VERSION ""

NS_ :

BS_:

BU_: PowertrainControlModule AtmosphericSensor SafetyRestraintSystem2 Aftertreatment_2_GasOutlet Aftertreatment_2_GasIntake DieselParticulateFilterControl Turbocharger SafetyRestraintSystem1 CabDisplay2 Aftertreatment_1_GasOutlet Aftertreatment_1_GasIntake OnBoardDataLogger OffBoardDiagnosticTool2 OffBoardDiagnosticTool1 FileServer ParkingBrakeController SeatController2 FanDriveController SteeringColumnUnit CommunicationUnitRadio CommunicationUnitSatellite CommunicationUnitCellular PropulsionBatteryCharger ChassisController2 ChassisController1 EngineValveControl AuxiliaryHeater2 AuxiliaryHeater1 ClutchUnit RampControl InformationSystem1 SuspensionSystemController2 OilSensor VehicleDynamicStability ExhaustEmissionController TransmissionDisplay2 TransmissionDisplay1 ClimateControl2 WaterPumpController RearAxleSteeringController LightingOperatorControl SeatController1 IgnitionController2 IgnitionController1 TirePressureController CabController2 CabController1 PneumaticSystemController SuspensionSystemController1 HydraulicPumpController EnduranceBrakingSystem RetarderExhaustEngine2 OnBoardDiagnosticUnit HeadwayController RetarderExhaustEngine1 CabDisplay1 ManagementComputer VirtualTerminal OffVehicleGateway PowerTakeOffFront HitchControl AuxiliaryValveControl BodyController TractorTrailerBridge1 StarterSystem ElectricalSystem VehicleSecurity VehicleNavigation AerodynamicControl ElectricalChargingSystem ClimateControl1 TripRecorder InstrumentCluster SuspensionDriveAxle2 SuspensionDriveAxle1 SuspensionSteerAxle SteeringController FuelSystem CruiseControl RetarderDriveline RetarderEngine BrakesDriveAxle2 BrakesDriveAxle1 BrakesSystemController BrakesSteerAxle AxleDrive2 AxleDrive1 AxleSteering PowerTakeOff ShiftConsoleSecondary ShiftConsolePrimary Transmission2 Transmission1 Engine2 Engine1

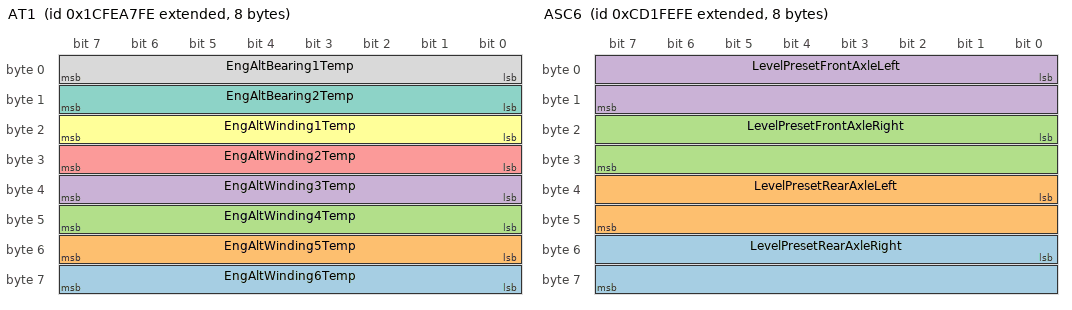
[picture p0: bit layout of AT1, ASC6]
BO_ 2633934846 AT1: 8 Vector__XXX
 SG_ EngAltWinding6Temp : 56|8@1+ (1,-40) [-40|210] "°C" Vector__XXX
 SG_ EngAltWinding5Temp : 48|8@1+ (1,-40) [-40|210] "°C" Vector__XXX
 SG_ EngAltWinding4Temp : 40|8@1+ (1,-40) [-40|210] "°C" Vector__XXX
 SG_ EngAltWinding3Temp : 32|8@1+ (1,-40) [-40|210] "°C" Vector__XXX
 SG_ EngAltWinding2Temp : 24|8@1+ (1,-40) [-40|210] "°C" Vector__XXX
 SG_ EngAltWinding1Temp : 16|8@1+ (1,-40) [-40|210] "°C" Vector__XXX
 SG_ EngAltBearing2Temp : 8|8@1+ (1,-40) [-40|210] "°C" Vector__XXX
 SG_ EngAltBearing1Temp : 0|8@1+ (1,-40) [-40|210] "°C" Vector__XXX

BO_ 2362572542 ASC6: 8 Vector__XXX
 SG_ LevelPresetRearAxleRight : 48|16@1+ (0.1,-3200) [-3200|3225.5] "mm" Vector__XXX
 SG_ LevelPresetRearAxleLeft : 32|16@1+ (0.1,-3200) [-3200|3225.5] "mm" Vector__XXX
 SG_ LevelPresetFrontAxleRight : 16|16@1+ (0.1,-3200) [-3200|3225.5] "mm" Vector__XXX
 SG_ LevelPresetFrontAxleLeft : 0|16@1+ (0.1,-3200) [-3200|3225.5] "mm" Vector__XXX

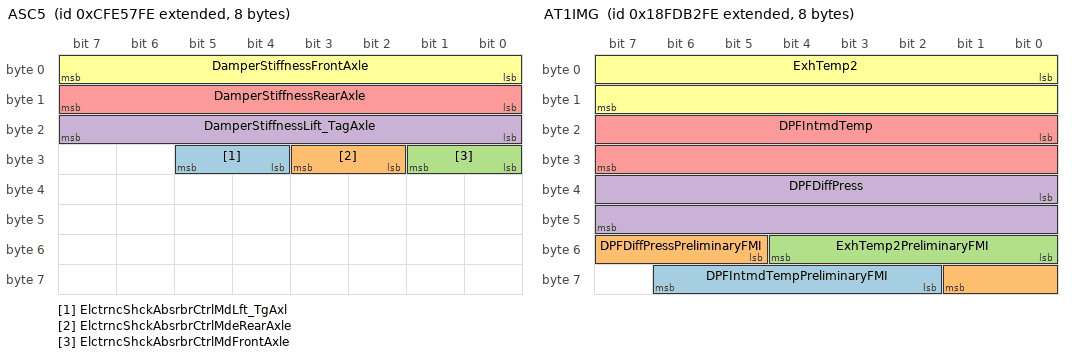
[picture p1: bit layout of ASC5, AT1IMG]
BO_ 2365478910 ASC5: 8 Vector__XXX
 SG_ ElctrncShckAbsrbrCtrlMdLft_TgAxl : 28|2@1+ (1,0) [0|3] "" Vector__XXX
 SG_ ElctrncShckAbsrbrCtrlMdeRearAxle : 26|2@1+ (1,0) [0|3] "" Vector__XXX
 SG_ ElctrncShckAbsrbrCtrlMdFrontAxle : 24|2@1+ (1,0) [0|3] "" Vector__XXX
 SG_ DamperStiffnessLift_TagAxle : 16|8@1+ (0.4,0) [0|100] "%" Vector__XXX
 SG_ DamperStiffnessRearAxle : 8|8@1+ (0.4,0) [0|100] "%" Vector__XXX
 SG_ DamperStiffnessFrontAxle : 0|8@1+ (0.4,0) [0|100] "%" Vector__XXX

BO_ 2560950014 DM30: 12 Vector__XXX
 SG_ SPN1 : 8|16@1+ (1,0) [0|65536] "" Vector__XXX
 SG_ TestLimitMinimum : 80|16@1+ (1,0) [0|64255] "" Vector__XXX
 SG_ FailureModeIdentifier1 : 24|5@1+ (1,0) [0|0] "" Vector__XXX
 SG_ TestLimitMaximum : 64|16@1+ (1,0) [0|64255] "" Vector__XXX
 SG_ TestValue : 48|16@1+ (1,0) [0|64255] "" Vector__XXX
 SG_ SlotId : 32|16@1+ (1,0) [0|64255] "" Vector__XXX
 SG_ TestIdentifier : 0|8@1+ (1,0) [0|255] "" Vector__XXX
 SG_ SPN1High : 29|3@1+ (1,0) [0|7] "" Vector__XXX

BO_ 2566763262 AT1IMG: 8 Vector__XXX
 SG_ DPFIntmdTempPreliminaryFMI : 58|5@1+ (1,0) [0|31] "" Vector__XXX
 SG_ DPFDiffPressPreliminaryFMI : 53|5@1+ (1,0) [0|31] "" Vector__XXX
 SG_ ExhTemp2PreliminaryFMI : 48|5@1+ (1,0) [0|31] "" Vector__XXX
 SG_ DPFDiffPress : 32|16@1+ (0.1,0) [0|6425.5] "kPa" Vector__XXX
 SG_ DPFIntmdTemp : 16|16@1+ (0.03125,-273) [-273|1734.96875] "°C" Vector__XXX
 SG_ ExhTemp2 : 0|16@1+ (0.03125,-273) [-273|1734.96875] "°C" Vector__XXX

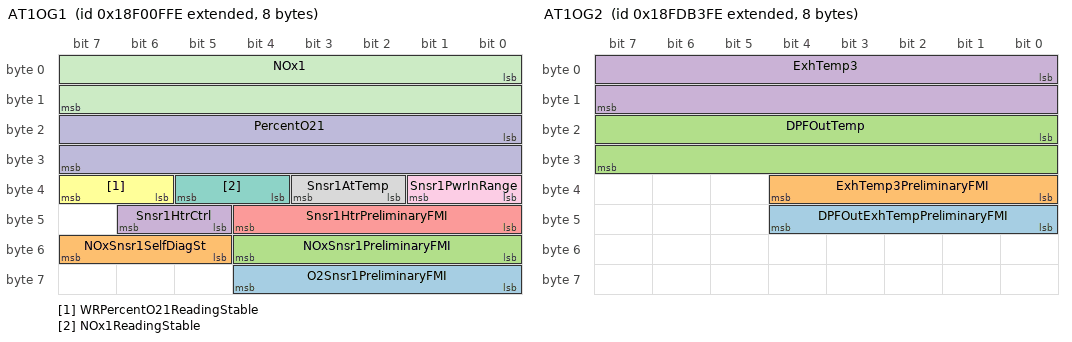
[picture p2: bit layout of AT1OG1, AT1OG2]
BO_ 2565869566 AT1OG1: 8 Vector__XXX
 SG_ O2Snsr1PreliminaryFMI : 56|5@1+ (1,0) [0|31] "" Vector__XXX
 SG_ NOxSnsr1SelfDiagSt : 53|3@1+ (1,0) [0|7] "" Vector__XXX
 SG_ NOxSnsr1PreliminaryFMI : 48|5@1+ (1,0) [0|31] "" Vector__XXX
 SG_ Snsr1HtrCtrl : 45|2@1+ (1,0) [0|3] "" Vector__XXX
 SG_ Snsr1HtrPreliminaryFMI : 40|5@1+ (1,0) [0|31] "" Vector__XXX
 SG_ WRPercentO21ReadingStable : 38|2@1+ (1,0) [0|3] "" Vector__XXX
 SG_ NOx1ReadingStable : 36|2@1+ (1,0) [0|3] "" Vector__XXX
 SG_ Snsr1AtTemp : 34|2@1+ (1,0) [0|3] "" Vector__XXX
 SG_ Snsr1PwrInRange : 32|2@1+ (1,0) [0|3] "" Vector__XXX
 SG_ PercentO21 : 16|16@1+ (0.000514,-12) [-12|21.02707] "%" Vector__XXX
 SG_ NOx1 : 0|16@1+ (0.05,-200) [-200|3012.75] "ppm" Vector__XXX

BO_ 2566763518 AT1OG2: 8 Vector__XXX
 SG_ DPFOutExhTempPreliminaryFMI : 40|5@1+ (1,0) [0|31] "" Vector__XXX
 SG_ ExhTemp3PreliminaryFMI : 32|5@1+ (1,0) [0|31] "" Vector__XXX
 SG_ DPFOutTemp : 16|16@1+ (0.03125,-273) [-273|1734.96875] "°C" Vector__XXX
 SG_ ExhTemp3 : 0|16@1+ (0.03125,-273) [-273|1734.96875] "°C" Vector__XXX

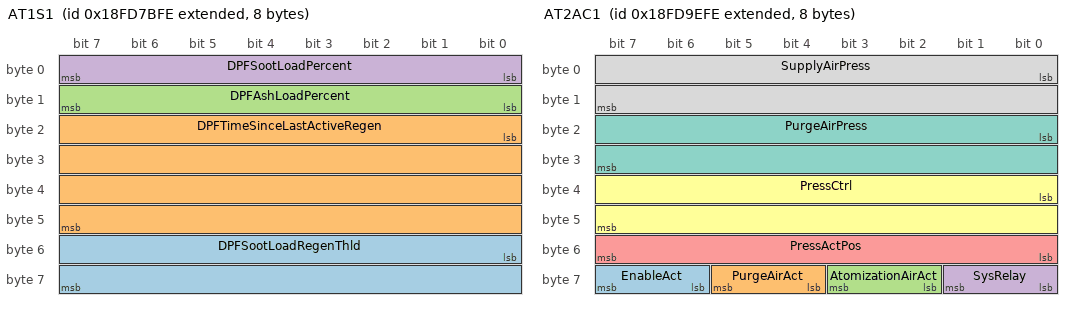
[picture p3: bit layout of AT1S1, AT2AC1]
BO_ 2566749182 AT1S1: 8 Vector__XXX
 SG_ DPFSootLoadRegenThld : 48|16@1+ (0.0025,0) [0|160.6375] "%" Vector__XXX
 SG_ DPFTimeSinceLastActiveRegen : 16|32@1+ (1,0) [0|4211081215] "s" Vector__XXX
 SG_ DPFAshLoadPercent : 8|8@1+ (1,0) [0|250] "%" Vector__XXX
 SG_ DPFSootLoadPercent : 0|8@1+ (1,0) [0|250] "%" Vector__XXX

BO_ 2566748670 AT1TI: 32 Vector__XXX
 SG_ DPFTripNumOfActiveRegenManReq : 224|32@1+ (1,0) [0|4211081215] "" Vector__XXX
 SG_ DPFTripNumOfActiveRegenInhReq : 192|32@1+ (1,0) [0|4211081215] "" Vector__XXX
 SG_ DPFTripNumOfPassiveRegens : 160|32@1+ (1,0) [0|4211081215] "" Vector__XXX
 SG_ DPFTripPassiveRegenTime : 128|32@1+ (1,0) [0|4211081215] "s" Vector__XXX
 SG_ DPFTripNumOfActiveRegens : 96|32@1+ (1,0) [0|4211081215] "" Vector__XXX
 SG_ DPFTripDisabledTime : 64|32@1+ (1,0) [0|4211081215] "s" Vector__XXX
 SG_ DPFTripActiveRegenTime : 32|32@1+ (1,0) [0|4211081215] "s" Vector__XXX
 SG_ DPFTripFuelUsed : 0|32@1+ (0.5,0) [0|2105540607.5] "l" Vector__XXX

BO_ 2566758142 AT2AC1: 8 Vector__XXX
 SG_ EnableAct : 62|2@1+ (1,0) [0|3] "" Vector__XXX
 SG_ PurgeAirAct : 60|2@1+ (1,0) [0|3] "" Vector__XXX
 SG_ AtomizationAirAct : 58|2@1+ (1,0) [0|3] "" Vector__XXX
 SG_ SysRelay : 56|2@1+ (1,0) [0|3] "" Vector__XXX
 SG_ PressActPos : 48|8@1+ (0.4,0) [0|100] "%" Vector__XXX
 SG_ PressCtrl : 32|16@1+ (0.0025,0) [0|160.6375] "%" Vector__XXX
 SG_ PurgeAirPress : 16|16@1+ (0.1,0) [0|6425.5] "kPa" Vector__XXX
 SG_ SupplyAirPress : 0|16@1+ (0.1,0) [0|6425.5] "kPa" Vector__XXX

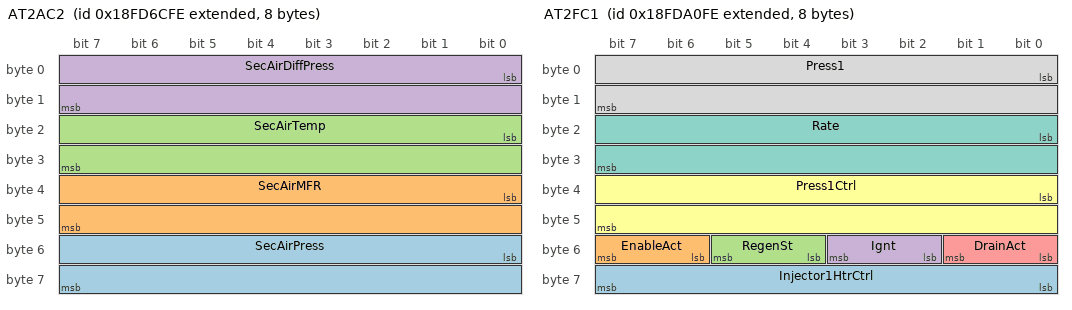
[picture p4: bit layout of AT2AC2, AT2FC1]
BO_ 2566745342 AT2AC2: 8 Vector__XXX
 SG_ SecAirPress : 48|16@1+ (0.1,0) [0|6425.5] "kPa" Vector__XXX
 SG_ SecAirMFR : 32|16@1+ (0.2,0) [0|12851] "kg/h" Vector__XXX
 SG_ SecAirTemp : 16|16@1+ (0.03125,-273) [-273|1734.96875] "°C" Vector__XXX
 SG_ SecAirDiffPress : 0|16@1+ (0.0078125,-250) [-250|251.9921875] "kPa" Vector__XXX

BO_ 2566758654 AT2FC1: 8 Vector__XXX
 SG_ Injector1HtrCtrl : 56|8@1+ (0.4,0) [0|100] "%" Vector__XXX
 SG_ EnableAct : 54|2@1+ (1,0) [0|3] "" Vector__XXX
 SG_ RegenSt : 52|2@1+ (1,0) [0|3] "" Vector__XXX
 SG_ Ignt : 50|2@1+ (1,0) [0|3] "" Vector__XXX
 SG_ DrainAct : 48|2@1+ (1,0) [0|3] "" Vector__XXX
 SG_ Press1Ctrl : 32|16@1+ (0.0025,0) [0|160.6375] "%" Vector__XXX
 SG_ Rate : 16|16@1+ (0.05,0) [0|3212.75] "l/h" Vector__XXX
 SG_ Press1 : 0|16@1+ (0.1,0) [0|6425.5] "kPa" Vector__XXX

BO_ 2566753278 AT2GP: 8 Vector__XXX
 SG_ DPFOutPress : 16|16@1+ (0.1,0) [0|6425.5] "kPa" Vector__XXX
 SG_ DPFInPress : 0|16@1+ (0.1,0) [0|6425.5] "kPa" Vector__XXX

BO_ 2566756862 AT2HI1: 40 Vector__XXX
 SG_ DPFAvgDistBetweenActiveRegens : 288|32@1+ (0.125,0) [0|526385151.875] "km" Vector__XXX
 SG_ DPFAvgTimeBetweenActiveRegens : 256|32@1+ (1,0) [0|4211081215] "s" Vector__XXX
 SG_ DPFTotalNumOfActiveRegenManReq : 224|32@1+ (1,0) [0|4211081215] "" Vector__XXX
 SG_ DPFTotalNumOfActiveRegenInhReq : 192|32@1+ (1,0) [0|4211081215] "" Vector__XXX
 SG_ DPFTotalNumOfPassiveRegens : 160|32@1+ (1,0) [0|4211081215] "" Vector__XXX
 SG_ DPFTotalPassiveRegenTime : 128|32@1+ (1,0) [0|4211081215] "s" Vector__XXX
 SG_ TotalNumOfActiveRegens : 96|32@1+ (1,0) [0|4211081215] "" Vector__XXX
 SG_ TotalDisabledTime : 64|32@1+ (1,0) [0|4211081215] "s" Vector__XXX
 SG_ TotalRegenTime : 32|32@1+ (1,0) [0|4211081215] "s" Vector__XXX
 SG_ TotalFuelUsed : 0|32@1+ (0.5,0) [0|2105540607.5] "l" Vector__XXX

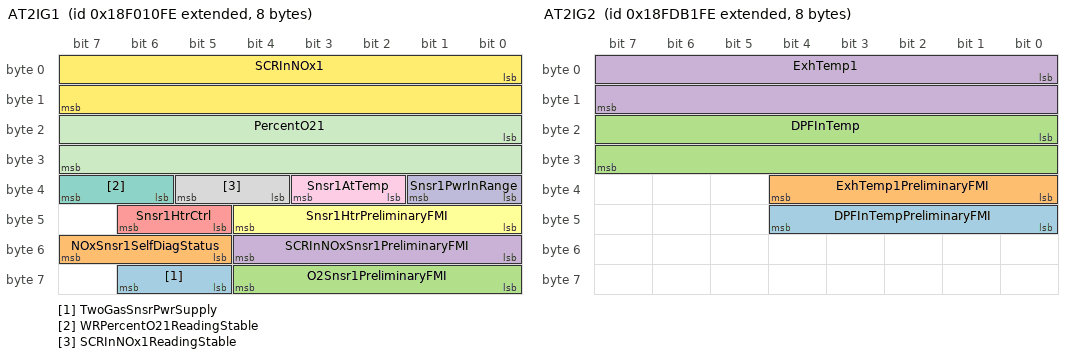
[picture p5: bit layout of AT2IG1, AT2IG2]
BO_ 2565869822 AT2IG1: 8 Vector__XXX
 SG_ TwoGasSnsrPwrSupply : 61|2@1+ (1,0) [0|3] "" Vector__XXX
 SG_ NOxSnsr1SelfDiagStatus : 53|3@1+ (1,0) [0|7] "" Vector__XXX
 SG_ O2Snsr1PreliminaryFMI : 56|5@1+ (1,0) [0|31] "" Vector__XXX
 SG_ SCRInNOxSnsr1PreliminaryFMI : 48|5@1+ (1,0) [0|31] "" Vector__XXX
 SG_ Snsr1HtrCtrl : 45|2@1+ (1,0) [0|3] "" Vector__XXX
 SG_ Snsr1HtrPreliminaryFMI : 40|5@1+ (1,0) [0|31] "" Vector__XXX
 SG_ WRPercentO21ReadingStable : 38|2@1+ (1,0) [0|3] "" Vector__XXX
 SG_ SCRInNOx1ReadingStable : 36|2@1+ (1,0) [0|3] "" Vector__XXX
 SG_ Snsr1AtTemp : 34|2@1+ (1,0) [0|3] "" Vector__XXX
 SG_ Snsr1PwrInRange : 32|2@1+ (1,0) [0|3] "" Vector__XXX
 SG_ PercentO21 : 16|16@1+ (0.000514,-12) [-12|21.02707] "%" Vector__XXX
 SG_ SCRInNOx1 : 0|16@1+ (0.05,-200) [-200|3012.75] "ppm" Vector__XXX

BO_ 2566763006 AT2IG2: 8 Vector__XXX
 SG_ DPFInTempPreliminaryFMI : 40|5@1+ (1,0) [0|31] "" Vector__XXX
 SG_ ExhTemp1PreliminaryFMI : 32|5@1+ (1,0) [0|31] "" Vector__XXX
 SG_ DPFInTemp : 16|16@1+ (0.03125,-273) [-273|1734.96875] "°C" Vector__XXX
 SG_ ExhTemp1 : 0|16@1+ (0.03125,-273) [-273|1734.96875] "°C" Vector__XXX

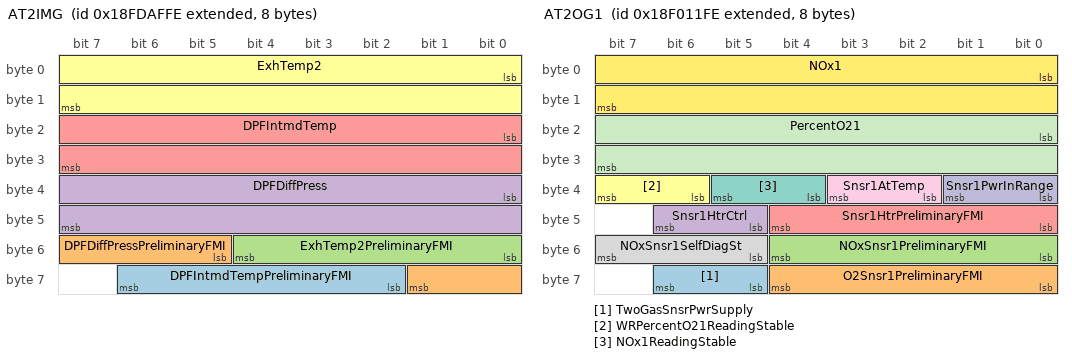
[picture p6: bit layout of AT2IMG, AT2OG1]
BO_ 2566762494 AT2IMG: 8 Vector__XXX
 SG_ DPFIntmdTempPreliminaryFMI : 58|5@1+ (1,0) [0|31] "" Vector__XXX
 SG_ DPFDiffPressPreliminaryFMI : 53|5@1+ (1,0) [0|31] "" Vector__XXX
 SG_ ExhTemp2PreliminaryFMI : 48|5@1+ (1,0) [0|31] "" Vector__XXX
 SG_ DPFDiffPress : 32|16@1+ (0.1,0) [0|6425.5] "kPa" Vector__XXX
 SG_ DPFIntmdTemp : 16|16@1+ (0.03125,-273) [-273|1734.96875] "°C" Vector__XXX
 SG_ ExhTemp2 : 0|16@1+ (0.03125,-273) [-273|1734.96875] "°C" Vector__XXX

BO_ 2565870078 AT2OG1: 8 Vector__XXX
 SG_ TwoGasSnsrPwrSupply : 61|2@1+ (1,0) [0|3] "" Vector__XXX
 SG_ O2Snsr1PreliminaryFMI : 56|5@1+ (1,0) [0|31] "" Vector__XXX
 SG_ NOxSnsr1PreliminaryFMI : 48|5@1+ (1,0) [0|31] "" Vector__XXX
 SG_ Snsr1HtrCtrl : 45|2@1+ (1,0) [0|3] "" Vector__XXX
 SG_ Snsr1HtrPreliminaryFMI : 40|5@1+ (1,0) [0|31] "" Vector__XXX
 SG_ WRPercentO21ReadingStable : 38|2@1+ (1,0) [0|3] "" Vector__XXX
 SG_ NOx1ReadingStable : 36|2@1+ (1,0) [0|3] "" Vector__XXX
 SG_ NOxSnsr1SelfDiagSt : 53|3@1+ (1,0) [0|7] "" Vector__XXX
 SG_ Snsr1AtTemp : 34|2@1+ (1,0) [0|3] "" Vector__XXX
 SG_ Snsr1PwrInRange : 32|2@1+ (1,0) [0|3] "" Vector__XXX
 SG_ PercentO21 : 16|16@1+ (0.000514,-12) [-12|21.02707] "%" Vector__XXX
 SG_ NOx1 : 0|16@1+ (0.05,-200) [-200|3012.75] "ppm" Vector__XXX

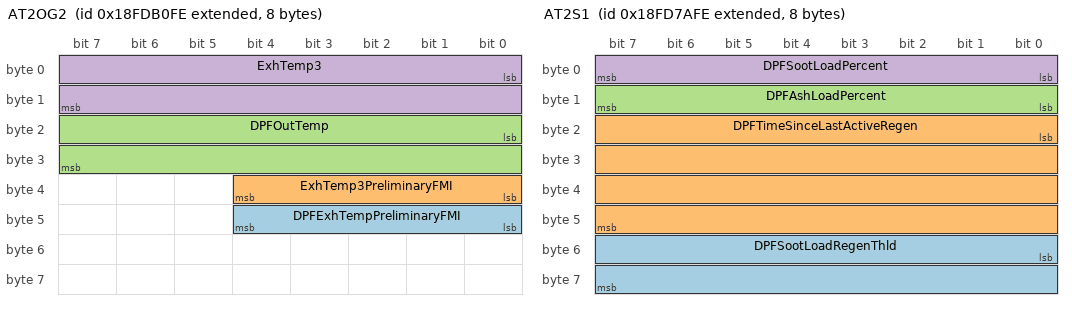
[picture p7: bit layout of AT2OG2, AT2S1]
BO_ 2566762750 AT2OG2: 8 Vector__XXX
 SG_ DPFExhTempPreliminaryFMI : 40|5@1+ (1,0) [0|31] "" Vector__XXX
 SG_ ExhTemp3PreliminaryFMI : 32|5@1+ (1,0) [0|31] "" Vector__XXX
 SG_ DPFOutTemp : 16|16@1+ (0.03125,-273) [-273|1734.96875] "°C" Vector__XXX
 SG_ ExhTemp3 : 0|16@1+ (0.03125,-273) [-273|1734.96875] "°C" Vector__XXX

BO_ 2566748926 AT2S1: 8 Vector__XXX
 SG_ DPFSootLoadRegenThld : 48|16@1+ (0.0025,0) [0|160.6375] "%" Vector__XXX
 SG_ DPFTimeSinceLastActiveRegen : 16|32@1+ (1,0) [0|4211081215] "s" Vector__XXX
 SG_ DPFAshLoadPercent : 8|8@1+ (1,0) [0|250] "%" Vector__XXX
 SG_ DPFSootLoadPercent : 0|8@1+ (1,0) [0|250] "%" Vector__XXX

BO_ 2566748414 AT2TI: 32 Vector__XXX
 SG_ DPFTripNumOfActiveRegenManReq : 224|32@1+ (1,0) [0|4211081215] "" Vector__XXX
 SG_ DPFTripNumOfActiveRegenInhReq : 192|32@1+ (1,0) [0|4211081215] "" Vector__XXX
 SG_ DPFTripNumOfPassiveRegens : 160|32@1+ (1,0) [0|4211081215] "" Vector__XXX
 SG_ DPFTripPassiveRegenTime : 128|32@1+ (1,0) [0|4211081215] "s" Vector__XXX
 SG_ DPFTripNumOfActiveRegens : 96|32@1+ (1,0) [0|4211081215] "" Vector__XXX
 SG_ DPFTripDisabledTime : 64|32@1+ (1,0) [0|4211081215] "s" Vector__XXX
 SG_ DPFTripActiveRegenTime : 32|32@1+ (1,0) [0|4211081215] "s" Vector__XXX
 SG_ DPFTripFuelUsed : 0|32@1+ (0.5,0) [0|2105540607.5] "l" Vector__XXX

BO_ 2365428478 EOI: 8 Vector__XXX
 SG_ EngDesiredTorqueRq : 48|8@1+ (1,-125) [0|125] "%" Vector__XXX
 SG_ EngColdAmbientElevatedIdleStatus : 46|2@1+ (1,0) [0|3] "" Vector__XXX
 SG_ EngStarterMotorRelayCtrl : 6|2@1+ (1,0) [0|3] "" Vector__XXX
 SG_ EngDerateRq : 56|8@1+ (0.4,0) [0|100] "%" Vector__XXX
 SG_ EngEmergencyShutdownIndication : 44|2@1+ (1,0) [0|3] "" Vector__XXX
 SG_ EngControlledShutdownRq : 42|2@1+ (1,0) [0|3] "" Vector__XXX
 SG_ EngCoolantCirculatingPumpCtrl : 40|2@1+ (1,0) [0|3] "" Vector__XXX
 SG_ EngBlock_CoolantPreheaterCtrl : 38|2@1+ (1,0) [0|3] "" Vector__XXX
 SG_ EngElctrclSystmPwrCnsrvationCtrl : 36|2@1+ (1,0) [0|3] "" Vector__XXX
 SG_ EngOilPreheaterCtrl : 34|2@1+ (1,0) [0|3] "" Vector__XXX
 SG_ EngOilPrimingPumpCtrl : 32|2@1+ (1,0) [0|3] "" Vector__XXX
 SG_ EngFuelShutoffValveLeakTestCtrl : 30|2@1+ (1,0) [0|3] "" Vector__XXX
 SG_ EngFuelShutoff2Ctrl : 28|2@1+ (1,0) [0|3] "" Vector__XXX
 SG_ EngFuelShutoff1Ctrl : 26|2@1+ (1,0) [0|3] "" Vector__XXX
 SG_ EngFuelShutoffVentCtrl : 24|2@1+ (1,0) [0|3] "" Vector__XXX
 SG_ TimeRemainingInEngOperatingState : 8|16@1+ (1,0) [0|64255] "s" Vector__XXX
 SG_ FuelPumpPrimerCtrl : 4|2@1+ (1,0) [0|3] "" Vector__XXX
 SG_ EngOperatingState : 0|4@1+ (1,0) [0|15] "" Vector__XXX

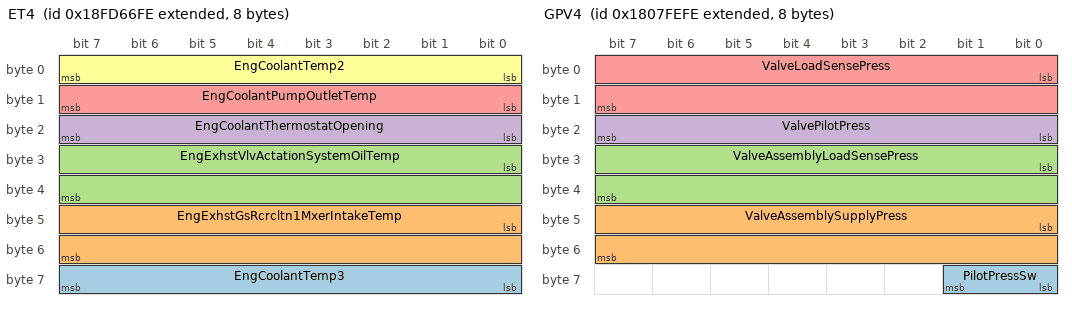
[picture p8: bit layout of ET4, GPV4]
BO_ 2566743806 ET4: 8 Vector__XXX
 SG_ EngCoolantTemp3 : 56|8@1+ (1,-40) [-40|210] "°C" Vector__XXX
 SG_ EngExhstGsRcrcltn1MxerIntakeTemp : 40|16@1+ (0.03125,-273) [-273|1734.96875] "°C" Vector__XXX
 SG_ EngExhstVlvActationSystemOilTemp : 24|16@1+ (0.03125,-273) [-273|1734.96875] "°C" Vector__XXX
 SG_ EngCoolantThermostatOpening : 16|8@1+ (0.4,0) [0|100] "%" Vector__XXX
 SG_ EngCoolantPumpOutletTemp : 8|8@1+ (1,-40) [-40|210] "°C" Vector__XXX
 SG_ EngCoolantTemp2 : 0|8@1+ (1,-40) [-40|210] "°C" Vector__XXX

BO_ 2499635454 GCVW: 8 Vector__XXX
 SG_ NetVehicleWeightChange : 24|24@1+ (2,-16449535) [-16449535|16449535] "kg" Vector__XXX
 SG_ GrossCombinationWeight : 0|24@1+ (2,0) [0|32899070] "kg" Vector__XXX

BO_ 2550660862 GPV4: 8 Vector__XXX
 SG_ PilotPressSw : 56|2@1+ (1,0) [0|3] "" Vector__XXX
 SG_ ValveAssemblySupplyPress : 40|16@1+ (5,0) [0|321275] "kPa" Vector__XXX
 SG_ ValveAssemblyLoadSensePress : 24|16@1+ (5,0) [0|321275] "kPa" Vector__XXX
 SG_ ValvePilotPress : 16|8@1+ (16,0) [0|4000] "kPa" Vector__XXX
 SG_ ValveLoadSensePress : 0|16@1+ (5,0) [0|321275] "kPa" Vector__XXX

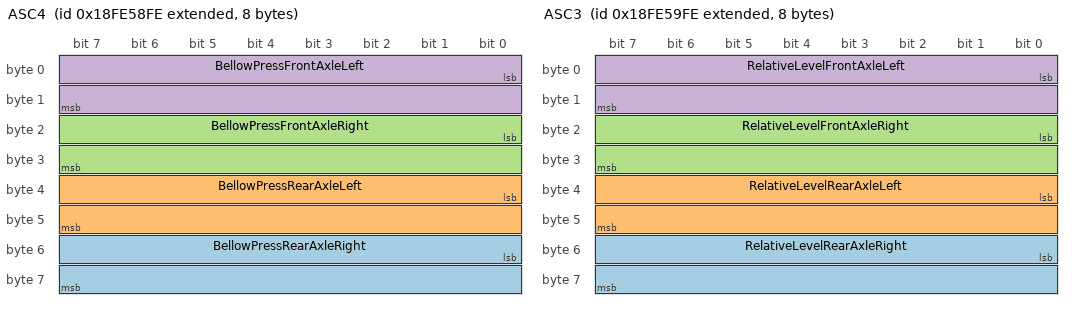
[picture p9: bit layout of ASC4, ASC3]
BO_ 2566805758 ASC4: 8 Vector__XXX
 SG_ BellowPressRearAxleRight : 48|16@1+ (0.1,0) [0|6425.5] "kPa" Vector__XXX
 SG_ BellowPressRearAxleLeft : 32|16@1+ (0.1,0) [0|6425.5] "kPa" Vector__XXX
 SG_ BellowPressFrontAxleRight : 16|16@1+ (0.1,0) [0|6425.5] "kPa" Vector__XXX
 SG_ BellowPressFrontAxleLeft : 0|16@1+ (0.1,0) [0|6425.5] "kPa" Vector__XXX

BO_ 2566806014 ASC3: 8 Vector__XXX
 SG_ RelativeLevelRearAxleRight : 48|16@1+ (0.1,-3200) [-3200|3225.5] "mm" Vector__XXX
 SG_ RelativeLevelRearAxleLeft : 32|16@1+ (0.1,-3200) [-3200|3225.5] "mm" Vector__XXX
 SG_ RelativeLevelFrontAxleRight : 16|16@1+ (0.1,-3200) [-3200|3225.5] "mm" Vector__XXX
 SG_ RelativeLevelFrontAxleLeft : 0|16@1+ (0.1,-3200) [-3200|3225.5] "mm" Vector__XXX

BO_ 2362638078 ASC2: 8 Vector__XXX
 SG_ MemoryLevelRq : 60|4@1+ (1,0) [0|15] "" Vector__XXX
 SG_ PrhbitAutomaticAirSuspensionCtrl : 58|2@1+ (1,0) [0|3] "" Vector__XXX
 SG_ SpeedDependentLevelCtrlRq : 56|2@1+ (1,0) [0|3] "" Vector__XXX
 SG_ AllowLevelCtrlDuringBrakingCmd : 54|2@1+ (1,0) [0|3] "" Vector__XXX
 SG_ ProhibitAirSuspensionCtrl : 52|2@1+ (1,0) [0|3] "" Vector__XXX
 SG_ KneelingCmdRearAxle : 50|2@1+ (1,0) [0|3] "" Vector__XXX
 SG_ KneelingCmdFrontAxle : 48|2@1+ (1,0) [0|3] "" Vector__XXX
 SG_ DamperStiffnessRqLift_TagAxle : 40|8@1+ (0.4,0) [0|100] "%" Vector__XXX
 SG_ DamperStiffnessRqRearAxle : 32|8@1+ (0.4,0) [0|100] "%" Vector__XXX
 SG_ DamperStiffnessRqFrontAxle : 24|8@1+ (0.4,0) [0|100] "%" Vector__XXX
 SG_ LiftAxle2PosCmd : 22|2@1+ (1,0) [0|3] "" Vector__XXX
 SG_ LiftAxle1PosCmd : 20|2@1+ (1,0) [0|3] "" Vector__XXX
 SG_ LevelCtrlModeRq : 16|4@1+ (1,0) [0|15] "" Vector__XXX
 SG_ NominalLevelRqRearAxle : 12|4@1+ (1,0) [0|15] "" Vector__XXX
 SG_ NominalLevelRqFrontAxle : 8|4@1+ (1,0) [0|15] "" Vector__XXX
 SG_ KneelingCtrlModeRq : 6|2@1+ (1,0) [0|3] "" Vector__XXX
 SG_ KneelingRqRightSide : 4|2@1+ (1,0) [0|3] "" Vector__XXX
 SG_ KneelingRqLeftSide : 2|2@1+ (1,0) [0|3] "" Vector__XXX
 SG_ AutomaticTractionHelp : 0|2@1+ (1,0) [0|3] "" Vector__XXX

BO_ 2365479678 ASC1: 8 Vector__XXX
 SG_ MemoryLevel : 60|4@1+ (1,0) [0|15] "" Vector__XXX
 SG_ SuspensionCtrlRefusalInformation : 56|4@1+ (1,0) [0|15] "" Vector__XXX
 SG_ SpeedDependantLevelCtrlStatus : 54|2@1+ (1,0) [0|3] "" Vector__XXX
 SG_ AllwLevelCtrlDuringBrakingStatus : 52|2@1+ (1,0) [0|3] "" Vector__XXX
 SG_ SuspensionRemoteCtrl2 : 50|2@1+ (1,0) [0|3] "" Vector__XXX
 SG_ SuspensionRemoteCtrl1 : 48|2@1+ (1,0) [0|3] "" Vector__XXX
 SG_ LiftAxle2Pos : 46|2@1+ (1,0) [0|3] "" Vector__XXX
 SG_ RearAxleInBumperRange : 42|2@1+ (1,0) [0|3] "" Vector__XXX
 SG_ FrontAxleInBumperRange : 40|2@1+ (1,0) [0|3] "" Vector__XXX
 SG_ LiftAxle1Pos : 38|2@1+ (1,0) [0|3] "" Vector__XXX
 SG_ DoorRelease : 36|2@1+ (1,0) [0|3] "" Vector__XXX
 SG_ VehicleMotionInhibit : 34|2@1+ (1,0) [0|3] "" Vector__XXX
 SG_ SecurityDevice : 32|2@1+ (1,0) [0|3] "" Vector__XXX
 SG_ LevelCtrlMode : 28|4@1+ (1,0) [0|15] "" Vector__XXX
 SG_ KneelingInformation : 24|4@1+ (1,0) [0|15] "" Vector__XXX
 SG_ LiftingCtrlModeRearAxle : 22|2@1+ (1,0) [0|3] "" Vector__XXX
 SG_ LiftingCtrlModeFrontAxle : 20|2@1+ (1,0) [0|3] "" Vector__XXX
 SG_ LoweringCtrlModeRearAxle : 18|2@1+ (1,0) [0|3] "" Vector__XXX
 SG_ LoweringCtrlModeFrontAxle : 16|2@1+ (1,0) [0|3] "" Vector__XXX
 SG_ AboveNominalLevelRearAxle : 14|2@1+ (1,0) [0|3] "" Vector__XXX
 SG_ AboveNominalLevelFrontAxle : 12|2@1+ (1,0) [0|3] "" Vector__XXX
 SG_ BelowNominalLevelRearAxle : 10|2@1+ (1,0) [0|3] "" Vector__XXX
 SG_ BelowNominalLevelFrontAxle : 8|2@1+ (1,0) [0|3] "" Vector__XXX
 SG_ NominalLevelRearAxle : 4|4@1+ (1,0) [0|15] "" Vector__XXX
 SG_ NominalLevelFrontAxle : 0|4@1+ (1,0) [0|15] "" Vector__XXX

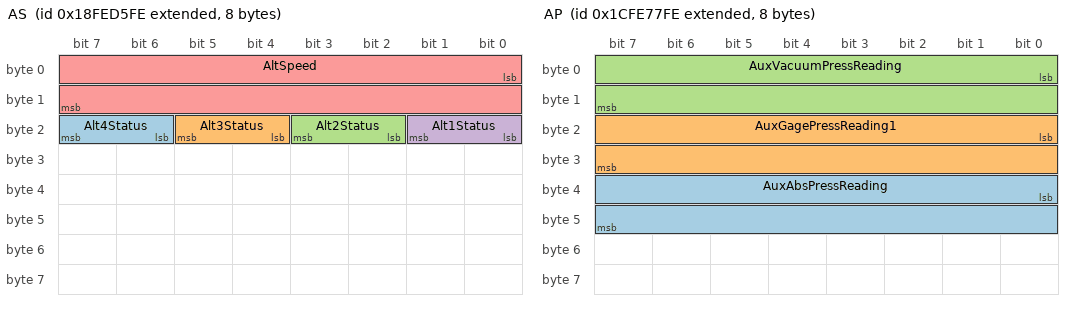
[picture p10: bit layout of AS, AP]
BO_ 2566837758 AS: 8 Vector__XXX
 SG_ Alt4Status : 22|2@1+ (1,0) [0|3] "" Vector__XXX
 SG_ Alt3Status : 20|2@1+ (1,0) [0|3] "" Vector__XXX
 SG_ Alt2Status : 18|2@1+ (1,0) [0|3] "" Vector__XXX
 SG_ Alt1Status : 16|2@1+ (1,0) [0|3] "" Vector__XXX
 SG_ AltSpeed : 0|16@1+ (0.5,0) [0|32127.5] "rpm" Vector__XXX

BO_ 2633922558 AP: 8 Vector__XXX
 SG_ AuxAbsPressReading : 32|16@1+ (0.5,0) [0|32127.5] "kPa" Vector__XXX
 SG_ AuxGagePressReading1 : 16|16@1+ (0.5,0) [0|32127.5] "kPa" Vector__XXX
 SG_ AuxVacuumPressReading : 0|16@1+ (0.5,0) [0|32127.5] "kPa" Vector__XXX

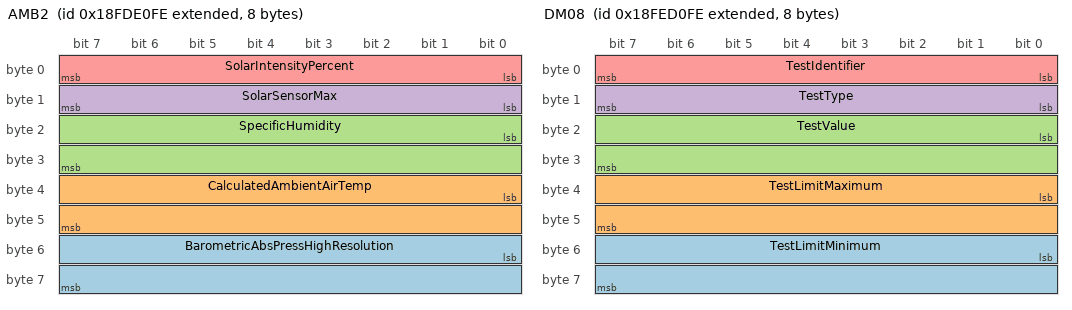
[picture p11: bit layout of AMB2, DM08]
BO_ 2566775038 AMB2: 8 Vector__XXX
 SG_ BarometricAbsPressHighResolution : 48|16@1+ (0.1,0) [0|6425.5] "kPa" Vector__XXX
 SG_ CalculatedAmbientAirTemp : 32|16@1+ (0.03125,-273) [-273|1734.96875] "°C" Vector__XXX
 SG_ SpecificHumidity : 16|16@1+ (0.01,0) [0|642.55] "g/kg" Vector__XXX
 SG_ SolarSensorMax : 8|8@1+ (0.4,0) [0|100] "mW/cm²" Vector__XXX
 SG_ SolarIntensityPercent : 0|8@1+ (0.4,0) [0|100] "%" Vector__XXX

BO_ 2566836478 DM08: 8 Vector__XXX
 SG_ TestLimitMinimum : 48|16@1+ (1,0) [0|0] "" Vector__XXX
 SG_ TestLimitMaximum : 32|16@1+ (1,0) [0|0] "" Vector__XXX
 SG_ TestValue : 16|16@1+ (1,0) [0|0] "" Vector__XXX
 SG_ TestType : 8|8@1+ (1,0) [0|250] "" Vector__XXX
 SG_ TestIdentifier : 0|8@1+ (1,0) [0|255] "" Vector__XXX

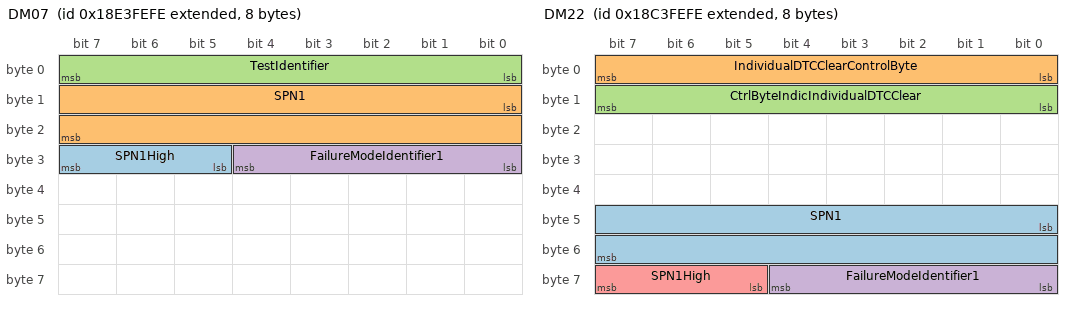
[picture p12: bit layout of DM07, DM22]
BO_ 2565078782 DM07: 8 Vector__XXX
 SG_ SPN1High : 29|3@1+ (1,0) [0|7] "" Vector__XXX
 SG_ SPN1 : 8|16@1+ (1,0) [0|524287] "" Vector__XXX
 SG_ TestIdentifier : 0|8@1+ (1,0) [0|255] "" Vector__XXX
 SG_ FailureModeIdentifier1 : 24|5@1+ (1,0) [0|31] "" Vector__XXX

BO_ 2566836222 DM06: 22 Vector__XXX
 SG_ FlashRedStopLamp : 12|2@1+ (1,0) [0|3] "" Vector__XXX
 SG_ FlashProtectLamp : 8|2@1+ (1,0) [0|3] "" Vector__XXX
 SG_ FlashMalfuncIndicatorLamp : 14|2@1+ (1,0) [0|3] "" Vector__XXX
 SG_ FlashAmberWarningLamp : 10|2@1+ (1,0) [0|3] "" Vector__XXX
 SG_ MalfunctionIndicatorLampStatus : 6|2@1+ (1,0) [0|3] "" Vector__XXX
 SG_ RedStopLampState : 4|2@1+ (1,0) [0|3] "" Vector__XXX
 SG_ AmberWarningLampStatus : 2|2@1+ (1,0) [0|3] "" Vector__XXX
 SG_ ProtectLampStatus : 0|2@1+ (1,0) [0|3] "" Vector__XXX
 SG_ DTC5 : 144|32@1+ (1,0) [0|4294967295] "" Vector__XXX
 SG_ DTC4 : 112|32@1+ (1,0) [0|4294967295] "" Vector__XXX
 SG_ DTC3 : 80|32@1+ (1,0) [0|4294967295] "" Vector__XXX
 SG_ DTC2 : 48|32@1+ (1,0) [0|4294967295] "" Vector__XXX
 SG_ DTC1 : 16|32@1+ (1,0) [0|4294967295] "" Vector__XXX

BO_ 2566835966 DM05: 8 Vector__XXX
 SG_ BoostPressureControlSystemStatus : 57|1@1- (1,0) [0|0] "" Vector__XXX
 SG_ DieselParticulateFilterStatus : 58|1@1- (1,0) [0|0] "" Vector__XXX
 SG_ NOxConvertingCatalystAdsorberSta : 59|1@1- (1,0) [0|0] "" Vector__XXX
 SG_ NMHCConvertingCatalystStatus : 60|1@1- (1,0) [0|0] "" Vector__XXX
 SG_ BoostPressureControlSystemSuppor : 41|1@1- (1,0) [0|0] "" Vector__XXX
 SG_ DieselParticulateFilterSupport : 42|1@1- (1,0) [0|0] "" Vector__XXX
 SG_ NOxConvertingCatalystAdsorberSup : 43|1@1- (1,0) [0|0] "" Vector__XXX
 SG_ NMHCConvertingCatalystSupport : 44|1@1- (1,0) [0|0] "" Vector__XXX
 SG_ MisfireMonitoringSupport : 24|1@1+ (1,0) [0|0] "" Vector__XXX
 SG_ OBDCompliance : 16|8@1+ (1,0) [0|250] "" Vector__XXX
 SG_ PreviouslyActiveTroubleCodes : 8|8@1+ (1,0) [0|250] "" Vector__XXX
 SG_ ActiveTroubleCodes : 0|8@1+ (1,0) [0|250] "" Vector__XXX
 SG_ SecondAirSystemMonStatus : 51|1@1+ (1,0) [0|1] "" Vector__XXX
 SG_ EvaporativeSystemMonStatus : 50|1@1+ (1,0) [0|1] "" Vector__XXX
 SG_ ACSystemRefrigerantMonStatus : 52|1@1+ (1,0) [0|1] "" Vector__XXX
 SG_ OxygenSensorHeaterMonStatus : 54|1@1+ (1,0) [0|1] "" Vector__XXX
 SG_ OxygenSensorMonStatus : 53|1@1+ (1,0) [0|1] "" Vector__XXX
 SG_ EGRSystemMonitoringStatus : 55|1@1+ (1,0) [0|1] "" Vector__XXX
 SG_ CatalystMonStatus : 48|1@1+ (1,0) [0|1] "" Vector__XXX
 SG_ ColdStartAidSystemMonStatus : 56|1@1+ (1,0) [0|1] "" Vector__XXX
 SG_ HeatedCatalystMonStatus : 49|1@1+ (1,0) [0|0] "" Vector__XXX
 SG_ CatalystMonSupp : 32|1@1+ (1,0) [0|1] "" Vector__XXX
 SG_ ColdStartAidSystemMonSupp : 40|1@1+ (1,0) [0|1] "" Vector__XXX
 SG_ HeatedCatalystMonSupp : 33|1@1+ (1,0) [0|0] "" Vector__XXX
 SG_ EvaporativeSystemMonSupp : 34|1@1+ (1,0) [0|1] "" Vector__XXX
 SG_ SecondAirSystemMonSupp : 35|1@1+ (1,0) [0|1] "" Vector__XXX
 SG_ ACSystemRefrigerantMonSupp : 36|1@1+ (1,0) [0|1] "" Vector__XXX
 SG_ OxygenSensorMonSupp : 37|1@1+ (1,0) [0|1] "" Vector__XXX
 SG_ OxygenSensorHeaterMonSupp : 38|1@1+ (1,0) [0|1] "" Vector__XXX
 SG_ EGRSystemMonitoringSupp : 39|1@1+ (1,0) [0|1] "" Vector__XXX
 SG_ MisfireMonitoringStatus : 28|1@1+ (1,0) [0|0] "" Vector__XXX
 SG_ ComprehensiveCompMonStatus : 30|1@1+ (1,0) [0|1] "" Vector__XXX
 SG_ FuelSystemMonitoringStatus : 29|1@1+ (1,0) [0|1] "" Vector__XXX
 SG_ ComprehensiveComponentMonSupp : 26|1@1+ (1,0) [0|0] "" Vector__XXX
 SG_ FuelSystemMonitoringSupport : 25|1@1+ (1,0) [0|1] "" Vector__XXX

BO_ 2566835710 DM04: 13 Vector__XXX
 SG_ EngIntakeManifold1Press : 48|8@1+ (2,0) [0|500] "kPa" Vector__XXX
 SG_ FreezeFrameLength : 0|8@1+ (1,0) [0|255] "" Vector__XXX
 SG_ EngSpeed : 56|16@1+ (0.125,0) [0|8031.875] "rpm" Vector__XXX
 SG_ EngTorqueMode : 40|4@1+ (1,0) [0|15] "" Vector__XXX
 SG_ WheelBasedVehicleSpeed : 88|16@1+ (0.00390625,0) [0|250.99609375] "km/h" Vector__XXX
 SG_ EngPercentLoadAtCurrentSpeed : 72|8@1+ (1,0) [0|125] "%" Vector__XXX
 SG_ EngCoolantTemp : 80|8@1+ (1,-40) [-40|210] "°C" Vector__XXX
 SG_ DTC1 : 8|32@1+ (1,0) [0|4294967295] "" Vector__XXX

BO_ 2566835454 DM03: 0 Vector__XXX

BO_ 2566764542 DM25: 13 Vector__XXX
 SG_ ExpandedFreezeFrameLength : 0|8@1+ (1,0) [0|250] "bytes" Vector__XXX
 SG_ DTC1 : 8|32@1+ (1,0) [0|4294967295] "" Vector__XXX

BO_ 2566764286 DM24: 12 Vector__XXX
 SG_ SPNSupported1High : 21|3@1+ (1,0) [0|7] "" Vector__XXX
 SG_ SPNSupportTypeSTR3 : 82|1@1+ (1,0) [0|1] "" Vector__XXX
 SG_ SPNSupportTypeSTR2 : 50|1@1+ (1,0) [0|1] "" Vector__XXX
 SG_ SPNSupportTypeEFF3 : 80|1@1+ (1,0) [0|1] "" Vector__XXX
 SG_ SPNSupportTypeEFF2 : 48|1@1+ (1,0) [0|1] "" Vector__XXX
 SG_ SPNSupportTypeDS3 : 81|1@1+ (1,0) [0|1] "" Vector__XXX
 SG_ SPNSupportTypeDS2 : 49|1@1+ (1,0) [0|1] "" Vector__XXX
 SG_ SPNSupported3High : 85|3@1+ (1,0) [0|7] "" Vector__XXX
 SG_ SPNSupported2High : 53|3@1+ (1,0) [0|7] "" Vector__XXX
 SG_ SPNSupported3 : 64|16@1+ (1,0) [0|65535] "" Vector__XXX
 SG_ SPNSupported2 : 32|16@1+ (1,0) [0|65535] "" Vector__XXX
 SG_ SPNDataLength3 : 88|8@1+ (1,0) [0|240] "" Vector__XXX
 SG_ SPNSupportTypeSTR1 : 18|1@1+ (1,0) [0|1] "" Vector__XXX
 SG_ SPNSupportTypeDS1 : 17|1@1+ (1,0) [0|1] "" Vector__XXX
 SG_ SPNSupportTypeEFF1 : 16|1@1+ (1,0) [0|1] "" Vector__XXX
 SG_ SPNDataLength2 : 56|8@1+ (1,0) [0|240] "" Vector__XXX
 SG_ SPNDataLength1 : 24|8@1+ (1,0) [0|250] "" Vector__XXX
 SG_ SPNSupported1 : 0|16@1+ (1,0) [0|524287] "" Vector__XXX

BO_ 2566764030 DM23: 22 Vector__XXX
 SG_ FlashRedStopLamp : 12|2@1+ (1,0) [0|3] "" Vector__XXX
 SG_ FlashProtectLamp : 8|2@1+ (1,0) [0|3] "" Vector__XXX
 SG_ FlashMalfuncIndicatorLamp : 14|2@1+ (1,0) [0|3] "" Vector__XXX
 SG_ FlashAmberWarningLamp : 10|2@1+ (1,0) [0|3] "" Vector__XXX
 SG_ MalfunctionIndicatorLampStatus : 6|2@1+ (1,0) [0|3] "" Vector__XXX
 SG_ RedStopLampState : 4|2@1+ (1,0) [0|3] "" Vector__XXX
 SG_ AmberWarningLampStatus : 2|2@1+ (1,0) [0|3] "" Vector__XXX
 SG_ ProtectLampStatus : 0|2@1+ (1,0) [0|3] "" Vector__XXX
 SG_ DTC5 : 144|32@1+ (1,0) [0|4294967295] "" Vector__XXX
 SG_ DTC4 : 112|32@1+ (1,0) [0|4294967295] "" Vector__XXX
 SG_ DTC3 : 80|32@1+ (1,0) [0|4294967295] "" Vector__XXX
 SG_ DTC2 : 48|32@1+ (1,0) [0|4294967295] "" Vector__XXX
 SG_ DTC1 : 16|32@1+ (1,0) [0|4294967295] "" Vector__XXX

BO_ 2562981630 DM22: 8 Vector__XXX
 SG_ SPN1 : 40|16@1+ (1,0) [0|524287] "" Vector__XXX
 SG_ IndividualDTCClearControlByte : 0|8@1+ (1,0) [0|255] "" Vector__XXX
 SG_ CtrlByteIndicIndividualDTCClear : 8|8@1+ (1,0) [0|255] "" Vector__XXX
 SG_ FailureModeIdentifier1 : 56|5@1+ (1,0) [0|31] "" Vector__XXX
 SG_ SPN1High : 61|3@1+ (1,0) [0|7] "" Vector__XXX

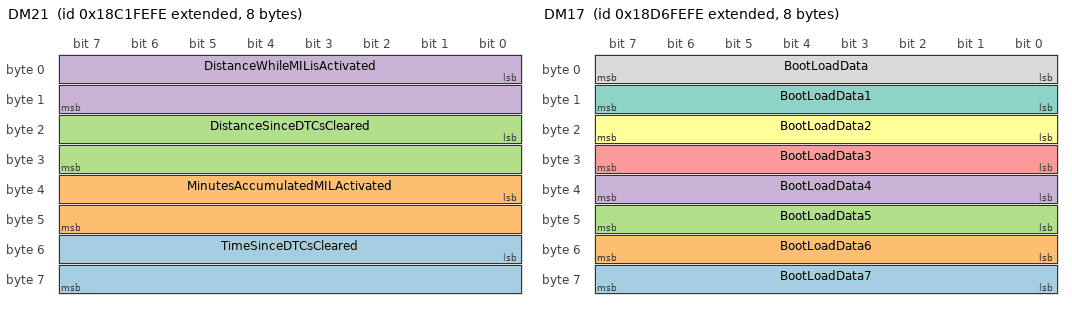
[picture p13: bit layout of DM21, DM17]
BO_ 2562850558 DM21: 8 Vector__XXX
 SG_ TimeSinceDTCsCleared : 48|16@1+ (1,0) [0|64255] "min" Vector__XXX
 SG_ MinutesAccumulatedMILActivated : 32|16@1+ (1,0) [0|64255] "min" Vector__XXX
 SG_ DistanceSinceDTCsCleared : 16|16@1+ (1,0) [0|64255] "km" Vector__XXX
 SG_ DistanceWhileMILisActivated : 0|16@1+ (1,0) [0|64255] "km" Vector__XXX

BO_ 2562916094 DM20: 11 Vector__XXX
 SG_ ApplSysMonitorDenominator : 72|16@1+ (1,0) [0|65535] "" Vector__XXX
 SG_ ApplSysMonitorNumerator : 56|16@1+ (1,0) [0|65535] "" Vector__XXX
 SG_ SPNofApplSysMonitor : 32|24@1+ (1,0) [0|524287] "" Vector__XXX
 SG_ OBDMonitoringCondEncountered : 16|16@1+ (1,0) [0|65535] "" Vector__XXX
 SG_ IgnitionCycleCounter : 0|16@1+ (1,0) [0|65535] "" Vector__XXX

BO_ 2566835198 DM02: 22 Vector__XXX
 SG_ MalfunctionIndicatorLampStatus : 6|2@1+ (1,0) [0|3] "" Vector__XXX
 SG_ RedStopLampState : 4|2@1+ (1,0) [0|3] "" Vector__XXX
 SG_ AmberWarningLampStatus : 2|2@1+ (1,0) [0|3] "" Vector__XXX
 SG_ ProtectLampStatus : 0|2@1+ (1,0) [0|3] "" Vector__XXX
 SG_ FlashRedStopLamp : 12|2@1+ (1,0) [0|3] "" Vector__XXX
 SG_ FlashProtectLamp : 8|2@1+ (1,0) [0|3] "" Vector__XXX
 SG_ FlashMalfuncIndicatorLamp : 14|2@1+ (1,0) [0|3] "" Vector__XXX
 SG_ FlashAmberWarningLamp : 10|2@1+ (1,0) [0|3] "" Vector__XXX
 SG_ DTC5 : 144|32@1+ (1,0) [0|4294967295] "" Vector__XXX
 SG_ DTC4 : 112|32@1+ (1,0) [0|4294967295] "" Vector__XXX
 SG_ DTC3 : 80|32@1+ (1,0) [0|4294967295] "" Vector__XXX
 SG_ DTC2 : 48|32@1+ (1,0) [0|4294967295] "" Vector__XXX
 SG_ DTC1 : 16|32@1+ (1,0) [0|4294967295] "" Vector__XXX

BO_ 2564030206 DM19: 20 Vector__XXX
 SG_ CalibrationID4 : 128|32@1+ (1,0) [0|4294967295] "" Vector__XXX
 SG_ CalibrationID3 : 96|32@1+ (1,0) [0|4294967295] "" Vector__XXX
 SG_ CalibrationID2 : 64|32@1+ (1,0) [0|4294967295] "" Vector__XXX
 SG_ CalibrationID1 : 32|32@1+ (1,0) [0|255] "" Vector__XXX
 SG_ CalibrationVerificationNumber : 0|32@1+ (1,0) [0|4294967295] "" Vector__XXX

BO_ 2564226814 DM17: 8 Vector__XXX
 SG_ BootLoadData7 : 56|8@1- (1,0) [0|0] "" Vector__XXX
 SG_ BootLoadData6 : 48|8@1- (1,0) [0|0] "" Vector__XXX
 SG_ BootLoadData5 : 40|8@1- (1,0) [0|0] "" Vector__XXX
 SG_ BootLoadData4 : 32|8@1- (1,0) [0|0] "" Vector__XXX
 SG_ BootLoadData3 : 24|8@1- (1,0) [0|0] "" Vector__XXX
 SG_ BootLoadData2 : 16|8@1- (1,0) [0|0] "" Vector__XXX
 SG_ BootLoadData1 : 8|8@1- (1,0) [0|0] "" Vector__XXX
 SG_ BootLoadData : 0|8@1+ (1,0) [0|0] "" Vector__XXX

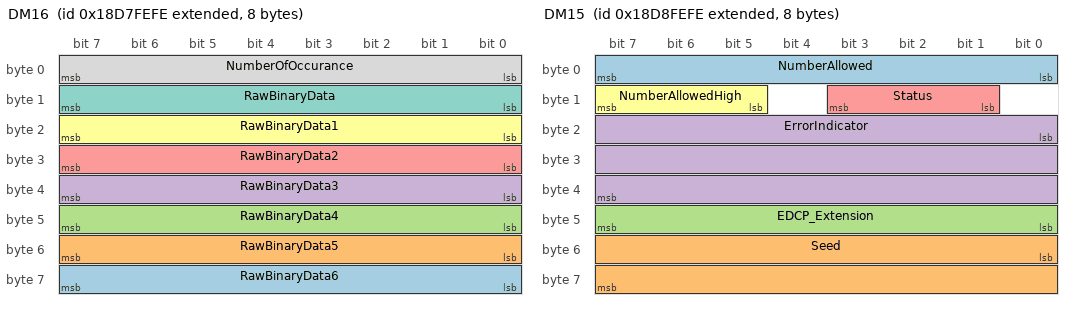
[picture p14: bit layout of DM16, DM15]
BO_ 2564292350 DM16: 8 Vector__XXX
 SG_ RawBinaryData6 : 56|8@1- (1,0) [0|0] "" Vector__XXX
 SG_ RawBinaryData5 : 48|8@1- (1,0) [0|0] "" Vector__XXX
 SG_ RawBinaryData4 : 40|8@1- (1,0) [0|0] "" Vector__XXX
 SG_ RawBinaryData3 : 32|8@1- (1,0) [0|0] "" Vector__XXX
 SG_ RawBinaryData2 : 24|8@1- (1,0) [0|0] "" Vector__XXX
 SG_ RawBinaryData1 : 16|8@1- (1,0) [0|0] "" Vector__XXX
 SG_ RawBinaryData : 8|8@1+ (1,0) [0|0] "" Vector__XXX
 SG_ NumberOfOccurance : 0|8@1+ (1,0) [0|255] "" Vector__XXX

BO_ 2564357886 DM15: 8 Vector__XXX
 SG_ NumberAllowed : 0|8@1+ (1,0) [0|2047] "" Vector__XXX
 SG_ Seed : 48|16@1+ (1,0) [0|65535] "" Vector__XXX
 SG_ EDCP_Extension : 40|8@1+ (1,0) [0|255] "" Vector__XXX
 SG_ ErrorIndicator : 16|24@1+ (1,0) [0|16777215] "" Vector__XXX
 SG_ Status : 9|3@1+ (1,0) [0|7] "" Vector__XXX
 SG_ NumberAllowedHigh : 13|3@1+ (1,0) [0|7] "" Vector__XXX

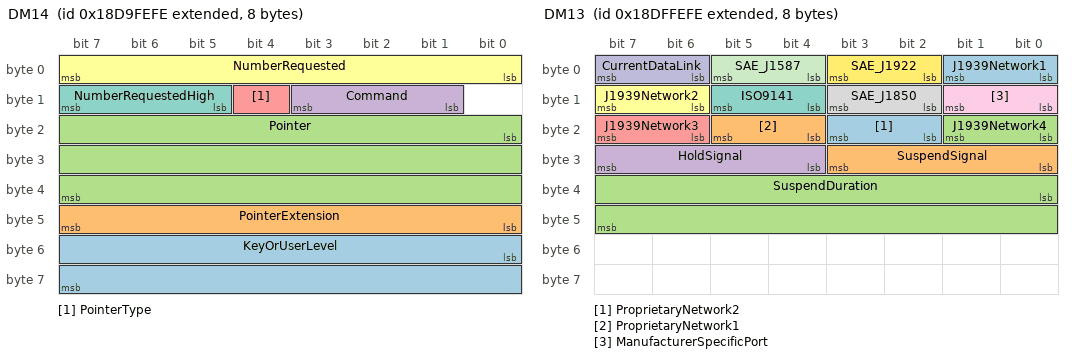
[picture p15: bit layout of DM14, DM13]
BO_ 2564423422 DM14: 8 Vector__XXX
 SG_ KeyOrUserLevel : 48|16@1+ (1,0) [0|65535] "" Vector__XXX
 SG_ PointerExtension : 40|8@1+ (1,0) [0|255] "" Vector__XXX
 SG_ Pointer : 16|24@1+ (1,0) [0|16777215] "" Vector__XXX
 SG_ Command : 9|3@1+ (1,0) [0|7] "" Vector__XXX
 SG_ PointerType : 12|1@1+ (1,0) [0|1] "" Vector__XXX
 SG_ NumberRequested : 0|8@1+ (1,0) [0|2047] "" Vector__XXX
 SG_ NumberRequestedHigh : 13|3@1+ (1,0) [0|7] "" Vector__XXX

BO_ 2564816638 DM13: 8 Vector__XXX
 SG_ ProprietaryNetwork2 : 18|2@1+ (1,0) [0|3] "" Vector__XXX
 SG_ ProprietaryNetwork1 : 20|2@1+ (1,0) [0|3] "" Vector__XXX
 SG_ J1939Network4 : 16|2@1+ (1,0) [0|3] "" Vector__XXX
 SG_ HoldSignal : 28|4@1+ (1,0) [0|15] "" Vector__XXX
 SG_ J1939Network3 : 22|2@1+ (1,0) [0|3] "" Vector__XXX
 SG_ J1939Network2 : 14|2@1+ (1,0) [0|3] "" Vector__XXX
 SG_ ISO9141 : 12|2@1+ (1,0) [0|3] "" Vector__XXX
 SG_ SAE_J1850 : 10|2@1+ (1,0) [0|3] "" Vector__XXX
 SG_ ManufacturerSpecificPort : 8|2@1+ (1,0) [0|3] "" Vector__XXX
 SG_ CurrentDataLink : 6|2@1+ (1,0) [0|3] "" Vector__XXX
 SG_ SAE_J1587 : 4|2@1+ (1,0) [0|3] "" Vector__XXX
 SG_ SAE_J1922 : 2|2@1+ (1,0) [0|3] "" Vector__XXX
 SG_ J1939Network1 : 0|2@1+ (1,0) [0|3] "" Vector__XXX
 SG_ SuspendSignal : 24|4@1+ (1,0) [0|15] "" Vector__XXX
 SG_ SuspendDuration : 32|16@1+ (1,0) [0|64255] "s" Vector__XXX

BO_ 2566837502 DM12: 22 Vector__XXX
 SG_ FlashRedStopLamp : 12|2@1+ (1,0) [0|3] "" Vector__XXX
 SG_ FlashProtectLamp : 8|2@1+ (1,0) [0|3] "" Vector__XXX
 SG_ MalfunctionIndicatorLampStatus : 6|2@1+ (1,0) [0|3] "" Vector__XXX
 SG_ RedStopLampState : 4|2@1+ (1,0) [0|3] "" Vector__XXX
 SG_ AmberWarningLampStatus : 2|2@1+ (1,0) [0|3] "" Vector__XXX
 SG_ ProtectLampStatus : 0|2@1+ (1,0) [0|3] "" Vector__XXX
 SG_ FlashMalfuncIndicatorLamp : 14|2@1+ (1,0) [0|3] "" Vector__XXX
 SG_ FlashAmberWarningLamp : 10|2@1+ (1,0) [0|3] "" Vector__XXX
 SG_ DTC5 : 144|32@1+ (1,0) [0|4294967295] "" Vector__XXX
 SG_ DTC4 : 112|32@1+ (1,0) [0|4294967295] "" Vector__XXX
 SG_ DTC3 : 80|32@1+ (1,0) [0|4294967295] "" Vector__XXX
 SG_ DTC2 : 48|32@1+ (1,0) [0|4294967295] "" Vector__XXX
 SG_ DTC1 : 16|32@1+ (1,0) [0|4294967295] "" Vector__XXX

BO_ 2566837246 DM11: 0 Vector__XXX

BO_ 2566836990 DM10: 8 Vector__XXX
 SG_ TestIdentifierSupported : 0|64@1+ (1,0) [0|0] "" Vector__XXX

BO_ 2566834942 DM01: 22 Vector__XXX
 SG_ FlashRedStopLamp : 12|2@1+ (1,0) [0|3] "" Vector__XXX
 SG_ FlashProtectLamp : 8|2@1+ (1,0) [0|3] "" Vector__XXX
 SG_ FlashMalfuncIndicatorLamp : 14|2@1+ (1,0) [0|3] "" Vector__XXX
 SG_ FlashAmberWarningLamp : 10|2@1+ (1,0) [0|3] "" Vector__XXX
 SG_ MalfunctionIndicatorLampStatus : 6|2@1+ (1,0) [0|3] "" Vector__XXX
 SG_ AmberWarningLampStatus : 2|2@1+ (1,0) [0|3] "" Vector__XXX
 SG_ RedStopLampState : 4|2@1+ (1,0) [0|3] "" Vector__XXX
 SG_ ProtectLampStatus : 0|2@1+ (1,0) [0|3] "" Vector__XXX
 SG_ DTC5 : 144|32@1+ (1,0) [0|4294967295] "" Vector__XXX
 SG_ DTC4 : 112|32@1+ (1,0) [0|4294967295] "" Vector__XXX
 SG_ DTC3 : 80|32@1+ (1,0) [0|4294967295] "" Vector__XXX
 SG_ DTC2 : 48|32@1+ (1,0) [0|4294967295] "" Vector__XXX
 SG_ DTC1 : 16|32@1+ (1,0) [0|4294967295] "" Vector__XXX

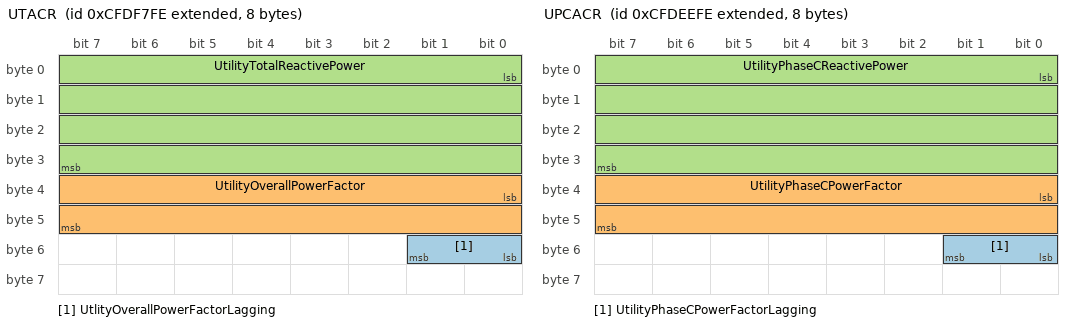
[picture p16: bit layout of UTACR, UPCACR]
BO_ 2365454334 UTACR: 8 Vector__XXX
 SG_ UtlityOverallPowerFactorLagging : 48|2@1+ (1,0) [0|3] "" Vector__XXX
 SG_ UtilityOverallPowerFactor : 32|16@1+ (6.103515625E-005,-1) [-1|2.92181396484375] "" Vector__XXX
 SG_ UtilityTotalReactivePower : 0|32@1+ (1,-2000000000) [-2000000000|2211081215] "VAr" Vector__XXX

BO_ 2365454590 UTACP: 8 Vector__XXX
 SG_ UtilityTotalApparentPower : 32|32@1+ (1,-2000000000) [-2000000000|2211081215] "VA" Vector__XXX
 SG_ UtilityTotalRealPower : 0|32@1+ (1,-2000000000) [-2000000000|2211081215] "W" Vector__XXX

BO_ 2365451774 UTACE: 8 Vector__XXX
 SG_ UtilityTotalKWHoursImport : 32|32@1+ (1,0) [0|4211081215] "kWh" Vector__XXX
 SG_ UtilityTotalKWHoursExport : 0|32@1+ (1,0) [0|4211081215] "kWh" Vector__XXX

BO_ 2365452030 UPCACR: 8 Vector__XXX
 SG_ UtilityPhaseCPowerFactorLagging : 48|2@1+ (1,0) [0|3] "" Vector__XXX
 SG_ UtilityPhaseCPowerFactor : 32|16@1+ (6.103515625E-005,-1) [-1|2.92181396484375] "" Vector__XXX
 SG_ UtilityPhaseCReactivePower : 0|32@1+ (1,-2000000000) [-2000000000|2211081215] "VAr" Vector__XXX

BO_ 2365452286 UPCACP: 8 Vector__XXX
 SG_ UtilityPhaseCApparentPower : 32|32@1+ (1,-2000000000) [-2000000000|2211081215] "VA" Vector__XXX
 SG_ UtilityPhaseCRealPower : 0|32@1+ (1,-2000000000) [-2000000000|2211081215] "W" Vector__XXX

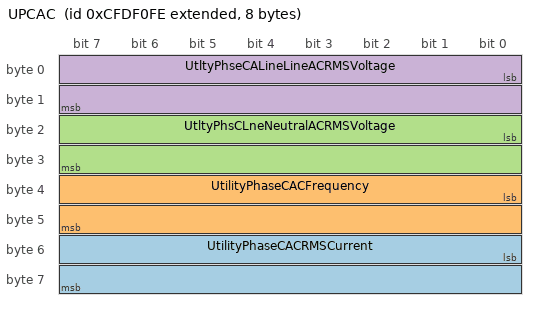
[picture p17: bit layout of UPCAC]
BO_ 2365452542 UPCAC: 8 Vector__XXX
 SG_ UtilityPhaseCACRMSCurrent : 48|16@1+ (1,0) [0|64255] "A" Vector__XXX
 SG_ UtilityPhaseCACFrequency : 32|16@1+ (0.0078125,0) [0|501.9921875] "Hz" Vector__XXX
 SG_ UtltyPhsCLneNeutralACRMSVoltage : 16|16@1+ (1,0) [0|64255] "V" Vector__XXX
 SG_ UtltyPhseCALineLineACRMSVoltage : 0|16@1+ (1,0) [0|64255] "V" Vector__XXX

CM_ BO_ 2633934846 "Alternator Temperature 1";
CM_ SG_ 2633934846 EngAltWinding6Temp "Temperature of this winding inside the alternator.";
CM_ SG_ 2633934846 EngAltWinding5Temp "Temperature of this winding inside the alternator.";
CM_ SG_ 2633934846 EngAltWinding4Temp "Temperature of this winding inside the alternator.";
CM_ SG_ 2633934846 EngAltWinding3Temp "Temperature of the windings inside the alternator.";
CM_ SG_ 2633934846 EngAltWinding2Temp "Temperature of the windings inside the alternator.";
CM_ SG_ 2633934846 EngAltWinding1Temp "Temperature of the windings inside the alternator.";
CM_ SG_ 2633934846 EngAltBearing2Temp "Temperature of the bearing inside the alternator.  Bearing 2 is the right or front bearing.";
CM_ SG_ 2633934846 EngAltBearing1Temp "Temperature of the bearing inside the alternator.  Bearing 1 is the left or rear bearing.";
CM_ BO_ 2362572542 "Air Suspension Control 6
Used for suspension control";
CM_ SG_ 2362572542 LevelPresetRearAxleRight "Set value for nominal level 'preset level' at the right side of the rear axle. This value is referred to 'Normal level 1'.  For explanations of normal level 1 see SPN 1734 - Nominal Level Front Axle.";
CM_ SG_ 2362572542 LevelPresetRearAxleLeft "Set value for nominal level 'preset level' at the left side of the rear axle. This value is referred to 'Normal level 1'.  For explanations of normal level 1 see SPN 1734 - Nominal Level Front Axle.";
CM_ SG_ 2362572542 LevelPresetFrontAxleRight "Set value for nominal level 'preset level' at the right side of the front axle. This value is referred to 'Normal level 1'.  For explanations of normal level 1 see SPN 1734 - Nominal Level Front Axle.";
CM_ SG_ 2362572542 LevelPresetFrontAxleLeft "Set value for nominal level 'preset level' at the left side of the front axle. This value is referred to 'Normal level 1'.  For explanations of normal level 1 see parameter SPN 1734 - Nominal Level Front Axle.";
CM_ BO_ 2365478910 "Air Suspension Control 5
Used for damper stiffness information";
CM_ SG_ 2365478910 ElctrncShckAbsrbrCtrlMdLft_TgAxl "Signal which indicates the current mode of operation of the electronic shock absorber control at the lift/tag axle.

00b = Normal operation dampers passive
01b = Normal operation dampers active
10b = Error
11b = Not available";
CM_ SG_ 2365478910 ElctrncShckAbsrbrCtrlMdeRearAxle "Signal which indicates the current mode of operation of the electronic shock absorber control at the rear axle.

00b = Normal operation dampers passive
01b = Normal operation dampers active
10b = Error
11b = Not available";
CM_ SG_ 2365478910 ElctrncShckAbsrbrCtrlMdFrontAxle "Signal which indicates the current mode of operation of the electronic shock absorber control at the front axle.

00b = Normal operation dampers passive
01b = Normal operation dampers active
10b = Error
11b = Not available";
CM_ SG_ 2365478910 DamperStiffnessLift_TagAxle "Damper stiffness information of the shock absorber control at the lift of tag axle";
CM_ SG_ 2365478910 DamperStiffnessRearAxle "Damper stiffness information of the shock absorber control at the rear axle";
CM_ SG_ 2365478910 DamperStiffnessFrontAxle "Damper stiffness information of the shock absorber control at the front axle";
CM_ BO_ 2560950014 "Scaled Test Results
This message conveys the scaled test results for the applicable test requested in DM7. The SPN and FMI convey the specific DTC for which the results are being reported.";
CM_ SG_ 2560950014 SPN1 "This 19-bit number is used to identify the item for which diagnostics are being reported.";
CM_ SG_ 2560950014 TestLimitMinimum "The test value must be greater than or equal to Test Limit Minimum in order for the test to pass";
CM_ SG_ 2560950014 FailureModeIdentifier1 "The FMI defines the type of failure detected in the subsystem identified by an SPN.";
CM_ SG_ 2560950014 TestLimitMaximum "The test value must be less than or equal to Test Limit Maximum in order for the test to pass.";
CM_ SG_ 2560950014 TestValue "The test value collected during the test.";
CM_ SG_ 2560950014 SlotId "The SLOT Identifer is used to determine the multiplier and offset to be used to scale the test value.";
CM_ SG_ 2560950014 TestIdentifier "Test Identifier";
CM_ SG_ 2560950014 SPN1High "SPN #1 (Conversion Version 4)";
CM_ BO_ 2566763262 "Aftertreatment 1 Intermediate Gas
The purpose of this PG is to group the aftertreatment intermediate gas temperature and pressure messages.
Note: The 5 bits of SPN 3253 are positioned into the data field in the following manner.  The 2 most ...";
CM_ SG_ 2566763262 DPFIntmdTempPreliminaryFMI "Used to identify the applicable J1939-73 FMI detected in the diesel particulate filter intermediate temperature sensor by the manufacturer’s sensor control software in exhaust bank 1.  In the case of multiple failures the most severe is ...";
CM_ SG_ 2566763262 DPFDiffPressPreliminaryFMI "Used to identify the applicable J1939-73 FMI detected in the diesel particulate filter differential pressure sensor by the manufacturer’s sensor control software in exhaust bank 1.  In the case of multiple failures the most severe is communicated.
 ...";
CM_ SG_ 2566763262 ExhTemp2PreliminaryFMI "Used to identify the applicable J1939-73 FMI detected in the exhaust temperature 2 sensor by the manufacturer’s sensor control software in exhaust bank 1.  In the case of multiple failures the most severe is communicated.
A value of 31 is sent to ...";
CM_ SG_ 2566763262 DPFDiffPress "Exhaust differential pressure measured between the intake and exhaust of a diesel particulate filter in exhaust bank 1.";
CM_ SG_ 2566763262 DPFIntmdTemp "Temperature of engine combustion byproducts at a mid-point in the diesel particulate filter in exhaust bank 1.";
CM_ SG_ 2566763262 ExhTemp2 "The reading from the exhaust temperature sensor located midstream of the other two temperature sensors in the aftertreatment system in exhaust bank 1.";
CM_ BO_ 2565869566 "Aftertreatment 1 Outlet Gas 1
The purpose of this PG is to group the aftertreatment outlet sensor data for bank 1.  These values include the NOx, %O2, status of the sensors with respect to the power being supplied and the heating element, errors ...";
CM_ SG_ 2565869566 O2Snsr1PreliminaryFMI "Used to identify the applicable J1939-73 FMI detected in the aftertreatment outlet oxygen sensor by the manufacturer’s sensor control software in exhaust bank 1.  In the case of multiple failures the most severe is communicated.
A value of 31 is ...";
CM_ SG_ 2565869566 NOxSnsr1SelfDiagSt "Self-diagnosis result status for NOx sensor ATO1 (Aftertreatment Outlet Bank 1)
000b = Diagnosis not active
001b = NOx Sensor ATO1 Self-diagnosis active flag
010b = NOx Sensor ATO1 Self-diagnosis Result Complete
011b = NOx Sensor ATO1 ...";
CM_ SG_ 2565869566 NOxSnsr1PreliminaryFMI "Used to identify the applicable J1939-73 FMI detected in the aftertreatment outlet NOx sensor by the manufacturer’s sensor control software in exhaust bank 1.  In the case of multiple failures the most severe is communicated.
A value of 31 is sent ...";
CM_ SG_ 2565869566 Snsr1HtrCtrl "Indicates the heater status in the warm-up process.  Upon receiving a power-up command, the gas sensor ramps up according to a manufacturer defined profile.  The Preheat 1, Preheat 2, and Automatic messages are regions within this profile in exhaust ...";
CM_ SG_ 2565869566 Snsr1HtrPreliminaryFMI "Used to identify the applicable J1939-73 FMI detected in the heater of the outlet exhaust gas sensor, either NOx or O2, by the manufacturer’s sensor control software in exhaust bank 1.  In the case of multiple failures the most severe is ...";
CM_ SG_ 2565869566 WRPercentO21ReadingStable "Indicates that the percent oxygen reading of the aftertreatment outlet gas sensor, either NOx or O2, is stable as determined by the manufacturer's control software in exhaust bank 1.
00b = Not stable
01b = Stable
10b = Error
11b = Not available
 ...";
CM_ SG_ 2565869566 NOx1ReadingStable "Indicates that the NOx reading of the aftertreatment outlet NOx sensor is stable as determined by the manufacturer's control software in exhaust bank 1.

00b = Not stable
01b = Stable
10b = Error
11b = Not available";
CM_ SG_ 2565869566 Snsr1AtTemp "Indicates that the heater element of the aftertreatment outlet gas sensor, either NOx or O2, is within the manufacturer's specified range for accurate measurements in exhaust bank 1.
00b = Not in range
01b = In range
10b = Error
11b = Not ...";
CM_ SG_ 2565869566 Snsr1PwrInRange "Indicates that the power supplied to the aftertreatment outlet gas sensor, either NOx or O2, is within the manufacturer's specification in exhaust bank 1. This parameter reports the status as reported by the sensor.
00b = Not in range
01b = In ...";
CM_ SG_ 2565869566 PercentO21 "The actual oxidation factor (percent oxygen) of the gas within the exhaust stream.  For positive values, the parameter represents the percent oxygen in excess of the amount required for stoichiometric combustion.  For negative values, the parameter ...";
CM_ SG_ 2565869566 NOx1 "The amount of combined NO and NO2 in the exhaust exiting the aftertreatment system measured by a NOx sensor at the aftertreatment outlet, represented in NOx molecule parts per million non-NOx molecules in exhaust bank 1.
SPN 3226 shall display the ...";
CM_ BO_ 2566763518 "Aftertreatment 1 Outlet Gas 2
The purpose of this PG is to group the aftertreatment outlet gas temperature messages.";
CM_ SG_ 2566763518 DPFOutExhTempPreliminaryFMI "Used to identify the applicable J1939-73 FMI detected in the diesel particulate filter outlet temperature sensor by the manufacturer’s sensor control software in exhaust bank 1. In the case of multiple failures the most severe is communicated.
A ...";
CM_ SG_ 2566763518 ExhTemp3PreliminaryFMI "Used to identify the applicable J1939-73 FMI detected in the exhaust temperature 3 sensor by the manufacturer’s sensor control software in exhaust bank 1.  In the case of multiple failures the most severe is communicated.
A value of 31 is sent to ...";
CM_ SG_ 2566763518 DPFOutTemp "Temperature of engine combustion byproducts leaving the diesel particulate filter exhaust in exhaust bank 1.";
CM_ SG_ 2566763518 ExhTemp3 "The reading from the exhaust temperature sensor located farthest downstream in the aftertreatment system in exhaust bank 1.";
CM_ BO_ 2566749182 "Aftertreatment 1 Service 1
This PG contains information about the aftertreatment 1 (diesel particulate filter 1 soot and ash load).";
CM_ SG_ 2566749182 DPFSootLoadRegenThld "This parameter indicates the value that will first cause DPF regeneration in aftertreatment 1. There may be multiple parameters that cause DPF regeneration (e.g. Percent Soot Load, DPF delta pressure converted to normalized percentage, etc.).  If ...";
CM_ SG_ 2566749182 DPFTimeSinceLastActiveRegen "Indicates the time since the last active regeneration event of diesel particulate filter 1.";
CM_ SG_ 2566749182 DPFAshLoadPercent "Indicates the ash load percent of diesel particulate filter 1.  100% is the level at which diesel particulate filter ash service should be performed.
100% level is the target ash service interval (and if ash service is not immediately performed, ...";
CM_ SG_ 2566749182 DPFSootLoadPercent "Indicates the soot load percent of diesel particulate filter 1.  100% is the level at which active diesel particulate filter regeneration should be triggered.
100% level is the active regeneration trigger level (and if conditions are not favorable ...";
CM_ BO_ 2566748670 "Aftertreatment 1 Trip Information
This PG contains trip total information about the aftertreatment 1.  

NOTE: The SPs in this PG need to be reset by the Reset PG (PGN 56832).";
CM_ SG_ 2566748670 DPFTripNumOfActiveRegenManReq "Total number of aftertreatment 1 diesel particulate filter active regeneration manual requests by the operator during the current trip period.

NOTE: This SP needs to be reset by the Reset PG (PGN 56832).";
CM_ SG_ 2566748670 DPFTripNumOfActiveRegenInhReq "Total number of aftertreatment 1 diesel particulate filter active regeneration inhibit requests by the operator during the current trip period.

NOTE: This SP needs to be reset by the Reset PG (PGN 56832).";
CM_ SG_ 2566748670 DPFTripNumOfPassiveRegens "Total number of passive regenerations of the aftertreatment 1 diesel particulate filter during the current trip period.

NOTE: This SP needs to be reset by the Reset PG (PGN 56832).";
CM_ SG_ 2566748670 DPFTripPassiveRegenTime "Total amount of time that the aftertreatment 1 diesel particulate filter has been in passive regeneration during the current trip period.

NOTE: This SP needs to be reset by the Reset PG (PGN 56832).";
CM_ SG_ 2566748670 DPFTripNumOfActiveRegens "Total number of active regenerations of the aftertreatment 1 diesel particulate filter during the current trip period.

NOTE: This SP needs to be reset by the Reset PG (PGN 56832).";
CM_ SG_ 2566748670 DPFTripDisabledTime "Total amount of time that aftertreatment 1 diesel particulate filter regeneration has been manually disabled during the current trip period.

NOTE: This SP needs to be reset by the Reset PG (PGN 56832).";
CM_ SG_ 2566748670 DPFTripActiveRegenTime "Total amount of time that the aftertreatment 1 diesel particulate filter has been in active regeneration during the current trip period.

NOTE: This SP needs to be reset by the Reset PG (PGN 56832).";
CM_ SG_ 2566748670 DPFTripFuelUsed "Total amount of fuel used by the aftertreatment 1 diesel particulate filter during the current trip period.

NOTE: This SP needs to be reset by the Reset PG (PGN 56832).";
CM_ BO_ 2566758142 "Aftertreatment 2 Air Control 1
Contains information about the aftertreatment 2 air system";
CM_ SG_ 2566758142 EnableAct "Indicates whether aftertreatment 2 air enable actuator is on or off

00b = not active
01b = active
10b = reserved for SAE assignment
11b = not available";
CM_ SG_ 2566758142 PurgeAirAct "Indicates whether aftertreatment 2 purge air actuator is on or off

00b = not active
01b = active
10b = reserved for SAE assignment
11b = not available";
CM_ SG_ 2566758142 AtomizationAirAct "Indicates whether aftertreatment 2 atomization air actuator is on or off

00b = not active
01b = active
10b = reserved for SAE assignment
11b = not available";
CM_ SG_ 2566758142 SysRelay "Indicates whether aftertreatment 2 air system relay is on or off

00b = not active
01b = active
10b = reserved for SAE assignment
11b = not available";
CM_ SG_ 2566758142 PressActPos "Position of the aftertreatment 2 air pressure actuator as measured by a position feedback sensor.";
CM_ SG_ 2566758142 PressCtrl "Position that the controller is commanding the aftertreatment 2 air pressure control to maintain.  0% = fully closed, 100% = fully open";
CM_ SG_ 2566758142 PurgeAirPress "Pressure of the purge air supply for aftertreatment 2";
CM_ SG_ 2566758142 SupplyAirPress "Pressure of the supply air for aftertreatment 2.  Supply air is the air supplied from a pneumatic line for an air-assisted or pneumatic actuator.  One example is an air assisted fuel injector (the supply air assists in the atomization of fuel).";
CM_ BO_ 2566745342 "Aftertreatment 2 Air Control 2
This PG contains information about the Aftertreatment 2 Air Control.
NOTE: This message will be transmitted by the engine or aftertreatment controller.  Other aftertreatment air control information could be added in ...";
CM_ SG_ 2566745342 SecAirPress "Pressure of the secondary air for aftertreatment 2.  Secondary air is air provided to the exhaust system (per SAE J2403).

For absolute pressure, see SPN 5590.";
CM_ SG_ 2566745342 SecAirMFR "Indicates the secondary air mass flow for aftertreatment 2.  Secondary air is the air provided to the exhaust system (per SAE J2403).";
CM_ SG_ 2566745342 SecAirTemp "Indicates the secondary air temperature for aftertreatment 2.  Secondary air is air provided to the exhaust system (per SAE J2403).";
CM_ SG_ 2566745342 SecAirDiffPress "Indicates the secondary air differential pressure for aftertreatment 2.  Secondary air is air provided to the exhaust system (per SAE J2403).";
CM_ BO_ 2566758654 "Aftertreatment 2 Fuel Control 1
Contains information about the aftertreatment 2 fuel system";
CM_ SG_ 2566758654 Injector1HtrCtrl "Heating level that the controller is commanding the aftertreatment 2 fuel injector 1 heater control to maintain. 0% = off, 100% = maximum.";
CM_ SG_ 2566758654 EnableAct "Indicates whether aftertreatment 2 fuel enable actuator is on or off

00b = not active
01b = active
10b = reserved for SAE assignment
11b = not available";
CM_ SG_ 2566758654 RegenSt "Indicates whether regeneration is active or inactive in aftertreatment 2.  

00b = not active
01b = active
10b = reserved for SAE assignment
11b = not available";
CM_ SG_ 2566758654 Ignt "Indicates whether aftertreatment 2 ignition circuit is energized by the ECU.

00b = not active
01b = active
10b = reserved for SAE assignment
11b = not available";
CM_ SG_ 2566758654 DrainAct "Indicates whether aftertreatment 2 fuel drain actuator is on or off

00b = not active
01b = active
10b = reserved for SAE assignment
11b = not available";
CM_ SG_ 2566758654 Press1Ctrl "Position that the controller is commanding the aftertreatment 2 fuel pressure control to maintain.  0% = fully closed, 100% = fully open.";
CM_ SG_ 2566758654 Rate "Rate of fuel being delivered to aftertreatment 2 for regeneration";
CM_ SG_ 2566758654 Press1 "Pressure of the fuel for Aftertreatment 2.";
CM_ BO_ 2566753278 "Aftertreatment 2 Gas Parameters
Diesel particulate filter gas parameters for system or bank 2";
CM_ SG_ 2566753278 DPFOutPress "This parameter indicates the diesel particulate filter outlet gage pressure 2 (bank 2).";
CM_ SG_ 2566753278 DPFInPress "This parameter indicates the diesel particulate filter intake gage pressure 2 (bank 2).";
CM_ BO_ 2566756862 "Aftertreatment 2 Historical information 1
Contains information about the history of the aftertreatment 2 system";
CM_ SG_ 2566756862 DPFAvgDistBetweenActiveRegens "Indicates the average distance since last reset between active regenerations, that have not been forced to occur by manual request, for aftertreatment device 2.
If the manufacturer allows this parameter to be reset, this distance is the average ...";
CM_ SG_ 2566756862 DPFAvgTimeBetweenActiveRegens "Indicates the average time since last reset between active regenerations, that have not been forced to occur by manual request, for Aftertreatment device 2.";
CM_ SG_ 2566756862 DPFTotalNumOfActiveRegenManReq "Total number of Aftertreatment device 2 active regeneration manual requests by the operator over the lifetime of the device.";
CM_ SG_ 2566756862 DPFTotalNumOfActiveRegenInhReq "Total number of Aftertreatment device 2 active regeneration inhibit requests by the operator over the lifetime of the device.";
CM_ SG_ 2566756862 DPFTotalNumOfPassiveRegens "Total number of passive regenerations by Aftertreatment device 2 over the lifetime of the device.";
CM_ SG_ 2566756862 DPFTotalPassiveRegenTime "Total amount of time that Aftertreatment device 2 has been in passive regeneration over the lifetime of the device.";
CM_ SG_ 2566756862 TotalNumOfActiveRegens "Total number of active regenerations by aftertreatment device 2 over the lifetime of the device.";
CM_ SG_ 2566756862 TotalDisabledTime "Total amount of time that aftertreatment 2 regeneration has been manually disabled.";
CM_ SG_ 2566756862 TotalRegenTime "Total amount of time that aftertreatment device 2 has been regenerating over the lifetime of the device.";
CM_ SG_ 2566756862 TotalFuelUsed "Total amount of fuel used by aftertreatment device 2 over the lifetime of the device.";
CM_ BO_ 2565869822 "Aftertreatment 2 Intake Gas 1
Groups the aftertreatment intake sensor data for bank 2 if an aftertreatment system exists.  If no aftertreatment system exists, then this PG includes sensor data for the exhaust in bank 2.
These values include the ...";
CM_ SG_ 2565869822 TwoGasSnsrPwrSupply "State signal which indicates when the Engine Exhaust 2 Intake 2 Gas Sensor driver output is being driven.  On means the ECU is powering the Engine Exhaust 2 Intake 2 Gas Sensor.  Note that the ECU is external to the sensor.
This sensor is located ...";
CM_ SG_ 2565869822 NOxSnsr1SelfDiagStatus "Self-diagnosis result status for NOx sensor Engine Exhaust Bank 2 (EEB2)
.  This sensor is located at the intake of the aftertreatment system if an aftertreatment system exists.
000b = Diagnosis not active
001b = NOx Sensor EEB2 Self-diagnosis ...";
CM_ SG_ 2565869822 O2Snsr1PreliminaryFMI "Used to identify the applicable J1939-73 FMI detected in the  oxygen sensor by the manufacturer’s sensor control software in exhaust bank 2.  In the case of multiple failures the most severe is communicated.
This sensor is located at the engine ...";
CM_ SG_ 2565869822 SCRInNOxSnsr1PreliminaryFMI "Used to identify the applicable J1939-73 FMI detected in the NOx sensor by the manufacturer’s sensor control software in exhaust bank 2.  This sensor is located at the intake of the SCR system if an SCR system exists.  In the case of multiple ...";
CM_ SG_ 2565869822 Snsr1HtrCtrl "Indicates the heater status in the warm-up process.  Upon receiving a power-up command, the gas sensor ramps up according to a manufacturer defined profile.  The Preheat 1, Preheat 2, and Automatic messages are regions within this profile in exhaust ...";
CM_ SG_ 2565869822 Snsr1HtrPreliminaryFMI "Used to identify the applicable J1939-73 FMI detected in the heater of the exhaust gas sensor, either NOx or O2, by the manufacturer’s sensor control software in exhaust bank 2.  In the case of multiple failures the most severe is communicated.
 ...";
CM_ SG_ 2565869822 WRPercentO21ReadingStable "Indicates that the percent oxygen reading of the gas sensor, either NOx or O2, is stable as determined by the manufacturer's control software in exhaust bank 2.
This sensor is located at the engine exhaust in bank 2 and before the aftertreatment ...";
CM_ SG_ 2565869822 SCRInNOx1ReadingStable "Indicates that the NOx reading of the first NOx sensor is stable as determined by the manufacturer's control software in exhaust bank 2.
This sensor is located at the intake of the SCR system if an SCR system exists.
For a single exhaust bank ...";
CM_ SG_ 2565869822 Snsr1AtTemp "Indicates that the heater element of the gas sensor, either NOx or O2, is within the manufacturer's specified range for accurate measurements in exhaust bank 2.
This sensor is located at the engine exhaust in bank 2 and before the aftertreatment ...";
CM_ SG_ 2565869822 Snsr1PwrInRange "Indicates that the power supplied to the intake gas sensor, either NOx or O2, is within the manufacturer's specification in exhaust bank 2. This parameter reports the status as reported by the sensor. This sensor is located at the intake of the SCR ...";
CM_ SG_ 2565869822 PercentO21 "The actual oxidation factor (percent oxygen) of the gas within the exhaust stream.  For positive values, the parameter represents the percent oxygen in excess of the amount required for stoichiometric combustion.  For negative values, the parameter ...";
CM_ SG_ 2565869822 SCRInNOx1 "The amount of combined NO and NO2 in the exhaust, represented in NOx molecule parts per million non-NOx molecules, in exhaust bank 2.  This sensor is located at the intake of the SCR system if an SCR system exists.
For a single exhaust bank system, ...";
CM_ BO_ 2566763006 "Aftertreatment 2 Intake Gas 2
Groups the aftertreatment intake gas temperature messages for bank 2 if an aftertreatment system exists.  If no aftertreatment system exists, then the parameters in this PG will contain data for the exhaust in bank 2.";
CM_ SG_ 2566763006 DPFInTempPreliminaryFMI "Used to identify the applicable J1939-73 FMI detected in the diesel particulate filter intake temperature sensor by the manufacturer’s sensor control software in exhaust bank 2.  In the case of multiple failures the most severe is communicated.
A ...";
CM_ SG_ 2566763006 ExhTemp1PreliminaryFMI "Used to identify the applicable J1939-73 FMI detected in the exhaust temperature 1 sensor by the manufacturer’s sensor control software in exhaust bank 2.  In the case of multiple failures the most severe is communicated.
A value of 31 is sent to ...";
CM_ SG_ 2566763006 DPFInTemp "Temperature of engine combustion byproducts entering the diesel particulate filter in exhaust bank 2.  (For a single exhaust bank system, refer to parameters in PGNs 61454, 61455,  64946, 64947, 64948, and 65247)";
CM_ SG_ 2566763006 ExhTemp1 "The reading from the exhaust temperature sensor located farthest upstream in the aftertreatment system in exhaust bank 2.  (For a single exhaust bank system, refer to parameters in PGNs 61454, 61455,  64946, 64947, 64948, and 65247)";
CM_ BO_ 2566762494 "Aftertreatment 2 Intermediate Gas
The purpose of this PG is to group the aftertreatment intermediate gas temperature and pressure messages for bank 2.";
CM_ SG_ 2566762494 DPFIntmdTempPreliminaryFMI "Used to identify the applicable J1939-73 FMI detected in the diesel particulate filter intermediate temperature sensor by the manufacturer’s sensor control software in exhaust bank 2.  In the case of multiple failures the most severe is ...";
CM_ SG_ 2566762494 DPFDiffPressPreliminaryFMI "Used to identify the applicable J1939-73 FMI detected in the diesel particulate filter differential pressure sensor by the manufacturer’s sensor control software in exhaust bank 2.  In the case of multiple failures the most severe is communicated.
 ...";
CM_ SG_ 2566762494 ExhTemp2PreliminaryFMI "Used to identify the applicable J1939-73 FMI detected in the exhaust temperature 2 sensor by the manufacturer’s sensor control software in exhaust bank 2.  In the case of multiple failures the most severe is communicated.
A value of 31 is sent to ...";
CM_ SG_ 2566762494 DPFDiffPress "Exhaust differential pressure measured between the intake and exhaust of a diesel particulate filter in exhaust bank 2.  (For a single exhaust bank system, refer to parameters in PGNs 61454, 61455,  64946, 64947, 64948, and 65247)";
CM_ SG_ 2566762494 DPFIntmdTemp "Temperature of engine combustion byproducts at a mid-point in the diesel particulate filter in exhaust bank 2.  (For a single exhaust bank system, refer to parameters in PGNs 61454, 61455,  64946, 64947, 64948, and 65247)";
CM_ SG_ 2566762494 ExhTemp2 "The reading from the exhaust temperature sensor located midstream of the other two temperature sensors in the aftertreatment system in exhaust bank 2.  (For a single exhaust bank system, refer to parameters in PGNs 61454, 61455,  64946, 64947, ...";
CM_ BO_ 2565870078 "Aftertreatment 2 Outlet Gas 1
The purpose of this PG is to group the aftertreatment outlet sensor data for bank 2.  These values include the NOx, %O2, status of the sensors with respect to the power being supplied and the heating element, errors ...";
CM_ SG_ 2565870078 TwoGasSnsrPwrSupply "State signal which indicates when the Aftertreatment 2 Outlet 2 Gas Sensor driver output is being driven.  On means the ECU is powering the Aftertreatment 2 Outlet 2 Gas Sensor.  Note that the ECU is external to the sensor.
00b = Off
01b = On: The ...";
CM_ SG_ 2565870078 O2Snsr1PreliminaryFMI "Used to identify the applicable J1939-73 FMI detected in the aftertreatment outlet oxygen sensor by the manufacturer’s sensor control software in exhaust bank 2.  In the case of multiple failures the most severe is communicated.
A value of 31 is ...";
CM_ SG_ 2565870078 NOxSnsr1PreliminaryFMI "Used to identify the applicable J1939-73 FMI detected in the aftertreatment outlet NOx sensor by the manufacturer’s sensor control software in exhaust bank 2.  In the case of multiple failures the most severe is communicated.
A value of 31 is sent ...";
CM_ SG_ 2565870078 Snsr1HtrCtrl "Indicates the heater status in the warm-up process.  Upon receiving a power-up command, the gas sensor ramps up according to a manufacturer defined profile.  The Preheat 1, Preheat 2, and Automatic messages are regions within this profile in exhaust ...";
CM_ SG_ 2565870078 Snsr1HtrPreliminaryFMI "Used to identify the applicable J1939-73 FMI detected in the heater of the outlet exhaust gas sensor, either NOx or O2, by the manufacturer’s sensor control software in exhaust bank 2.  In the case of multiple failures the most severe is ...";
CM_ SG_ 2565870078 WRPercentO21ReadingStable "Indicates that the percent oxygen reading of the aftertreatment outlet gas sensor, either NOx or O2, is stable as determined by the manufacturer's control software in exhaust bank 2.
For a single exhaust bank system, refer to parameters in PGNs ...";
CM_ SG_ 2565870078 NOx1ReadingStable "Indicates that the NOx reading of the aftertreatment outlet NOx sensor is stable as determined by the manufacturer's control software in exhaust bank 2.
For a single exhaust bank system, refer to parameters in PGNs 61454, 61455,  64946, 64947, ...";
CM_ SG_ 2565870078 NOxSnsr1SelfDiagSt "Self-diagnosis result status for NOx sensor ATO2 (Aftertreatment Outlet Bank 2)
000b = Diagnosis not active
001b = NOx Sensor ATO2 Self-diagnosis active flag
010b = NOx Sensor ATO2 Self-diagnosis Result Complete
011b = NOx Sensor ATO2 ...";
CM_ SG_ 2565870078 Snsr1AtTemp "Indicates that the heater element of the aftertreatment outlet gas sensor, either NOx or O2, is within the manufacturer's specified range for accurate measurements in exhaust bank 2.
For a single exhaust bank system, refer to parameters in PGNs ...";
CM_ SG_ 2565870078 Snsr1PwrInRange "Indicates that the power supplied to the aftertreatment outlet gas sensor, either NOx or O2, is within the manufacturer's specification in exhaust bank 2.
For a single exhaust bank system, refer to parameters in PGNs 61454, 61455,  64946, 64947, ...";
CM_ SG_ 2565870078 PercentO21 "The actual oxidation factor (percent oxygen) of the gas within the exhaust stream.  For positive values, the parameter represents the percent oxygen in excess of the amount required for stoichiometric combustion.  For negative values, the parameter ...";
CM_ SG_ 2565870078 NOx1 "The amount of combined NO and NO2 in the exhaust entering the aftertreatment system measured by a NOx sensor at the aftertreatment outlet, represented in NOx molecule parts per million non-NOx molecules in exhaust bank 2.
For a single exhaust bank ...";
CM_ BO_ 2566762750 "Aftertreatment 2 Outlet Gas 2
The purpose of this PG is to group the aftertreatment outlet gas temperature messages for bank 2.";
CM_ SG_ 2566762750 DPFExhTempPreliminaryFMI "Used to identify the applicable J1939-73 FMI detected in the diesel particulate filter outlet temperature sensor by the manufacturer’s sensor control software in exhaust bank 2.  In the case of multiple failures the most severe is communicated.
A ...";
CM_ SG_ 2566762750 ExhTemp3PreliminaryFMI "Used to identify the applicable J1939-73 FMI detected in the exhaust temperature 3 sensor by the manufacturer’s sensor control software in exhaust bank 2.  In the case of multiple failures the most severe is communicated.
A value of 31 is sent to ...";
CM_ SG_ 2566762750 DPFOutTemp "Temperature of engine combustion byproducts leaving the diesel particulate filter exhaust in exhaust bank 2.  (For a single exhaust bank system, refer to parameters in PGNs 61454, 61455,  64946, 64947, 64948, and 65247)";
CM_ SG_ 2566762750 ExhTemp3 "The reading from the exhaust temperature sensor located farthest downstream in the aftertreatment system in exhaust bank 2.  (For a single exhaust bank system, refer to parameters in PGNs 61454, 61455,  64946, 64947, 64948, and 65247)";
CM_ BO_ 2566748926 "Aftertreatment 2 Service 1
This PG contains information about the aftertreatment 2 (diesel particulate filter 2 soot and ash load).";
CM_ SG_ 2566748926 DPFSootLoadRegenThld "This parameter indicates the value that will first cause DPF regeneration in aftertreatment 2. There may be multiple parameters that cause DPF regeneration (e.g. Percent Soot Load, DPF delta pressure converted to normalized percentage, etc.).  If ...";
CM_ SG_ 2566748926 DPFTimeSinceLastActiveRegen "Indicates the time since the last active regeneration event of diesel particulate filter 2.";
CM_ SG_ 2566748926 DPFAshLoadPercent "Indicates the ash load percent of diesel particulate filter 2.  100% is the level at which diesel particulate filter ash service should be performed.
100% level is the target ash service interval (and if ash service is not immediately performed, ...";
CM_ SG_ 2566748926 DPFSootLoadPercent "Indicates the soot load percent of diesel particulate filter 2.  100% is the level at which active diesel particulate filter regeneration should be triggered.
100% level is the active regeneration trigger level (and if conditions are not favorable ...";
CM_ BO_ 2566748414 "Aftertreatment 2 Trip Information
This PG contains trip total information about the aftertreatment 2.  

NOTE: The SPs in this PG need to be reset by the Reset PG (PGN 56832).";
CM_ SG_ 2566748414 DPFTripNumOfActiveRegenManReq "Total number of aftertreatment 2 diesel particulate filter active regeneration manual requests by the operator during the current trip period.

NOTE: This SP needs to be reset by the Reset PG (PGN 56832).";
CM_ SG_ 2566748414 DPFTripNumOfActiveRegenInhReq "Total number of aftertreatment 2 diesel particulate filter active regeneration inhibit requests by the operator during the current trip period.

NOTE: This SP needs to be reset by the Reset PG (PGN 56832).";
CM_ SG_ 2566748414 DPFTripNumOfPassiveRegens "Total number of passive regenerations of the aftertreatment 2 diesel particulate filter during the current trip period.

NOTE: This SP needs to be reset by the Reset PG (PGN 56832).";
CM_ SG_ 2566748414 DPFTripPassiveRegenTime "Total amount of time that the aftertreatment 2 diesel particulate filter has been in passive regeneration during the current trip period.

NOTE: This SP needs to be reset by the Reset PG (PGN 56832).";
CM_ SG_ 2566748414 DPFTripNumOfActiveRegens "Total number of active regenerations of the aftertreatment 2 diesel particulate filter during the current trip period.

NOTE: This SP needs to be reset by the Reset PG (PGN 56832).";
CM_ SG_ 2566748414 DPFTripDisabledTime "Total amount of time that aftertreatment 2 diesel particulate filter regeneration has been manually disabled during the current trip period.

NOTE: This SP needs to be reset by the Reset PG (PGN 56832).";
CM_ SG_ 2566748414 DPFTripActiveRegenTime "Total amount of time that the aftertreatment 2 diesel particulate filter has been in active regeneration during the current trip period.

NOTE: This SP needs to be reset by the Reset PG (PGN 56832).";
CM_ SG_ 2566748414 DPFTripFuelUsed "Total amount of fuel used by the aftertreatment 2 diesel particulate filter during the current trip period.

NOTE: This SP needs to be reset by the Reset PG (PGN 56832).";
CM_ BO_ 2365428478 "Engine Operating Information
Contains engine parameters related to operation.";
CM_ SG_ 2365428478 EngDesiredTorqueRq "This is the torque that the ECM desires to provide. It is a request made from the ECM to an external system. A valid value within the operating range indicates the engine is requesting an external controller to change the operation of the system so ...";
CM_ SG_ 2365428478 EngColdAmbientElevatedIdleStatus "Indicates that the engine is elevating the idle speed due to cold strategies.

00b = No Idle Elevation Active - standard idle speed
01b = Idle Elevation Active
10b = Reserved for SAE assignment
11b = Unavailable";
CM_ SG_ 2365428478 EngStarterMotorRelayCtrl "Command signal used to energize or de-energize the engine starter motor relay.

00b = Off
01b = On
10b = Reserved for SAE assignment
11b = Don't care/take no action";
CM_ SG_ 2365428478 EngDerateRq "This parameter is a derate request made from the engine control system to an external system, where the engine is requesting an external device to reduce the load being applied.  A zero value indicates that there is no derate being requested and ...";
CM_ SG_ 2365428478 EngEmergencyShutdownIndication "A signal issued by the engine control system to a user or external system indicating that it is immediately shutting the engine down.  This indication is made when engine protection diagnostics determine a condition necessitates an immediate ...";
CM_ SG_ 2365428478 EngControlledShutdownRq "A signal issued by the engine control system to a user or external system requesting for a controlled shutdown.  This request is made when engine protection diagnostics determine a condition warrants a shutdown soon, but it is not severe enough to ...";
CM_ SG_ 2365428478 EngCoolantCirculatingPumpCtrl "Control setting for an electrically actuated engine coolant circulating pump. 

00b = Off
01b = On
10b = Reserved
11b = Don't care / take no action
.";
CM_ SG_ 2365428478 EngBlock_CoolantPreheaterCtrl "Control setting for an electrically actuated engine block or coolant pre-heating device.

00b = Off 
01b = On
10b = Reserved
11b = Unavailable";
CM_ SG_ 2365428478 EngElctrclSystmPwrCnsrvationCtrl "Control setting for cutting power to various devices when the engine is not in use.  Useful if it is desired to keep the engine in standby, with main control ECU still powered on and communictaing with outside world, but actuators and certain other ...";
CM_ SG_ 2365428478 EngOilPreheaterCtrl "Control setting for an electrically actuated oil pre-heating device.
00b = Off
01b = On
10b = Reserved
11b = Don't care / take no action
In addition to communicating desired action of the electrically actuated oil pre-heater and its driver ...";
CM_ SG_ 2365428478 EngOilPrimingPumpCtrl "This control is used to activate a pump that lubricates the engine, particularly prior to initial engine startup.

00b = Off
01b = On
10b = Reserved
11b = unavailable";
CM_ SG_ 2365428478 EngFuelShutoffValveLeakTestCtrl "Control setting for fuel shutoff valve proving system test.  Typically, this type of system can only be used with a dual fuel shutoff system.  The test consists of a small pump to pressurize the chamber between the dual fuel shutoffs when they are ...";
CM_ SG_ 2365428478 EngFuelShutoff2Ctrl "Control setting for fuel shutoff 2.  First instance is SPN 632.  For a dual fuel shutoff system, this SP is representative of the downstream fuel shutoff commanded position.  When fuel (gas) is desired at the engine, the fuel shutoff is opened ...";
CM_ SG_ 2365428478 EngFuelShutoff1Ctrl "Control setting for fuel shutoff 1.  The second instance is SPN 2807.  For a single fuel shutoff system, this represents its commanded position.  For a dual fuel shutoff system, this SP is representative of the upstream fuel shutoff commanded ...";
CM_ SG_ 2365428478 EngFuelShutoffVentCtrl "Control setting for a fuel shutoff vent.  Typically, for a dual fuel shutoff system, the vent line is located between them and is plumbed to vent outside to atmosphere.  The vent control typically always actuates opposite to that of the fuel ...";
CM_ SG_ 2365428478 TimeRemainingInEngOperatingState "This parameter is used to indicate the time remaining in the current engine operating state, based on the state defined in the SP \"Engine Operating State\" (SPN 3543). For the states in which time remaining is not applicable, use 65535 (FFFFh).";
CM_ SG_ 2365428478 FuelPumpPrimerCtrl "Parameter used to activate or deactivate a priming system on the fuel transfer system. The fuel priming system is a system that purges air in the fuel lines and may assist fuel delivery to a second pump at lower speeds.
00b = Deactivate
01b = ...";
CM_ SG_ 2365428478 EngOperatingState "This parameter is used to indicate the current state, or mode, of operation by the engine.  This is a status parameter.
0000b = Engine Stopped
0001b = Pre-Start
0010b = Starting
0011b = Warm-Up
0100b = Running
0101b = Cool-down
0110b = Engine ...";
CM_ BO_ 2566743806 "Engine Temperature 4
Engine temperatures";
CM_ SG_ 2566743806 EngCoolantTemp3 "Third temperature of liquid found in the engine cooling system. See also SPNs 110, 4076 and 4193.";
CM_ SG_ 2566743806 EngExhstGsRcrcltn1MxerIntakeTemp "The temperature of the EGR gas entering the intake mixer, measured after the intake throttle when provided.";
CM_ SG_ 2566743806 EngExhstVlvActationSystemOilTemp "The temperature of the oil in the hydraulic system that powers the engine exhaust valve actuation system";
CM_ SG_ 2566743806 EngCoolantThermostatOpening "The current position of the Thermostat used to regulate the temperature of the engine coolant.  0% represents the thermostat allows flow to completely bypass the radiator and 100% represents the flow is fully through the radiator.";
CM_ SG_ 2566743806 EngCoolantPumpOutletTemp "The actual value of engine coolant temperature at the coolant pump outlet.  See also SPNs 110, 4076 and 6209 for additional coolant temperature parameters.";
CM_ SG_ 2566743806 EngCoolantTemp2 "Second temperature of liquid found in the engine cooling system.  See SPNs 110, 4193 and 6209 for additional coolant temperature parameters.

See SPN 22743 for alternate range and resolution.";
CM_ BO_ 2499635454 "Gross Combination Vehicle Weight
Gross Combination Vehicle Weight
See Appendix D - PGN 64872 for details and an example of the transmission rate.
In systems developed to the standard published before March 2017, this message might not be ...";
CM_ SG_ 2499635454 NetVehicleWeightChange "Identifies the net vehicle weight change from the time of last vehicle net weight zeroing.";
CM_ SG_ 2499635454 GrossCombinationWeight "Total weight of the truck and all the trailers as determined via on-board scales or performance based calculation.
Note:  A parameter specific indicator value of FB0000h indicates that this parameter is supported, but conditions are such that a ...";
CM_ BO_ 2550660862 "General Purpose Valve Pressure
The measured load sense pressure and pilot pressure of a valve.  May also include the load sense and supply pressure for a valve assembly, when available.";
CM_ SG_ 2550660862 PilotPressSw "Switch signal that monitors the hydraulic pilot pressure for controls, such as levers and pedals, for the non electrohydraulic system. On indicates one or more of the controls is active.

00b = Off
01b = On
10b = Error
11b = Not available";
CM_ SG_ 2550660862 ValveAssemblySupplyPress "Pressure of the hydraulic supply port to a valve assembly.";
CM_ SG_ 2550660862 ValveAssemblyLoadSensePress "The maximum pressure of a valve assembly's current collective load sense pressures where a valve assembly can consist of two or more valves.";
CM_ SG_ 2550660862 ValvePilotPress "Pressure of a valve's pilot supply port.";
CM_ SG_ 2550660862 ValveLoadSensePress "The maximum of the currently measured pressures of a valve's work port A and work port B.";
CM_ BO_ 2566805758 "Air Suspension Control 4
Used for bellow pressure information";
CM_ SG_ 2566805758 BellowPressRearAxleRight "Information of the pressure of the air suspension bellow at the right side of the rear axle";
CM_ SG_ 2566805758 BellowPressRearAxleLeft "Information of the pressure of the air suspension bellow at the left side of the rear axle";
CM_ SG_ 2566805758 BellowPressFrontAxleRight "Information of the pressure of the air suspension bellow at the right side of the front axle";
CM_ SG_ 2566805758 BellowPressFrontAxleLeft "Information of the pressure of the air suspension bellow at the left side of the front axle";
CM_ BO_ 2566806014 "Air Suspension Control 3
Used for height information";
CM_ SG_ 2566806014 RelativeLevelRearAxleRight "Information of the height at the left side of the rear axle referred to normal level 1.  For explanations of normal level 1 see parameter SPN 1734 - Nominal Level Front Axle.";
CM_ SG_ 2566806014 RelativeLevelRearAxleLeft "Information of the height at the left side of the rear axle referred to normal level 1.  For explanations of normal level 1 see parameter SPN 1734 - Nominal Level Front Axle.";
CM_ SG_ 2566806014 RelativeLevelFrontAxleRight "Information of the height at the right side of the front axle referred to normal level 1.  For explanations of normal level 1 see SPN 1734 - Nominal Level Front Axle.";
CM_ SG_ 2566806014 RelativeLevelFrontAxleLeft "Information of the height at the left side of the front axle referred to normal level 1.  For explanations of normal level 1 see SPN 1734 - Nominal Level Front Axle.";
CM_ BO_ 2362638078 "Air Suspension Control 2
Used for suspension control";
CM_ SG_ 2362638078 MemoryLevelRq "Signal which indicates that the air suspension control requests a memory level or a memory level shall be stored.
The storage of  the current memory level is requested by  \"Store memory level x\". The acknowledge is set in \"memory level x stored\" ...";
CM_ SG_ 2362638078 PrhbitAutomaticAirSuspensionCtrl "This parameter is an internal request to the air suspension control system to prohibit automatic air suspension control.  If the request is accepted,  response intended to be sent in  ASC1 (additional status requested in ASC1), there will be no ...";
CM_ SG_ 2362638078 SpeedDependentLevelCtrlRq "This parameter activates speed dependent level control in suspension system.

00b = Deactivate
01b = Activate
10b = Reserved
11b = Don't care/take no action";
CM_ SG_ 2362638078 AllowLevelCtrlDuringBrakingCmd "This parameter overides the inhibit of level control during braking.

00b = Disallow level control during braking (normal operation)
01b = Allow level control during braking
10b = Reserved
11b = Don't' care/take no action";
CM_ SG_ 2362638078 ProhibitAirSuspensionCtrl "This parameter is an external request to the air suspension control system to prohibit all air suspension control.  If the request is accepted,  response intended to be sent in  ASC1 (additional status requested in ASC1), there will be no control ...";
CM_ SG_ 2362638078 KneelingCmdRearAxle "Command signal to activate the kneeling functionality at the rear axle of the vehicle.

00b = Deactivate kneeling
01b = Activate kneeling
10b = Reserved
11b = Don't care/take no action";
CM_ SG_ 2362638078 KneelingCmdFrontAxle "Command signal to activate the kneeling functionality at the front axle of the vehicle

00b = Deactivate kneeling
01b = Activate kneeling
10b = Reserved
11b = Don't care/take no action";
CM_ SG_ 2362638078 DamperStiffnessRqLift_TagAxle "Demand value for the shock absorber control at the lift or tag axle";
CM_ SG_ 2362638078 DamperStiffnessRqRearAxle "Demand value for the shock absorber control at the rear  axle.";
CM_ SG_ 2362638078 DamperStiffnessRqFrontAxle "Demand value for the shock absorber control at the front axle.";
CM_ SG_ 2362638078 LiftAxle2PosCmd "Signal to command the position / load condition of lift / tag axle #2.  Numbering of lift/tag axles starts at front axle.
00b = Lift axle position down / tag axle laden
01b = Lift axle position up / tag axle unladen
10b = Reserved
11b = Don't ...";
CM_ SG_ 2362638078 LiftAxle1PosCmd "Signal to command the position/load condition of lift/tag axle #1.  Numbering of lift/tag axles starts at front axle.
00b = Lift axle position down / tag axle laden
01b = Lift axle position up / tag axle unladen
10b = Reserved
11b = Don't ...";
CM_ SG_ 2362638078 LevelCtrlModeRq "Command signal to activate a level control mode
0000b = Normal operation; i.e. the system performs a \"pure\" control of the vehicle height
0001b = Traction help (load transfer); i.e. the driven axle is loaded to a maximum value given by legislation ...";
CM_ SG_ 2362638078 NominalLevelRqRearAxle "Command signal to activate a level of the rear axle programmed and/or memorized in the ECU.  For explanations of nominal level see SPN 1734 - Nominal Level Front Axle.
0000b = No level request
0001b = Normal Level 1,(i.e. the level prescribed for ...";
CM_ SG_ 2362638078 NominalLevelRqFrontAxle "Command signal to activate a level of the front axle programmed and/or memorized in the ECU   For explanations of nominal level see SPN 1734 - Nominal Level Front Axle.
0000b = No level request
0001b = Normal Level 1,(i.e. the level prescribed for ...";
CM_ SG_ 2362638078 KneelingCtrlModeRq "Command signal to select the kneeling functionality

00b = Automatically actuated
01b = Manually actuated
10b = Reserved
11b = Don't care/take no action";
CM_ SG_ 2362638078 KneelingRqRightSide "Command signal to activate the kneeling functionality on the right side of the vehicle

00b = No kneeling request
01b = Kneeling request
10b = Reserved
11b = Don't care/take no action";
CM_ SG_ 2362638078 KneelingRqLeftSide "Command signal to activate the kneeling functionality on the left side of the vehicle

00b = No kneeling request
01b = Kneeling request
10b = Reserved
11b = Don't care/take no action";
CM_ SG_ 2362638078 AutomaticTractionHelp "This signal enables the traction help (load transfer) in case of an active ASR function

00b = Disable automatic traction help 
01b = Enable automatic traction help 
10b = Reserved
11b = Don't care";
CM_ BO_ 2365479678 "Air Suspension Control 1
Used for suspension control  information";
CM_ SG_ 2365479678 MemoryLevel "Signal which indicates that the air suspension control has memory levels selected or stored.
Response to memory level request in ASC2 (byte 8.5). If the request was executed the respective status will be set. If the request was not executed ...";
CM_ SG_ 2365479678 SuspensionCtrlRefusalInformation "Signal which indicates that the air suspension control cannot perform a request due to the operating conditions. It also provides a reason for the refusal.
0000b = Actual request not refused
0001b = Axle load limit reached  (load transfer)
0010b ...";
CM_ SG_ 2365479678 SpeedDependantLevelCtrlStatus "This parameter indicates if the function Speed Dependant Level Control is active. The function is activated by SPN 5295.

00b = Inactive
01b = Active
10b = Reserved
11b = Don't' care/take no action";
CM_ SG_ 2365479678 AllwLevelCtrlDuringBrakingStatus "This parameter indicates if the function Allow Level Control During Braking is active. Functions is activated by SPN 5293.

00b = Deactivated
01b = Activated
10b = Reserved
11b = Don't care/take no action";
CM_ SG_ 2365479678 SuspensionRemoteCtrl2 "Signal which indicates that the suspension system is controlled by remote control #2. Remote control is an external unit to operate the suspension system.

00b = Not active
01b = Active
10b = Error
11b = Not available";
CM_ SG_ 2365479678 SuspensionRemoteCtrl1 "Signal which indicates that the suspension system is controlled by remote control #1. Remote control is an external unit to operate the suspension system.

00b = Not active
01b = Active
10b = Error
11b = Not available";
CM_ SG_ 2365479678 LiftAxle2Pos "Signal which indicates the position / load condition of lift axle / tag axle #2.   Numbering of lift/tag axles starts at front axle.  See SPN 6844 for more detail.
00b = Lift axle position down / tag axle laden
01b = Lift axle position up / tag ...";
CM_ SG_ 2365479678 RearAxleInBumperRange "Signal which indicates that the vehicle height at the rear axle (SPNs 1723 and 1724) is within the bumper range.

00b = Actual level out of bumper range
01b = Actual level within bumper range
10b = Error
11b = Not available";
CM_ SG_ 2365479678 FrontAxleInBumperRange "Signal which indicates that the vehicle height at the front axle (SPNs 1721 and 1722) is within the bumper range.

00b = Actual level out of bumper range
01b = Actual level within bumper range
10b = Error
11b = Not available";
CM_ SG_ 2365479678 LiftAxle1Pos "Signal which indicates the position / load condition of lift axle / tag axle 1.   Numbering of lift/tag axles starts at front axle.  See SPN 6843 for more detail.
00b = Lift axle position down / tag axle laden
01b = Lift axle position up / tag ...";
CM_ SG_ 2365479678 DoorRelease "Signal which indicates that the doors may be opened. [Please note: doors instead of door!]
In case a kneeling request is active the ASC indicates during lowering the vehicle \"doors shall not be opened\" as a security information until the kneeling ...";
CM_ SG_ 2365479678 VehicleMotionInhibit "Signal which indicates whether vehicle motion is inhibited.

00b = Vehicle may be moved
01b = Vehicle motion is inhibited
10b = Error
11b = Not available";
CM_ SG_ 2365479678 SecurityDevice "The signal which indicates the status of the security device.  An example of a security device is a curbstone feeler installed beneath the doors of a bus. If the security device becomes active during kneeling the kneeling process (lowering) is ...";
CM_ SG_ 2365479678 LevelCtrlMode "Signal which indicates the actual control mode of the air suspension system
0000b = Normal operation; i.e. the system performs a \"pure\" control of the vehicle height
0001b = Traction help (load transfer); i.e. the driven axle is loaded to a ...";
CM_ SG_ 2365479678 KneelingInformation "Signal which indicates the actual level change in case of kneeling function
0000b = Not active,(i.e. the kneeling function is not active\")
0001b = Lowering active,(i.e. the vehicle is lowered due to a kneeling request)
0010b = Kneeling level ...";
CM_ SG_ 2365479678 LiftingCtrlModeRearAxle "Signal which indicates the actual lifting level change at the rear axle

00b = Lifting not active
01b = Lifting active
10b = Error
11b = Not available";
CM_ SG_ 2365479678 LiftingCtrlModeFrontAxle "Signal which indicates the actual lifting level change at the front axle

00b = Lifting not active
01b = Lifting active
10b = Error
11b = Not available";
CM_ SG_ 2365479678 LoweringCtrlModeRearAxle "Signal which indicates the actual lowering level change at the rear axle

00b = Lowering not active
01b = Lowering active
10b = Error
11b = Not available";
CM_ SG_ 2365479678 LoweringCtrlModeFrontAxle "Signal which indicates the actual lowering level change at the front axle

00b = Lowering not active
01b = Lowering active
10b = Error
11b = Not available";
CM_ SG_ 2365479678 AboveNominalLevelRearAxle "Signal which indicates whether the actual height of the rear axle is above the nominal (desired) level of the rear axle. For explanations of nominal level see parameter SPN 1734 - Nominal Level Front Axle.
00b = Not above
01b = Above
10b = Error
 ...";
CM_ SG_ 2365479678 AboveNominalLevelFrontAxle "Signal which indicates whether the actual height of the front axle is above the nominal (desired) level of the front axle. For explanations of nominal level see SPN 1734 - Nominal Level Front Axle.
00b = Not above
01b = Above
10b = Error
11b = ...";
CM_ SG_ 2365479678 BelowNominalLevelRearAxle "Signal which indicates whether the actual height of the rear axle is below the nominal (desired) level for the rear axle. For explanations of nominal level see SPN 1734 - Nominal Level Front Axle.
00b = Not below
01b = Below
10b = Error
11b = ...";
CM_ SG_ 2365479678 BelowNominalLevelFrontAxle "Signal which indicates whether the actual height of the front axle is below the nominal (desired) level for the front axle. For explanations of nominal level see parameter SPN 1734 - Nominal Level Front Axle.
00b = Not below
01b = Below
10b = ...";
CM_ SG_ 2365479678 NominalLevelRearAxle "Signal which indicates the nominal (desired) height of the rear axle to be controlled by the suspension system.
For further explanations see SPN 1734 - Nominal Level Front Axle.
0000b = Level not specified,(i.e. the nominal level is none of the ...";
CM_ SG_ 2365479678 NominalLevelFrontAxle "Signal which indicates the nominal (desired) height of the front axle to be controlled by the suspension system.
These heights are discrete levels.  They are the upper level, lower level, normal level 1, normal level 2, normal level 3, customer ...";
CM_ BO_ 2566837758 "Alternator Information";
CM_ SG_ 2566837758 Alt4Status "Alternator 4 operating status.

00b = Alternator 4 not charging
01b = Alternator 4 charging
10b = error
11b = not available";
CM_ SG_ 2566837758 Alt3Status "Alternator 3 operating status.

00b = Alternator 3 not charging
01b = Alternator 3 charging
10b = error
11b = not available";
CM_ SG_ 2566837758 Alt2Status "Alternator 2 operating status.

00b = Alternator 2 not charging
01b = Alternator 2 charging
10b = error
11b = not available";
CM_ SG_ 2566837758 Alt1Status "Alternator 1 operating status.

00b = Alternator 1 not charging
01b = Alternator 1 charging
10b = error
11b = not available";
CM_ SG_ 2566837758 AltSpeed "Actual rotation speed of the alternator.";
CM_ BO_ 2633922558 "Auxiliary Pressures";
CM_ SG_ 2633922558 AuxAbsPressReading "Identifies the current absolute pressure (relative to 0 pressure) that is configured uniquely per application.  Not to be used in place of defined parameters.";
CM_ SG_ 2633922558 AuxGagePressReading1 "Identifies the current gage pressure (relative to atmosphere) that is configured uniquely per application.  Not to be used in place of defined parameters.";
CM_ SG_ 2633922558 AuxVacuumPressReading "Identifies the current vacuum pressure (relative to atmosphere) that is configured uniquely per application.  Not to be used in place of defined parameters.";
CM_ BO_ 2566775038 "Ambient Conditions 2
This message contains measurement and configuration information about the vehicle ambient conditions.";
CM_ SG_ 2566775038 BarometricAbsPressHighResolution "Barometric Absolute Pressure (High Resolution).  See SPN 108 if high resolution is not needed.";
CM_ SG_ 2566775038 CalculatedAmbientAirTemp "Calculated temperature of air surrounding vehicle.  Use SPN 171 for actual measured ambient air temperature.";
CM_ SG_ 2566775038 SpecificHumidity "Specific humidity of the ambient intake air.";
CM_ SG_ 2566775038 SolarSensorMax "This is the maximum value which can be reported by the sensor for the solar intensity. (This is a configuration parameter)";
CM_ SG_ 2566775038 SolarIntensityPercent "This is the solar radiation (power density) falling on the vehicle in percent of the maximum sensor value (SPN 2611).  Currently this is in the infra-red spectrum.";
CM_ BO_ 2566836478 "Test Results for Non-continuously Monitored Systems
The purpose of this response PG is to report the test results for one of the non-continuously monitored tests invoked using DM7";
CM_ SG_ 2566836478 TestLimitMinimum "The test value must be greater than or equal to Test Limit Minimum in order for the test to pass.";
CM_ SG_ 2566836478 TestLimitMaximum "The test value must be less than or equal to Test Limit Maximum in order for the test to pass.";
CM_ SG_ 2566836478 TestValue "The test value collected during the test. If the test performed does not have both a test limit minimum and maximum, then the appropriate limit value (Maximum or Minimum) should be set to all ones. SAE J1939-71 defines this to mean not available.";
CM_ SG_ 2566836478 TestType "This parameter identifies the non-continuously monitored component identifier that was tested. These component identifiers are defined by the manufacturer. They are necessary when multiple components or systems are present on the vehicle and have ...";
CM_ SG_ 2566836478 TestIdentifier "The TID has 2 methods to designate the test to be run. The first method uses the TID alone and these test identifiers are manufacturer-defined test identifiers. For this first use there are 64 valid test identifiers, 1 to 64. The second method uses ...";
CM_ BO_ 2565078782 "Command Non-continuously Monitored Test
The purpose of this command in the diagnostic process is to provide the ability to command On-Board Diagnostic monitoring tests of specific components/ systems that are not continuously monitored";
CM_ SG_ 2565078782 SPN1High "SPN #1 (Conversion Version 4)";
CM_ SG_ 2565078782 SPN1 "This parameter identifies the component / system that will be tested.";
CM_ SG_ 2565078782 TestIdentifier "The TID has 2 methods to designate the test to be run. The first method uses the TID alone and these test identifiers are manufacturer-defined test identifiers. For this first use there are 64 valid test identifiers, 1 to 64. The second method uses ...";
CM_ SG_ 2565078782 FailureModeIdentifier1 "This parameter identifies the failure mode identifier which represents the test(s) that shall be run on the component / system that will be tested.";
CM_ BO_ 2566836222 "Pending DTCs
The purpose of this DM is to enable the external test equipment to obtain “pending” diagnostic trouble codes detected during current or last completed driving cycle for emission-related components/systems.";
CM_ SG_ 2566836222 FlashRedStopLamp "This parameter provides the capability to flash the RSL


00 - Slow Flash (1 Hz, 50 % duty cycle)
01 - Fast Flash (2 Hz or faster, 50% duty cycle)
10 - Reserved
11 - Unavailable / Do Not Flash";
CM_ SG_ 2566836222 FlashProtectLamp "This parameter provides the capability to flash the engine protect lamp


00 - Slow Flash (1 Hz, 50 % duty cycle)
01 - Fast Flash (2 Hz or faster, 50% duty cycle)
10 - Reserved
11 - Unavailable / Do Not Flash";
CM_ SG_ 2566836222 FlashMalfuncIndicatorLamp "This parameter provides the capability to flash the MIL
00 - Slow Flash (1 Hz, 50 % duty cycle)
01 - Fast Flash (2 Hz or faster, 50% duty cycle)
10 - Class C DTC
11 - Unavailable / Do Not Flash
Note:  State 10 is for WWH OBD discriminatory ...";
CM_ SG_ 2566836222 FlashAmberWarningLamp "This parameter provides the capability to flash the AWL

00 - Slow Flash (1 Hz, 50 % duty cycle)
01 - Fast Flash (2 Hz or faster, 50% duty cycle)
10 - Reserved
11 - Unavailable / Do Not Flash";
CM_ SG_ 2566836222 MalfunctionIndicatorLampStatus "A lamp used to relay only emissions-related trouble code information. This lamp is only illuminated when there is an emission-related trouble code active.
00     Lamp Off
01     Lamp On
10     Short MIL for WWH OBD
11     Not available
Note ...";
CM_ SG_ 2566836222 RedStopLampState "This lamp is used to relay trouble code information that is of a severe enough condition that it warrants stopping the vehicle.

00     Lamp Off
01     Lamp On
10     Reserved
11     Not available";
CM_ SG_ 2566836222 AmberWarningLampStatus "This lamp is used to relay trouble code information that is reporting a problem with the vehicle system but the vehicle need not be immediately stopped. 

00     Lamp Off
01     Lamp On
10     Reserved
11     Not available";
CM_ SG_ 2566836222 ProtectLampStatus "This lamp is used to relay trouble code information that is reporting a problem with a vehicle system that is most probably not electronic subsystem related. For instance, engine coolant temperature is exceeding its prescribed temperature range.
00 ...";
CM_ SG_ 2566836222 DTC5 "Diagnostic Trouble Code";
CM_ SG_ 2566836222 DTC4 "Diagnostic Trouble Code";
CM_ SG_ 2566836222 DTC3 "Diagnostic Trouble Code";
CM_ SG_ 2566836222 DTC2 "Diagnostic Trouble Code";
CM_ SG_ 2566836222 DTC1 "Diagnostic Trouble Code";
CM_ BO_ 2566835966 "Diagnostic Readiness 1
Reports the diagnostics information that relates to diagnostic readiness.";
CM_ SG_ 2566835966 OBDCompliance "Identifies the OBD compliance capability of the responding controller. Identifies the requirements level to which the controller was built.";
CM_ SG_ 2566835966 PreviouslyActiveTroubleCodes "Identifies the number of previously active trouble codes that are present in a specific controller. If no DTCs have been previously active, this field should be set to zero.";
CM_ SG_ 2566835966 ActiveTroubleCodes "Identifies the number of active trouble codes that are present in a specific controller. If no DTCs are active, this field should be set to zero.";
CM_ BO_ 2566835710 "Freeze Frame Parameters
A freeze frame is defined as the list of recorded parameters at the time a diagnostic trouble code was captured";
CM_ SG_ 2566835710 EngIntakeManifold1Press "The gage pressure measurement of the air intake manifold. If there are multiple air pressure sensors in the intake stream, this is the last one in flow direction before entering the combustion chamber.  This should be the pressure used to drive ...";
CM_ SG_ 2566835710 FreezeFrameLength "The Freeze Frame Length shall be equal to the number of bytes in the required parameters plus the number of bytes in the manufacturer specific parameters.";
CM_ SG_ 2566835710 EngSpeed "Actual engine speed which is calculated over a minimum crankshaft angle of 720 degrees divided by the number of cylinders.";
CM_ SG_ 2566835710 EngTorqueMode "State signal which indicates which engine torque mode is currently generating, limiting, or controlling the torque.  Note that the modes are not in prioritized order. Not all modes may be relevant for a given device.  Some devices may not implement ...";
CM_ SG_ 2566835710 WheelBasedVehicleSpeed "Speed of the vehicle as calculated from wheel or tailshaft speed.";
CM_ SG_ 2566835710 EngPercentLoadAtCurrentSpeed "The ratio of actual engine percent torque (indicated) to maximum indicated torque available at the current engine speed, clipped to zero torque during engine braking.";
CM_ SG_ 2566835710 EngCoolantTemp "Temperature of liquid found in engine cooling system.";
CM_ SG_ 2566835710 DTC1 "Diagnostic Trouble Code";
CM_ BO_ 2566835454 "Diagnostics Data Clear/Reset for Previously Active DTCs";
CM_ BO_ 2566764542 "Expanded Freeze Frame
This message defines the expanded freeze frame length";
CM_ SG_ 2566764542 ExpandedFreezeFrameLength "The Freeze Frame Length is the length plus the number of bytes to convey the data of all parameters (SPNs) in Freeze Frame.";
CM_ SG_ 2566764542 DTC1 "Diagnostic Trouble Code";
CM_ BO_ 2566764286 "SPN Support
This message is used to identify those SPNs supported by the product for freeze frames and data stream messages.";
CM_ SG_ 2566764286 SPNSupported1High "This parameter defines the SPN(s) that is/are supported for the freeze frame and/or data stream information.";
CM_ SG_ 2566764286 SPNSupportTypeSTR3 "This parameter defines whether the applicable parameter (that is the SPN) is supported in the freeze frame, the data stream or both the freeze frame and data stream.";
CM_ SG_ 2566764286 SPNSupportTypeSTR2 "This parameter defines whether the applicable parameter (that is the SPN) is supported in the freeze frame, the data stream or both the freeze frame and data stream.";
CM_ SG_ 2566764286 SPNSupportTypeEFF3 "This parameter defines whether the applicable parameter (that is the SPN) is supported in the freeze frame, the data stream or both the freeze frame and data stream.";
CM_ SG_ 2566764286 SPNSupportTypeEFF2 "This parameter defines whether the applicable parameter (that is the SPN) is supported in the freeze frame, the data stream or both the freeze frame and data stream.";
CM_ SG_ 2566764286 SPNSupportTypeDS3 "This parameter defines whether the applicable parameter (that is the SPN) is supported in the freeze frame, the data stream or both the freeze frame and data stream.";
CM_ SG_ 2566764286 SPNSupportTypeDS2 "This parameter defines whether the applicable parameter (that is the SPN) is supported in the freeze frame, the data stream or both the freeze frame and data stream.";
CM_ SG_ 2566764286 SPNSupported3High "This parameter defines the SPN(s) that is/are supported for the freeze frame and/or data stream information.";
CM_ SG_ 2566764286 SPNSupported2High "This parameter defines the SPN(s) that is/are supported for the freeze frame and/or data stream information.";
CM_ SG_ 2566764286 SPNSupported3 "This parameter defines the SPN(s) that is/are supported for the freeze frame and/or data stream information.";
CM_ SG_ 2566764286 SPNSupported2 "This parameter defines the SPN(s) that is/are supported for the freeze frame and/or data stream information.";
CM_ SG_ 2566764286 SPNDataLength3 "The number of data bytes associated with the SPN in the Freeze Frame.";
CM_ SG_ 2566764286 SPNSupportTypeSTR1 "This parameter defines whether the applicable parameter (that is the SPN) is supported in the Scaled Test Results message, DM30.";
CM_ SG_ 2566764286 SPNSupportTypeDS1 "This parameter defines whether the applicable parameter (that is the SPN) is supported in the Data Stream messages.";
CM_ SG_ 2566764286 SPNSupportTypeEFF1 "This parameter defines whether the applicable parameter (that is the SPN) is supported in the expanded freeze frame message, DM25.";
CM_ SG_ 2566764286 SPNDataLength2 "The number of data bytes associated with the SPN in the Freeze Frame.";
CM_ SG_ 2566764286 SPNDataLength1 "The number of data bytes associated with the SPN in the Freeze Frame.
The SPN data length is required to ensure old and new OBD tool compatibility with vehicle OBD Systems.  For instance, if the vehicle supports a new SPN then the tool will know ...";
CM_ SG_ 2566764286 SPNSupported1 "This parameter defines the SPN(s) that is/are supported for the freeze frame and/or data stream information.";
CM_ BO_ 2566764030 "Previously Active Emission Related Faults
This message contains DTCs that are confirmed but for which the MIL is off.";
CM_ SG_ 2566764030 FlashRedStopLamp "This parameter provides the capability to flash the RSL


00 - Slow Flash (1 Hz, 50 % duty cycle)
01 - Fast Flash (2 Hz or faster, 50% duty cycle)
10 - Reserved
11 - Unavailable / Do Not Flash";
CM_ SG_ 2566764030 FlashProtectLamp "This parameter provides the capability to flash the engine protect lamp


00 - Slow Flash (1 Hz, 50 % duty cycle)
01 - Fast Flash (2 Hz or faster, 50% duty cycle)
10 - Reserved
11 - Unavailable / Do Not Flash";
CM_ SG_ 2566764030 FlashMalfuncIndicatorLamp "This parameter provides the capability to flash the MIL
00 - Slow Flash (1 Hz, 50 % duty cycle)
01 - Fast Flash (2 Hz or faster, 50% duty cycle)
10 - Class C DTC
11 - Unavailable / Do Not Flash
Note:  State 10 is for WWH OBD discriminatory ...";
CM_ SG_ 2566764030 FlashAmberWarningLamp "This parameter provides the capability to flash the AWL

00 - Slow Flash (1 Hz, 50 % duty cycle)
01 - Fast Flash (2 Hz or faster, 50% duty cycle)
10 - Reserved
11 - Unavailable / Do Not Flash";
CM_ SG_ 2566764030 MalfunctionIndicatorLampStatus "A lamp used to relay only emissions-related trouble code information. This lamp is only illuminated when there is an emission-related trouble code active.
00     Lamp Off
01     Lamp On
10     Short MIL for WWH OBD
11     Not available
Note ...";
CM_ SG_ 2566764030 RedStopLampState "This lamp is used to relay trouble code information that is of a severe enough condition that it warrants stopping the vehicle.

00     Lamp Off
01     Lamp On
10     Reserved
11     Not available";
CM_ SG_ 2566764030 AmberWarningLampStatus "This lamp is used to relay trouble code information that is reporting a problem with the vehicle system but the vehicle need not be immediately stopped. 

00     Lamp Off
01     Lamp On
10     Reserved
11     Not available";
CM_ SG_ 2566764030 ProtectLampStatus "This lamp is used to relay trouble code information that is reporting a problem with a vehicle system that is most probably not electronic subsystem related. For instance, engine coolant temperature is exceeding its prescribed temperature range.
00 ...";
CM_ SG_ 2566764030 DTC5 "Diagnostic Trouble Code";
CM_ SG_ 2566764030 DTC4 "Diagnostic Trouble Code";
CM_ SG_ 2566764030 DTC3 "Diagnostic Trouble Code";
CM_ SG_ 2566764030 DTC2 "Diagnostic Trouble Code";
CM_ SG_ 2566764030 DTC1 "Diagnostic Trouble Code";
CM_ BO_ 2562981630 "Individual Clear/Reset Of Active And Previously Active DTC
All of the diagnostic information pertaining to the specified diagnostic trouble code should be erased when the CLR_PA_REQ or CLR_ACT_REQ action of this PG is requested.";
CM_ SG_ 2562981630 SPN1 "DM22 the SPN of the DTC to Clear.";
CM_ SG_ 2562981630 IndividualDTCClearControlByte "DM22 Control byte is used to identify the function being performed by this message.
A numeric indication of the message function and content within the Individual DTC Clear message. The interpretation of these values are shown in the table below.
 ...";
CM_ SG_ 2562981630 CtrlByteIndicIndividualDTCClear "DM22 parameter which is the Negative Acknowledge Indicator For Individual DTC Clear.
A numeric value with interpretation that is specific to the Control Byte Value within the Individual DTC Clear message.  For DM22 Control Byte Values 3 and 19 will ...";
CM_ SG_ 2562981630 FailureModeIdentifier1 "DM22 the FMI of the DTC to Clear.";
CM_ SG_ 2562981630 SPN1High "SPN #1 (Conversion Version 4)";
CM_ BO_ 2562850558 "Diagnostic Readiness 2
Message to convey information relevant to the readiness of the OBD system.";
CM_ SG_ 2562850558 TimeSinceDTCsCleared "Time accumulated since DTCs were cleared (via an external test equipment or possibly, a battery disconnect).";
CM_ SG_ 2562850558 MinutesAccumulatedMILActivated "Accumulated count (in minutes) while the MIL is activated (on).
For US, Euro IV and Euro V implementations, conditions include:
- Reset to 0x0000 when MIL state changes from deactivated to activated by this ECU
- Accumulate counts in minutes if ...";
CM_ SG_ 2562850558 DistanceSinceDTCsCleared "Distance accumulated since DTCs were cleared (via an external test equipment or possibly, a battery disconnect).";
CM_ SG_ 2562850558 DistanceWhileMILisActivated "The kilometers accumulated while the MIL is activated.";
CM_ BO_ 2562916094 "Monitor Performance Ratio
Legislated On-Board Diagnostics requirements specify that manufacturers must monitor all emission and OBD system related components throughout the expected life of the vehicle.";
CM_ SG_ 2562916094 ApplSysMonitorDenominator "Identifies the number of times a vehicle has been operated that constitues a driving cycle where the Applicable System Monitor could be operated per regulatory requirements.";
CM_ SG_ 2562916094 ApplSysMonitorNumerator "Idenitifes the number of times the vehicle has been operated such that all conditions necessary for the Applicable System Monitor to detect a malfunction have been encountered.";
CM_ SG_ 2562916094 SPNofApplSysMonitor "Idenifies the SPN of the system monitor for which Monitor ratio is being reported.";
CM_ SG_ 2562916094 OBDMonitoringCondEncountered "Count the number of times that the vehicle has been operated in the specified OBD monitoring conditions.";
CM_ SG_ 2562916094 IgnitionCycleCounter "Count of the number of ignition cycles.";
CM_ BO_ 2566835198 "Previously Active Diagnostic Trouble Codes
The information communicated is DM service to communicate the previously active trouble codes.";
CM_ SG_ 2566835198 MalfunctionIndicatorLampStatus "A lamp used to relay only emissions-related trouble code information. This lamp is only illuminated when there is an emission-related trouble code active.
00     Lamp Off
01     Lamp On
10     Short MIL for WWH OBD
11     Not available
Note ...";
CM_ SG_ 2566835198 RedStopLampState "This lamp is used to relay trouble code information that is of a severe enough condition that it warrants stopping the vehicle.

00     Lamp Off
01     Lamp On
10     Reserved
11     Not available";
CM_ SG_ 2566835198 AmberWarningLampStatus "This lamp is used to relay trouble code information that is reporting a problem with the vehicle system but the vehicle need not be immediately stopped. 

00     Lamp Off
01     Lamp On
10     Reserved
11     Not available";
CM_ SG_ 2566835198 ProtectLampStatus "This lamp is used to relay trouble code information that is reporting a problem with a vehicle system that is most probably not electronic subsystem related. For instance, engine coolant temperature is exceeding its prescribed temperature range.
00 ...";
CM_ SG_ 2566835198 FlashRedStopLamp "This parameter provides the capability to flash the RSL


00 - Slow Flash (1 Hz, 50 % duty cycle)
01 - Fast Flash (2 Hz or faster, 50% duty cycle)
10 - Reserved
11 - Unavailable / Do Not Flash";
CM_ SG_ 2566835198 FlashProtectLamp "This parameter provides the capability to flash the engine protect lamp


00 - Slow Flash (1 Hz, 50 % duty cycle)
01 - Fast Flash (2 Hz or faster, 50% duty cycle)
10 - Reserved
11 - Unavailable / Do Not Flash";
CM_ SG_ 2566835198 FlashMalfuncIndicatorLamp "This parameter provides the capability to flash the MIL
00 - Slow Flash (1 Hz, 50 % duty cycle)
01 - Fast Flash (2 Hz or faster, 50% duty cycle)
10 - Class C DTC
11 - Unavailable / Do Not Flash
Note:  State 10 is for WWH OBD discriminatory ...";
CM_ SG_ 2566835198 FlashAmberWarningLamp "This parameter provides the capability to flash the AWL

00 - Slow Flash (1 Hz, 50 % duty cycle)
01 - Fast Flash (2 Hz or faster, 50% duty cycle)
10 - Reserved
11 - Unavailable / Do Not Flash";
CM_ SG_ 2566835198 DTC5 "Diagnostic Trouble Code";
CM_ SG_ 2566835198 DTC4 "Diagnostic Trouble Code";
CM_ SG_ 2566835198 DTC3 "Diagnostic Trouble Code";
CM_ SG_ 2566835198 DTC2 "Diagnostic Trouble Code";
CM_ SG_ 2566835198 DTC1 "Diagnostic Trouble Code";
CM_ BO_ 2564030206 "Calibration Information
Provide information about the calibration to scan tool";
CM_ SG_ 2564030206 CalibrationID1 "Sixteen-byte calibration identification number. Uniquely identifies the software installed in the control module. The calibration ID must be unique, but does not need to be 16 bytes long. If the Calibration ID is less than 16 bytes, those unused ...";
CM_ SG_ 2564030206 CalibrationVerificationNumber "Checksum of entire calibration, including code and data.  Excludes RAM parameters, nonvolatile parameters that change during the life cycle of the module (hours of operation, freeze frame data, etc), or non emissions related parameters that may be ...";
CM_ BO_ 2564226814 "Boot Load Data
Used primarily to load boot data/program into a device when a memory access boot load command has been issued.";
CM_ SG_ 2564226814 BootLoadData "This is a 1-byte parameter using the same SLOT as the Raw Binary Data. There shall be 8 occurrences of this parameter in the message. The meaning of this parameter is proprietary. The structure used to reference the program and verify the data is ...";
CM_ BO_ 2564292350 "Binary Data Transfer
Used primarily to transfer data for the memory access commands.";
CM_ SG_ 2564292350 RawBinaryData "This is a 1-byte parameter representing the value for 1 byte of memory. It can have any value between 0 and 255 (0 and 0xFF) with no reserved values.
";
CM_ SG_ 2564292350 NumberOfOccurance "This is an 8-bit (1-byte) parameter to be sent within the Binary Data Transfer PGN to provide information on the number of Raw Binary Data parameters which will follow when the message is single packet. Its value is between 1 and 7 when the Binary ...";
CM_ BO_ 2564357886 "Memory Access Response
The main use for the Memory_Access_Response is for a device to answer a tool which has attempted to access the memory within the device.";
CM_ SG_ 2564357886 NumberAllowed "When the Status of the Memory Access Response message is a Proceed, an 11-bit parameter identifies the amount of memory (i.e. the range of memory) over which the Device is willing to allow a particular operation to be carried out. For ‘Proceed’ the ...";
CM_ SG_ 2564357886 Seed "This is a 16-bit parameter which is used by the Device primarily to send a Seed to a Tool, when using a Seed/Key type security system. It is also used by the Device to signal the Tool that the Device is satisfied that a complete Key has been ...";
CM_ SG_ 2564357886 EDCP_Extension "This is an 8-bit parameter used to identify how to handle the data in the Error Indicator/ EDC Parameter. This EDCP Extension parameter is used within the Memory Access Response message (Device to Tool). Meaning must be determined from a table of ...";
CM_ SG_ 2564357886 ErrorIndicator "This is a 24-bit parameter which has two uses. One is to transfer a checksum, CRC or other type of EDC parameter (or any segment thereof) from a device to a Tool within the Memory Access Response message. The second use is to send an Error Indicator ...";
CM_ SG_ 2564357886 Status "This is a 3-bit parameter which allows the Device to return its Status. All Memory Access Requests originate at a Tool and are considered Commands. All Memory Access Responses originate at a Device and are considered Status. The device may choose to ...";
CM_ BO_ 2564423422 "Memory Access Request
The main use for the Memory_Access_Request message is by a tool wishing to alter the memory of a device.";
CM_ SG_ 2564423422 KeyOrUserLevel "This is a 2-byte parameter which is used by the Tool to primarily send a Key to the Device, but which can also be used by the Tool to provide a Password or a User_Level to the Device if desired (see  APPENDIX C).  This Key/User_Level parameter can ...";
CM_ SG_ 2564423422 PointerExtension "This parameter is either the high order 8 bits of a complete direct memory address or the identifier of a particular spacial address.";
CM_ SG_ 2564423422 Pointer "If Pointer Type 0 is used, this 24-bit parameter, which has a value of 0 to 16,777,215 (0 to 0xFFFFFF) with no reserved ranges, is concatenated with the 8-bit Pointer Extension to form a direct memory address. The address thus formed represents the ...";
CM_ SG_ 2564423422 Command "This is a 3-bit parameter which allows the Tool to send Commands to the Device. All Memory Access Requests originate at a Tool and are considered Commands. Some of the values within the Command have been overlaid with the same values in Status so ...";
CM_ SG_ 2564423422 PointerType "Indicates whether the Pointer and Pointer Extension are direct memory addresses (Pointer Type identifier = 0) or if the Pointer Extension is identifying a particular SPACE with the Pointer referencing a specific OBJECT within that particular SPACE ...";
CM_ SG_ 2564423422 NumberRequested "This is an 11-bit parameter which identifies the amount of memory (i.e. the range within the memory) over which the Tool desires an operation to be carried out when the Command of the Memory Access Request message is a Read, Write, Boot Load, or ...";
CM_ SG_ 2564423422 NumberRequestedHigh "Length/Number Requested";
CM_ BO_ 2564816638 "Stop Start Broadcast
This message is used to stop or start broadcast messages. These broadcast messages may be on networks other than SAE J1939.";
CM_ SG_ 2564816638 ProprietaryNetwork2 "Identifies the action to be performed on the Proprietary Network #2 communications port.

00 Stop Broadcast
01 Start Broadcast
10 Reserved
11 Don’t Care/take no action (leave as is)";
CM_ SG_ 2564816638 ProprietaryNetwork1 "Identifies the action to be performed on the Proprietary Network #1 communications port.

00 Stop Broadcast
01 Start Broadcast
10 Reserved
11 Don’t Care/take no action (leave as is)";
CM_ SG_ 2564816638 J1939Network4 "Identifies the action to be performed on the J1939 Network #4 communications port.

00 Stop Broadcast
01 Start Broadcast
10 Reserved
11 Don’t Care/take no action (leave as is)";
CM_ SG_ 2564816638 HoldSignal "Indicator to all nodes that the communication ports that have been acted upon by the Stop Start Broadcast PGN are remaining in the modified state. Therefore all nodes should act accordingly. The Hold signal is required to be broadcast every 5 ...";
CM_ SG_ 2564816638 J1939Network3 "Identifies the action to be performed on the J1939 Network #3 communications port.

00 Stop Broadcast
01 Start Broadcast
10 Reserved
11 Don’t Care/take no action (leave as is)";
CM_ SG_ 2564816638 J1939Network2 "Identifies the action to be performed on the J1939 Network #2 communications port.

00 Stop Broadcast
01 Start Broadcast
10 Reserved
11 Don’t Care/take no action (leave as is)";
CM_ SG_ 2564816638 ISO9141 "Identifies the action to be performed on the ISO 9141 communications port.

00 Stop Broadcast
01 Start Broadcast
10 Reserved
11 Don’t Care/take no action (leave as is)";
CM_ SG_ 2564816638 SAE_J1850 "Identifies the action to be performed on the J1850 communications port.

00 Stop Broadcast
01 Start Broadcast
10 Reserved
11 Don’t Care/take no action (leave as is)";
CM_ SG_ 2564816638 ManufacturerSpecificPort "Identifies the action to be performed on the “Other, Manufacture Specified Port” communications port.

00 Stop Broadcast
01 Start Broadcast
10 Reserved
11 Don’t Care/take no action (leave as is)";
CM_ SG_ 2564816638 CurrentDataLink "Identifies the action to be performed on the communications port that this parameter was received on.

00 Stop Broadcast
01 Start Broadcast
10 Reserved
11 Don’t Care/take no action (leave as is)";
CM_ SG_ 2564816638 SAE_J1587 "Identifies the action to be performed on the J1587 communications port.

00 Stop Broadcast
01 Start Broadcast
10 Reserved
11 Don’t Care/take no action (leave as is)";
CM_ SG_ 2564816638 SAE_J1922 "Identifies the action to be performed on the J1922 communications port.
00 Stop Broadcast
01 Start Broadcast
10 Reserved
11 Don’t Care/take no action (leave as is)";
CM_ SG_ 2564816638 J1939Network1 "Identifies the action to be performed on the J1939 Network #1, Primary Vehicle Network” communications port.
00 Stop Broadcast
01 Start Broadcast
10 Reserved
11 Don’t Care/take no action (leave as is)";
CM_ SG_ 2564816638 SuspendSignal "Indicator to all nodes that the current communication port broadcast messages are being suspended due to commands other than J1939 DM13. Therefore, the receiving nodes should suspend timeout diagnostics for all messages from the transmitting device ...";
CM_ SG_ 2564816638 SuspendDuration "Indicates the duration of a suspension of broadcast messages when that duration is known by the transmitting device. If the DM13 message is sent with thee suspend signal value of 2 or 3, the value of this parameter will represent the duration of ...";
CM_ BO_ 2566837502 "Emissions Related Active DTCs
The information communicated is limited to the currently active emission-related diagnostic trouble codes preceded by the diagnostic lamp status.";
CM_ SG_ 2566837502 FlashRedStopLamp "This parameter provides the capability to flash the RSL


00 - Slow Flash (1 Hz, 50 % duty cycle)
01 - Fast Flash (2 Hz or faster, 50% duty cycle)
10 - Reserved
11 - Unavailable / Do Not Flash";
CM_ SG_ 2566837502 FlashProtectLamp "This parameter provides the capability to flash the engine protect lamp


00 - Slow Flash (1 Hz, 50 % duty cycle)
01 - Fast Flash (2 Hz or faster, 50% duty cycle)
10 - Reserved
11 - Unavailable / Do Not Flash";
CM_ SG_ 2566837502 MalfunctionIndicatorLampStatus "A lamp used to relay only emissions-related trouble code information. This lamp is only illuminated when there is an emission-related trouble code active.
00     Lamp Off
01     Lamp On
10     Short MIL for WWH OBD
11     Not available
Note ...";
CM_ SG_ 2566837502 RedStopLampState "This lamp is used to relay trouble code information that is of a severe enough condition that it warrants stopping the vehicle.

00     Lamp Off
01     Lamp On
10     Reserved
11     Not available";
CM_ SG_ 2566837502 AmberWarningLampStatus "This lamp is used to relay trouble code information that is reporting a problem with the vehicle system but the vehicle need not be immediately stopped. 

00     Lamp Off
01     Lamp On
10     Reserved
11     Not available";
CM_ SG_ 2566837502 ProtectLampStatus "This lamp is used to relay trouble code information that is reporting a problem with a vehicle system that is most probably not electronic subsystem related. For instance, engine coolant temperature is exceeding its prescribed temperature range.
00 ...";
CM_ SG_ 2566837502 FlashMalfuncIndicatorLamp "This parameter provides the capability to flash the MIL
00 - Slow Flash (1 Hz, 50 % duty cycle)
01 - Fast Flash (2 Hz or faster, 50% duty cycle)
10 - Class C DTC
11 - Unavailable / Do Not Flash
Note:  State 10 is for WWH OBD discriminatory ...";
CM_ SG_ 2566837502 FlashAmberWarningLamp "This parameter provides the capability to flash the AWL

00 - Slow Flash (1 Hz, 50 % duty cycle)
01 - Fast Flash (2 Hz or faster, 50% duty cycle)
10 - Reserved
11 - Unavailable / Do Not Flash";
CM_ SG_ 2566837502 DTC5 "Diagnostic Trouble Code";
CM_ SG_ 2566837502 DTC4 "Diagnostic Trouble Code";
CM_ SG_ 2566837502 DTC3 "Diagnostic Trouble Code";
CM_ SG_ 2566837502 DTC2 "Diagnostic Trouble Code";
CM_ SG_ 2566837502 DTC1 "Diagnostic Trouble Code";
CM_ BO_ 2566837246 "Diagnostic Data Clear/Reset for Active DTCs
All of the diagnostic information pertaining to the active diagnostic trouble codes should be erased. Sent as a request whenever the service tool wishes to clear/reset diagnostic data for active DTCs.";
CM_ BO_ 2566836990 "Non-continuously Monitored System Test Identifiers Support
The purpose of this PG is to report the list of non-continuously monitored systems tests supported by the controller.";
CM_ SG_ 2566836990 TestIdentifierSupported "Indicates the test identifiers that the controller supports. Each bit is assigned to one test. Therefore, we can have up to 64 tests without having to use the transport protocol of SAE J1939-21. The assignment of a given test identifier to a given ...";
CM_ BO_ 2566834942 "Active Diagnostic Trouble Codes
Active Diagnostic Trouble Codes";
CM_ SG_ 2566834942 FlashRedStopLamp "This parameter provides the capability to flash the RSL


00 - Slow Flash (1 Hz, 50 % duty cycle)
01 - Fast Flash (2 Hz or faster, 50% duty cycle)
10 - Reserved
11 - Unavailable / Do Not Flash";
CM_ SG_ 2566834942 FlashProtectLamp "This parameter provides the capability to flash the engine protect lamp


00 - Slow Flash (1 Hz, 50 % duty cycle)
01 - Fast Flash (2 Hz or faster, 50% duty cycle)
10 - Reserved
11 - Unavailable / Do Not Flash";
CM_ SG_ 2566834942 FlashMalfuncIndicatorLamp "This parameter provides the capability to flash the MIL
00 - Slow Flash (1 Hz, 50 % duty cycle)
01 - Fast Flash (2 Hz or faster, 50% duty cycle)
10 - Class C DTC
11 - Unavailable / Do Not Flash
Note:  State 10 is for WWH OBD discriminatory ...";
CM_ SG_ 2566834942 FlashAmberWarningLamp "This parameter provides the capability to flash the AWL

00 - Slow Flash (1 Hz, 50 % duty cycle)
01 - Fast Flash (2 Hz or faster, 50% duty cycle)
10 - Reserved
11 - Unavailable / Do Not Flash";
CM_ SG_ 2566834942 MalfunctionIndicatorLampStatus "A lamp used to relay only emissions-related trouble code information. This lamp is only illuminated when there is an emission-related trouble code active.
00     Lamp Off
01     Lamp On
10     Short MIL for WWH OBD
11     Not available
Note ...";
CM_ SG_ 2566834942 AmberWarningLampStatus "This lamp is used to relay trouble code information that is reporting a problem with the vehicle system but the vehicle need not be immediately stopped. 

00     Lamp Off
01     Lamp On
10     Reserved
11     Not available";
CM_ SG_ 2566834942 RedStopLampState "This lamp is used to relay trouble code information that is of a severe enough condition that it warrants stopping the vehicle.

00     Lamp Off
01     Lamp On
10     Reserved
11     Not available";
CM_ SG_ 2566834942 ProtectLampStatus "This lamp is used to relay trouble code information that is reporting a problem with a vehicle system that is most probably not electronic subsystem related. For instance, engine coolant temperature is exceeding its prescribed temperature range.
00 ...";
CM_ SG_ 2566834942 DTC5 "Diagnostic Trouble Code";
CM_ SG_ 2566834942 DTC4 "Diagnostic Trouble Code";
CM_ SG_ 2566834942 DTC3 "Diagnostic Trouble Code";
CM_ SG_ 2566834942 DTC2 "Diagnostic Trouble Code";
CM_ SG_ 2566834942 DTC1 "Diagnostic Trouble Code";
CM_ BO_ 2365454334 "Utility Total AC Reactive Power
These parameters are intended for stationary Generator/Engine components, not mobile applications.  See \"Motor/Generator\" PGs for electric and hybrid powertrain components.";
CM_ SG_ 2365454334 UtlityOverallPowerFactorLagging "Lead/lag status for utility incomer average power factor.

00b = Leading
01b = Lagging
10b = Error
11b = Not Available or Not Installed";
CM_ SG_ 2365454334 UtilityOverallPowerFactor "The average power factor of the utility incomer.";
CM_ SG_ 2365454334 UtilityTotalReactivePower "The total reactive power delivered by the utility incomer";
CM_ BO_ 2365454590 "Utility Total AC Power
These parameters are intended for stationary Generator/Engine components, not mobile applications.  See \"Motor/Generator\" PGs for electric and hybrid powertrain components.";
CM_ SG_ 2365454590 UtilityTotalApparentPower "The total apparent power delivered by the utility incomer.";
CM_ SG_ 2365454590 UtilityTotalRealPower "Total real power delivered by the utility incomer.";
CM_ BO_ 2365451774 "Utility Total AC Energy
These parameters are intended for stationary Generator/Engine components, not mobile applications.  See \"Motor/Generator\" PGs for electric and hybrid powertrain components.";
CM_ SG_ 2365451774 UtilityTotalKWHoursImport "The total kilowatt-hours that have been imported by the utility incomer.";
CM_ SG_ 2365451774 UtilityTotalKWHoursExport "The total kilowatt-hours that have been exported by the utility incomer.";
CM_ BO_ 2365452030 "Utility Phase C AC Reactive Power
These parameters are intended for stationary Generator/Engine components, not mobile applications.  See \"Motor/Generator\" PGs for electric and hybrid powertrain components.";
CM_ SG_ 2365452030 UtilityPhaseCPowerFactorLagging "Lead/lag status for utility incomer phase C power factor.

00b = Leading
01b = Lagging
10b = Error
11b = Not Available or Not Installed";
CM_ SG_ 2365452030 UtilityPhaseCPowerFactor "The power factor of phases C of the utility incomer.";
CM_ SG_ 2365452030 UtilityPhaseCReactivePower "The reactive power delivered by phase C of the utility incomer";
CM_ BO_ 2365452286 "Utility Phase C AC Power
These parameters are intended for stationary Generator/Engine components, not mobile applications.  See \"Motor/Generator\" PGs for electric and hybrid powertrain components.";
CM_ SG_ 2365452286 UtilityPhaseCApparentPower "The apparent power delivered by phase C of the utility incomer.";
CM_ SG_ 2365452286 UtilityPhaseCRealPower "The real power delivered by phase C of the utility incomer.";
CM_ BO_ 2365452542 "Utility Phase C AC Basic Quantities
These parameters are intended for stationary Generator/Engine components, not mobile applications.  See \"Motor/Generator\" PGs for electric and hybrid powertrain components.";
CM_ SG_ 2365452542 UtilityPhaseCACRMSCurrent "RMS current measured at the utility incomer phase C.";
CM_ SG_ 2365452542 UtilityPhaseCACFrequency "AC frequency measured at the utility incomer phase C.";
CM_ SG_ 2365452542 UtltyPhsCLneNeutralACRMSVoltage "Line to Neutral RMS voltage measured at the utility incomer phase C.";
CM_ SG_ 2365452542 UtltyPhseCALineLineACRMSVoltage "Line to Line RMS voltage measured at the utility incomer phase CA.";
BA_DEF_ SG_  "GenSigInactiveValue" INT 0 0;
BA_DEF_ SG_  "SigType" ENUM  "Default","Range","RangeSigned","ASCII","Discrete","Control","ReferencePGN","DTC","StringDelimiter","StringLength","StringLengthControl","MessageCounter","MessageChecksum";
BA_DEF_ SG_  "GenSigStartValue" INT 0 2147483647;
BA_DEF_ SG_  "GenSigSendType" ENUM  "Cyclic","OnWrite","OnWriteWithRepetition","OnChange","OnChangeWithRepetition","IfActive","IfActiveWithRepetition","NoSigSendType";
BA_DEF_ SG_  "GenSigILSupport" ENUM  "No","Yes";
BA_DEF_ SG_  "SPN" INT 0 524287;
BA_DEF_ BO_  "J1939CPgSendTimeout" INT -1 3600000;
BA_DEF_ BO_  "J1939CPgTOS" INT 0 7;
BA_DEF_ BO_  "J1939PgAppearanceOnBus" ENUM  "Default","CAN_Extended","CANFD_Extended";
BA_DEF_ BO_  "FsJ1939UseCrcAndCounter" STRING ;
BA_DEF_ BO_  "TpJ1939VarDlc" ENUM  "No","Yes";
BA_DEF_ BO_  "GenMsgNrOfRepetition" INT 0 1000000;
BA_DEF_ BO_  "GenMsgCycleTimeFast" INT 0 3600000;
BA_DEF_ BO_  "GenMsgFastOnStart" INT 0 100000;
BA_DEF_ BO_  "GenMsgStartDelayTime" INT 0 100000;
BA_DEF_ BO_  "GenMsgILSupport" ENUM  "No","Yes";
BA_DEF_ BO_  "GenMsgDelayTime" INT 0 1000;
BA_DEF_ BO_  "GenMsgRequestable" INT 0 1;
BA_DEF_ BO_  "GenMsgSendType" ENUM  "cyclic","NotUsed","NotUsed","NotUsed","NotUsed","NotUsed","NotUsed","IfActive","noMsgSendType";
BA_DEF_ BO_  "VFrameFormat" ENUM  "StandardCAN","ExtendedCAN","reserved","J1939PG","reserved","reserved","reserved","reserved","reserved","reserved","reserved","reserved","reserved","reserved","StandardCAN_FD","ExtendedCAN_FD";
BA_DEF_ BO_  "SingleFrame" INT 0 1;
BA_DEF_ BO_  "GenMsgCycleTime" INT 0 3600000;
BA_DEF_ SG_  "SystemSignalLongSymbol" STRING ;
BA_DEF_DEF_  "GenSigInactiveValue" 0;
BA_DEF_DEF_  "SigType" "Default";
BA_DEF_DEF_  "GenSigStartValue" 0;
BA_DEF_DEF_  "GenSigSendType" "NoSigSendType";
BA_DEF_DEF_  "GenSigILSupport" "Yes";
BA_DEF_DEF_  "SPN" 0;
BA_DEF_DEF_  "J1939CPgSendTimeout" -1;
BA_DEF_DEF_  "J1939CPgTOS" 2;
BA_DEF_DEF_  "J1939PgAppearanceOnBus" "Default";
BA_DEF_DEF_  "FsJ1939UseCrcAndCounter" "";
BA_DEF_DEF_  "TpJ1939VarDlc" "No";
BA_DEF_DEF_  "GenMsgNrOfRepetition" 0;
BA_DEF_DEF_  "GenMsgCycleTimeFast" 0;
BA_DEF_DEF_  "GenMsgFastOnStart" 0;
BA_DEF_DEF_  "GenMsgStartDelayTime" 0;
BA_DEF_DEF_  "GenMsgILSupport" "Yes";
BA_DEF_DEF_  "GenMsgDelayTime" 0;
BA_DEF_DEF_  "GenMsgRequestable" 1;
BA_DEF_DEF_  "GenMsgSendType" "noMsgSendType";
BA_DEF_DEF_  "VFrameFormat" "J1939PG";
BA_DEF_DEF_  "SingleFrame" 1;
BA_DEF_DEF_  "GenMsgCycleTime" 0;
BA_DEF_DEF_  "SystemSignalLongSymbol" "";
BA_ "GenMsgSendType" BO_ 2633934846 0;
BA_ "GenMsgCycleTime" BO_ 2633934846 1000;
BA_ "GenMsgCycleTime" BO_ 2362572542 100;
BA_ "GenMsgSendType" BO_ 2365478910 0;
BA_ "GenMsgCycleTime" BO_ 2365478910 100;
BA_ "TpJ1939VarDlc" BO_ 2560950014 1;
BA_ "GenMsgSendType" BO_ 2566763262 0;
BA_ "GenMsgCycleTime" BO_ 2566763262 500;
BA_ "GenMsgSendType" BO_ 2565869566 0;
BA_ "GenMsgCycleTime" BO_ 2565869566 50;
BA_ "GenMsgSendType" BO_ 2566763518 0;
BA_ "GenMsgCycleTime" BO_ 2566763518 500;
BA_ "GenMsgSendType" BO_ 2566758142 0;
BA_ "GenMsgCycleTime" BO_ 2566758142 500;
BA_ "GenMsgSendType" BO_ 2566745342 0;
BA_ "GenMsgCycleTime" BO_ 2566745342 500;
BA_ "GenMsgSendType" BO_ 2566758654 0;
BA_ "GenMsgCycleTime" BO_ 2566758654 500;
BA_ "GenMsgSendType" BO_ 2566753278 0;
BA_ "GenMsgCycleTime" BO_ 2566753278 500;
BA_ "GenMsgSendType" BO_ 2565869822 0;
BA_ "GenMsgCycleTime" BO_ 2565869822 50;
BA_ "GenMsgSendType" BO_ 2566763006 0;
BA_ "GenMsgCycleTime" BO_ 2566763006 500;
BA_ "GenMsgSendType" BO_ 2566762494 0;
BA_ "GenMsgCycleTime" BO_ 2566762494 500;
BA_ "GenMsgSendType" BO_ 2565870078 0;
BA_ "GenMsgCycleTime" BO_ 2565870078 50;
BA_ "GenMsgSendType" BO_ 2566762750 0;
BA_ "GenMsgCycleTime" BO_ 2566762750 500;
BA_ "GenMsgSendType" BO_ 2365428478 0;
BA_ "GenMsgCycleTime" BO_ 2365428478 250;
BA_ "GenMsgSendType" BO_ 2566743806 0;
BA_ "GenMsgCycleTime" BO_ 2566743806 1000;
BA_ "GenMsgDelayTime" BO_ 2499635454 1000;
BA_ "GenMsgSendType" BO_ 2499635454 0;
BA_ "GenMsgCycleTime" BO_ 2499635454 10000;
BA_ "GenMsgSendType" BO_ 2550660862 0;
BA_ "GenMsgCycleTime" BO_ 2550660862 100;
BA_ "GenMsgSendType" BO_ 2566805758 0;
BA_ "GenMsgCycleTime" BO_ 2566805758 100;
BA_ "GenMsgSendType" BO_ 2566806014 0;
BA_ "GenMsgCycleTime" BO_ 2566806014 100;
BA_ "GenMsgSendType" BO_ 2362638078 0;
BA_ "GenMsgCycleTime" BO_ 2362638078 100;
BA_ "GenMsgSendType" BO_ 2365479678 0;
BA_ "GenMsgCycleTime" BO_ 2365479678 100;
BA_ "GenMsgSendType" BO_ 2566837758 0;
BA_ "GenMsgCycleTime" BO_ 2566837758 1000;
BA_ "GenMsgSendType" BO_ 2566775038 0;
BA_ "GenMsgCycleTime" BO_ 2566775038 1000;
BA_ "TpJ1939VarDlc" BO_ 2566836478 1;
BA_ "TpJ1939VarDlc" BO_ 2566836222 1;
BA_ "TpJ1939VarDlc" BO_ 2566835710 1;
BA_ "TpJ1939VarDlc" BO_ 2566764542 1;
BA_ "TpJ1939VarDlc" BO_ 2566764286 1;
BA_ "TpJ1939VarDlc" BO_ 2566764030 1;
BA_ "TpJ1939VarDlc" BO_ 2562916094 1;
BA_ "TpJ1939VarDlc" BO_ 2566835198 1;
BA_ "TpJ1939VarDlc" BO_ 2564030206 1;
BA_ "TpJ1939VarDlc" BO_ 2564226814 1;
BA_ "TpJ1939VarDlc" BO_ 2564292350 1;
BA_ "TpJ1939VarDlc" BO_ 2564423422 1;
BA_ "TpJ1939VarDlc" BO_ 2566837502 1;
BA_ "TpJ1939VarDlc" BO_ 2566834942 1;
BA_ "GenMsgSendType" BO_ 2365454334 0;
BA_ "GenMsgCycleTime" BO_ 2365454334 100;
BA_ "GenMsgSendType" BO_ 2365454590 0;
BA_ "GenMsgCycleTime" BO_ 2365454590 100;
BA_ "GenMsgSendType" BO_ 2365451774 0;
BA_ "GenMsgCycleTime" BO_ 2365451774 100;
BA_ "GenMsgSendType" BO_ 2365452030 0;
BA_ "GenMsgCycleTime" BO_ 2365452030 100;
BA_ "GenMsgSendType" BO_ 2365452286 0;
BA_ "GenMsgCycleTime" BO_ 2365452286 100;
BA_ "GenMsgSendType" BO_ 2365452542 0;
BA_ "GenMsgCycleTime" BO_ 2365452542 100;
BA_ "SigType" SG_ 2633934846 EngAltWinding6Temp 1;
BA_ "SPN" SG_ 2633934846 EngAltWinding6Temp 8465;
BA_ "SigType" SG_ 2633934846 EngAltWinding5Temp 1;
BA_ "SPN" SG_ 2633934846 EngAltWinding5Temp 8464;
BA_ "SigType" SG_ 2633934846 EngAltWinding4Temp 1;
BA_ "SPN" SG_ 2633934846 EngAltWinding4Temp 8463;
BA_ "SigType" SG_ 2633934846 EngAltWinding3Temp 1;
BA_ "SPN" SG_ 2633934846 EngAltWinding3Temp 1126;
BA_ "SigType" SG_ 2633934846 EngAltWinding2Temp 1;
BA_ "SPN" SG_ 2633934846 EngAltWinding2Temp 1125;
BA_ "SigType" SG_ 2633934846 EngAltWinding1Temp 1;
BA_ "SPN" SG_ 2633934846 EngAltWinding1Temp 1124;
BA_ "SigType" SG_ 2633934846 EngAltBearing2Temp 1;
BA_ "SPN" SG_ 2633934846 EngAltBearing2Temp 1123;
BA_ "SigType" SG_ 2633934846 EngAltBearing1Temp 1;
BA_ "SPN" SG_ 2633934846 EngAltBearing1Temp 1122;
BA_ "SigType" SG_ 2362572542 LevelPresetRearAxleRight 1;
BA_ "SPN" SG_ 2362572542 LevelPresetRearAxleRight 1735;
BA_ "SigType" SG_ 2362572542 LevelPresetRearAxleLeft 1;
BA_ "SPN" SG_ 2362572542 LevelPresetRearAxleLeft 1758;
BA_ "SigType" SG_ 2362572542 LevelPresetFrontAxleRight 1;
BA_ "SPN" SG_ 2362572542 LevelPresetFrontAxleRight 1757;
BA_ "SigType" SG_ 2362572542 LevelPresetFrontAxleLeft 1;
BA_ "SPN" SG_ 2362572542 LevelPresetFrontAxleLeft 1732;
BA_ "SigType" SG_ 2365478910 ElctrncShckAbsrbrCtrlMdLft_TgAxl 4;
BA_ "SPN" SG_ 2365478910 ElctrncShckAbsrbrCtrlMdLft_TgAxl 1831;
BA_ "SigType" SG_ 2365478910 ElctrncShckAbsrbrCtrlMdeRearAxle 4;
BA_ "SPN" SG_ 2365478910 ElctrncShckAbsrbrCtrlMdeRearAxle 1832;
BA_ "SigType" SG_ 2365478910 ElctrncShckAbsrbrCtrlMdFrontAxle 4;
BA_ "SPN" SG_ 2365478910 ElctrncShckAbsrbrCtrlMdFrontAxle 1833;
BA_ "SigType" SG_ 2365478910 DamperStiffnessLift_TagAxle 1;
BA_ "SPN" SG_ 2365478910 DamperStiffnessLift_TagAxle 1731;
BA_ "SigType" SG_ 2365478910 DamperStiffnessRearAxle 1;
BA_ "SPN" SG_ 2365478910 DamperStiffnessRearAxle 1730;
BA_ "SigType" SG_ 2365478910 DamperStiffnessFrontAxle 1;
BA_ "SPN" SG_ 2365478910 DamperStiffnessFrontAxle 1729;
BA_ "SPN" SG_ 2560950014 SPN1 1214;
BA_ "SigType" SG_ 2560950014 TestLimitMinimum 1;
BA_ "SPN" SG_ 2560950014 TestLimitMinimum 4112;
BA_ "SPN" SG_ 2560950014 FailureModeIdentifier1 1215;
BA_ "SigType" SG_ 2560950014 TestLimitMaximum 1;
BA_ "SPN" SG_ 2560950014 TestLimitMaximum 4111;
BA_ "SigType" SG_ 2560950014 TestValue 1;
BA_ "SPN" SG_ 2560950014 TestValue 4110;
BA_ "SigType" SG_ 2560950014 SlotId 1;
BA_ "SPN" SG_ 2560950014 SlotId 4109;
BA_ "SPN" SG_ 2566763262 DPFIntmdTempPreliminaryFMI 3254;
BA_ "SPN" SG_ 2566763262 DPFDiffPressPreliminaryFMI 3253;
BA_ "SPN" SG_ 2566763262 ExhTemp2PreliminaryFMI 3252;
BA_ "SigType" SG_ 2566763262 DPFDiffPress 1;
BA_ "SPN" SG_ 2566763262 DPFDiffPress 3251;
BA_ "SigType" SG_ 2566763262 DPFIntmdTemp 1;
BA_ "SPN" SG_ 2566763262 DPFIntmdTemp 3250;
BA_ "SigType" SG_ 2566763262 ExhTemp2 1;
BA_ "SPN" SG_ 2566763262 ExhTemp2 3249;
BA_ "SPN" SG_ 2565869566 O2Snsr1PreliminaryFMI 3235;
BA_ "SPN" SG_ 2565869566 NOxSnsr1SelfDiagSt 5713;
BA_ "SPN" SG_ 2565869566 NOxSnsr1PreliminaryFMI 3234;
BA_ "SigType" SG_ 2565869566 Snsr1HtrCtrl 5;
BA_ "SPN" SG_ 2565869566 Snsr1HtrCtrl 3233;
BA_ "SPN" SG_ 2565869566 Snsr1HtrPreliminaryFMI 3232;
BA_ "SigType" SG_ 2565869566 WRPercentO21ReadingStable 5;
BA_ "SPN" SG_ 2565869566 WRPercentO21ReadingStable 3231;
BA_ "SigType" SG_ 2565869566 NOx1ReadingStable 5;
BA_ "SPN" SG_ 2565869566 NOx1ReadingStable 3230;
BA_ "SigType" SG_ 2565869566 Snsr1AtTemp 5;
BA_ "SPN" SG_ 2565869566 Snsr1AtTemp 3229;
BA_ "SigType" SG_ 2565869566 Snsr1PwrInRange 5;
BA_ "SPN" SG_ 2565869566 Snsr1PwrInRange 3228;
BA_ "SigType" SG_ 2565869566 PercentO21 1;
BA_ "SPN" SG_ 2565869566 PercentO21 3227;
BA_ "SigType" SG_ 2565869566 NOx1 1;
BA_ "SPN" SG_ 2565869566 NOx1 3226;
BA_ "SPN" SG_ 2566763518 DPFOutExhTempPreliminaryFMI 3248;
BA_ "SPN" SG_ 2566763518 ExhTemp3PreliminaryFMI 3247;
BA_ "SigType" SG_ 2566763518 DPFOutTemp 1;
BA_ "SPN" SG_ 2566763518 DPFOutTemp 3246;
BA_ "SigType" SG_ 2566763518 ExhTemp3 1;
BA_ "SPN" SG_ 2566763518 ExhTemp3 3245;
BA_ "SigType" SG_ 2566749182 DPFSootLoadRegenThld 1;
BA_ "SPN" SG_ 2566749182 DPFSootLoadRegenThld 5466;
BA_ "SigType" SG_ 2566749182 DPFTimeSinceLastActiveRegen 1;
BA_ "SPN" SG_ 2566749182 DPFTimeSinceLastActiveRegen 3721;
BA_ "SigType" SG_ 2566749182 DPFAshLoadPercent 1;
BA_ "SPN" SG_ 2566749182 DPFAshLoadPercent 3720;
BA_ "SigType" SG_ 2566749182 DPFSootLoadPercent 1;
BA_ "SPN" SG_ 2566749182 DPFSootLoadPercent 3719;
BA_ "SigType" SG_ 2566748670 DPFTripNumOfActiveRegenManReq 1;
BA_ "SPN" SG_ 2566748670 DPFTripNumOfActiveRegenManReq 3740;
BA_ "SigType" SG_ 2566748670 DPFTripNumOfActiveRegenInhReq 1;
BA_ "SPN" SG_ 2566748670 DPFTripNumOfActiveRegenInhReq 3739;
BA_ "SigType" SG_ 2566748670 DPFTripNumOfPassiveRegens 1;
BA_ "SPN" SG_ 2566748670 DPFTripNumOfPassiveRegens 3738;
BA_ "SigType" SG_ 2566748670 DPFTripPassiveRegenTime 1;
BA_ "SPN" SG_ 2566748670 DPFTripPassiveRegenTime 3737;
BA_ "SigType" SG_ 2566748670 DPFTripNumOfActiveRegens 1;
BA_ "SPN" SG_ 2566748670 DPFTripNumOfActiveRegens 3736;
BA_ "SigType" SG_ 2566748670 DPFTripDisabledTime 1;
BA_ "SPN" SG_ 2566748670 DPFTripDisabledTime 3735;
BA_ "SigType" SG_ 2566748670 DPFTripActiveRegenTime 1;
BA_ "SPN" SG_ 2566748670 DPFTripActiveRegenTime 3734;
BA_ "SigType" SG_ 2566748670 DPFTripFuelUsed 1;
BA_ "SPN" SG_ 2566748670 DPFTripFuelUsed 3733;
BA_ "SigType" SG_ 2566758142 EnableAct 5;
BA_ "SPN" SG_ 2566758142 EnableAct 3503;
BA_ "SigType" SG_ 2566758142 PurgeAirAct 5;
BA_ "SPN" SG_ 2566758142 PurgeAirAct 3504;
BA_ "SigType" SG_ 2566758142 AtomizationAirAct 5;
BA_ "SPN" SG_ 2566758142 AtomizationAirAct 3505;
BA_ "SigType" SG_ 2566758142 SysRelay 5;
BA_ "SPN" SG_ 2566758142 SysRelay 3506;
BA_ "SigType" SG_ 2566758142 PressActPos 1;
BA_ "SPN" SG_ 2566758142 PressActPos 3502;
BA_ "SigType" SG_ 2566758142 PressCtrl 1;
BA_ "SPN" SG_ 2566758142 PressCtrl 3501;
BA_ "SigType" SG_ 2566758142 PurgeAirPress 1;
BA_ "SPN" SG_ 2566758142 PurgeAirPress 3500;
BA_ "SigType" SG_ 2566758142 SupplyAirPress 1;
BA_ "SPN" SG_ 2566758142 SupplyAirPress 3499;
BA_ "SigType" SG_ 2566745342 SecAirPress 1;
BA_ "SPN" SG_ 2566745342 SecAirPress 3838;
BA_ "SigType" SG_ 2566745342 SecAirMFR 1;
BA_ "SPN" SG_ 2566745342 SecAirMFR 3835;
BA_ "SigType" SG_ 2566745342 SecAirTemp 1;
BA_ "SPN" SG_ 2566745342 SecAirTemp 3834;
BA_ "SigType" SG_ 2566745342 SecAirDiffPress 1;
BA_ "SPN" SG_ 2566745342 SecAirDiffPress 3833;
BA_ "SigType" SG_ 2566758654 Injector1HtrCtrl 1;
BA_ "SPN" SG_ 2566758654 Injector1HtrCtrl 4302;
BA_ "SigType" SG_ 2566758654 EnableAct 5;
BA_ "SPN" SG_ 2566758654 EnableAct 3496;
BA_ "SigType" SG_ 2566758654 RegenSt 5;
BA_ "SPN" SG_ 2566758654 RegenSt 3497;
BA_ "SigType" SG_ 2566758654 Ignt 5;
BA_ "SPN" SG_ 2566758654 Ignt 3498;
BA_ "SigType" SG_ 2566758654 DrainAct 5;
BA_ "SPN" SG_ 2566758654 DrainAct 4098;
BA_ "SigType" SG_ 2566758654 Press1Ctrl 1;
BA_ "SPN" SG_ 2566758654 Press1Ctrl 3493;
BA_ "SigType" SG_ 2566758654 Rate 1;
BA_ "SPN" SG_ 2566758654 Rate 3495;
BA_ "SigType" SG_ 2566758654 Press1 1;
BA_ "SPN" SG_ 2566758654 Press1 3494;
BA_ "SigType" SG_ 2566753278 DPFOutPress 1;
BA_ "SPN" SG_ 2566753278 DPFOutPress 3612;
BA_ "SigType" SG_ 2566753278 DPFInPress 1;
BA_ "SPN" SG_ 2566753278 DPFInPress 3611;
BA_ "SigType" SG_ 2566756862 DPFAvgDistBetweenActiveRegens 1;
BA_ "SPN" SG_ 2566756862 DPFAvgDistBetweenActiveRegens 5828;
BA_ "SigType" SG_ 2566756862 DPFAvgTimeBetweenActiveRegens 1;
BA_ "SPN" SG_ 2566756862 DPFAvgTimeBetweenActiveRegens 5455;
BA_ "SigType" SG_ 2566756862 DPFTotalNumOfActiveRegenManReq 1;
BA_ "SPN" SG_ 2566756862 DPFTotalNumOfActiveRegenManReq 3732;
BA_ "SigType" SG_ 2566756862 DPFTotalNumOfActiveRegenInhReq 1;
BA_ "SPN" SG_ 2566756862 DPFTotalNumOfActiveRegenInhReq 3731;
BA_ "SigType" SG_ 2566756862 DPFTotalNumOfPassiveRegens 1;
BA_ "SPN" SG_ 2566756862 DPFTotalNumOfPassiveRegens 3730;
BA_ "SigType" SG_ 2566756862 DPFTotalPassiveRegenTime 1;
BA_ "SPN" SG_ 2566756862 DPFTotalPassiveRegenTime 3729;
BA_ "SigType" SG_ 2566756862 TotalNumOfActiveRegens 1;
BA_ "SPN" SG_ 2566756862 TotalNumOfActiveRegens 3529;
BA_ "SigType" SG_ 2566756862 TotalDisabledTime 1;
BA_ "SPN" SG_ 2566756862 TotalDisabledTime 3528;
BA_ "SigType" SG_ 2566756862 TotalRegenTime 1;
BA_ "SPN" SG_ 2566756862 TotalRegenTime 3527;
BA_ "SigType" SG_ 2566756862 TotalFuelUsed 1;
BA_ "SPN" SG_ 2566756862 TotalFuelUsed 3526;
BA_ "SigType" SG_ 2565869822 TwoGasSnsrPwrSupply 5;
BA_ "SPN" SG_ 2565869822 TwoGasSnsrPwrSupply 8485;
BA_ "SPN" SG_ 2565869822 NOxSnsr1SelfDiagStatus 5716;
BA_ "SPN" SG_ 2565869822 O2Snsr1PreliminaryFMI 3264;
BA_ "SPN" SG_ 2565869822 SCRInNOxSnsr1PreliminaryFMI 3263;
BA_ "SigType" SG_ 2565869822 Snsr1HtrCtrl 5;
BA_ "SPN" SG_ 2565869822 Snsr1HtrCtrl 3262;
BA_ "SPN" SG_ 2565869822 Snsr1HtrPreliminaryFMI 3261;
BA_ "SigType" SG_ 2565869822 WRPercentO21ReadingStable 5;
BA_ "SPN" SG_ 2565869822 WRPercentO21ReadingStable 3260;
BA_ "SigType" SG_ 2565869822 SCRInNOx1ReadingStable 5;
BA_ "SPN" SG_ 2565869822 SCRInNOx1ReadingStable 3259;
BA_ "SigType" SG_ 2565869822 Snsr1AtTemp 5;
BA_ "SPN" SG_ 2565869822 Snsr1AtTemp 3258;
BA_ "SigType" SG_ 2565869822 Snsr1PwrInRange 5;
BA_ "SPN" SG_ 2565869822 Snsr1PwrInRange 3257;
BA_ "SigType" SG_ 2565869822 PercentO21 1;
BA_ "SPN" SG_ 2565869822 PercentO21 3256;
BA_ "SigType" SG_ 2565869822 SCRInNOx1 1;
BA_ "SPN" SG_ 2565869822 SCRInNOx1 3255;
BA_ "SPN" SG_ 2566763006 DPFInTempPreliminaryFMI 3278;
BA_ "SPN" SG_ 2566763006 ExhTemp1PreliminaryFMI 3277;
BA_ "SigType" SG_ 2566763006 DPFInTemp 1;
BA_ "SPN" SG_ 2566763006 DPFInTemp 3276;
BA_ "SigType" SG_ 2566763006 ExhTemp1 1;
BA_ "SPN" SG_ 2566763006 ExhTemp1 3275;
BA_ "SPN" SG_ 2566762494 DPFIntmdTempPreliminaryFMI 3288;
BA_ "SPN" SG_ 2566762494 DPFDiffPressPreliminaryFMI 3287;
BA_ "SPN" SG_ 2566762494 ExhTemp2PreliminaryFMI 3286;
BA_ "SigType" SG_ 2566762494 DPFDiffPress 1;
BA_ "SPN" SG_ 2566762494 DPFDiffPress 3285;
BA_ "SigType" SG_ 2566762494 DPFIntmdTemp 1;
BA_ "SPN" SG_ 2566762494 DPFIntmdTemp 3284;
BA_ "SigType" SG_ 2566762494 ExhTemp2 1;
BA_ "SPN" SG_ 2566762494 ExhTemp2 3283;
BA_ "SigType" SG_ 2565870078 TwoGasSnsrPwrSupply 5;
BA_ "SPN" SG_ 2565870078 TwoGasSnsrPwrSupply 8486;
BA_ "SPN" SG_ 2565870078 O2Snsr1PreliminaryFMI 3274;
BA_ "SPN" SG_ 2565870078 NOxSnsr1PreliminaryFMI 3273;
BA_ "SigType" SG_ 2565870078 Snsr1HtrCtrl 5;
BA_ "SPN" SG_ 2565870078 Snsr1HtrCtrl 3272;
BA_ "SPN" SG_ 2565870078 Snsr1HtrPreliminaryFMI 3271;
BA_ "SigType" SG_ 2565870078 WRPercentO21ReadingStable 5;
BA_ "SPN" SG_ 2565870078 WRPercentO21ReadingStable 3270;
BA_ "SigType" SG_ 2565870078 NOx1ReadingStable 5;
BA_ "SPN" SG_ 2565870078 NOx1ReadingStable 3269;
BA_ "SPN" SG_ 2565870078 NOxSnsr1SelfDiagSt 5715;
BA_ "SigType" SG_ 2565870078 Snsr1AtTemp 5;
BA_ "SPN" SG_ 2565870078 Snsr1AtTemp 3268;
BA_ "SigType" SG_ 2565870078 Snsr1PwrInRange 5;
BA_ "SPN" SG_ 2565870078 Snsr1PwrInRange 3267;
BA_ "SigType" SG_ 2565870078 PercentO21 1;
BA_ "SPN" SG_ 2565870078 PercentO21 3266;
BA_ "SigType" SG_ 2565870078 NOx1 1;
BA_ "SPN" SG_ 2565870078 NOx1 3265;
BA_ "SPN" SG_ 2566762750 DPFExhTempPreliminaryFMI 3282;
BA_ "SPN" SG_ 2566762750 ExhTemp3PreliminaryFMI 3281;
BA_ "SigType" SG_ 2566762750 DPFOutTemp 1;
BA_ "SPN" SG_ 2566762750 DPFOutTemp 3280;
BA_ "SigType" SG_ 2566762750 ExhTemp3 1;
BA_ "SPN" SG_ 2566762750 ExhTemp3 3279;
BA_ "SigType" SG_ 2566748926 DPFSootLoadRegenThld 1;
BA_ "SPN" SG_ 2566748926 DPFSootLoadRegenThld 5467;
BA_ "SigType" SG_ 2566748926 DPFTimeSinceLastActiveRegen 1;
BA_ "SPN" SG_ 2566748926 DPFTimeSinceLastActiveRegen 3724;
BA_ "SigType" SG_ 2566748926 DPFAshLoadPercent 1;
BA_ "SPN" SG_ 2566748926 DPFAshLoadPercent 3723;
BA_ "SigType" SG_ 2566748926 DPFSootLoadPercent 1;
BA_ "SPN" SG_ 2566748926 DPFSootLoadPercent 3722;
BA_ "SigType" SG_ 2566748414 DPFTripNumOfActiveRegenManReq 1;
BA_ "SPN" SG_ 2566748414 DPFTripNumOfActiveRegenManReq 3748;
BA_ "SigType" SG_ 2566748414 DPFTripNumOfActiveRegenInhReq 1;
BA_ "SPN" SG_ 2566748414 DPFTripNumOfActiveRegenInhReq 3747;
BA_ "SigType" SG_ 2566748414 DPFTripNumOfPassiveRegens 1;
BA_ "SPN" SG_ 2566748414 DPFTripNumOfPassiveRegens 3746;
BA_ "SigType" SG_ 2566748414 DPFTripPassiveRegenTime 1;
BA_ "SPN" SG_ 2566748414 DPFTripPassiveRegenTime 3745;
BA_ "SigType" SG_ 2566748414 DPFTripNumOfActiveRegens 1;
BA_ "SPN" SG_ 2566748414 DPFTripNumOfActiveRegens 3744;
BA_ "SigType" SG_ 2566748414 DPFTripDisabledTime 1;
BA_ "SPN" SG_ 2566748414 DPFTripDisabledTime 3743;
BA_ "SigType" SG_ 2566748414 DPFTripActiveRegenTime 1;
BA_ "SPN" SG_ 2566748414 DPFTripActiveRegenTime 3742;
BA_ "SigType" SG_ 2566748414 DPFTripFuelUsed 1;
BA_ "SPN" SG_ 2566748414 DPFTripFuelUsed 3741;
BA_ "SigType" SG_ 2365428478 EngDesiredTorqueRq 1;
BA_ "GenSigStartValue" SG_ 2365428478 EngDesiredTorqueRq 125;
BA_ "SPN" SG_ 2365428478 EngDesiredTorqueRq 6807;
BA_ "SigType" SG_ 2365428478 EngColdAmbientElevatedIdleStatus 5;
BA_ "SPN" SG_ 2365428478 EngColdAmbientElevatedIdleStatus 6884;
BA_ "SigType" SG_ 2365428478 EngStarterMotorRelayCtrl 5;
BA_ "SPN" SG_ 2365428478 EngStarterMotorRelayCtrl 6385;
BA_ "SigType" SG_ 2365428478 EngDerateRq 1;
BA_ "SPN" SG_ 2365428478 EngDerateRq 3644;
BA_ "SigType" SG_ 2365428478 EngEmergencyShutdownIndication 5;
BA_ "SPN" SG_ 2365428478 EngEmergencyShutdownIndication 3607;
BA_ "SigType" SG_ 2365428478 EngControlledShutdownRq 5;
BA_ "SPN" SG_ 2365428478 EngControlledShutdownRq 3606;
BA_ "SigType" SG_ 2365428478 EngCoolantCirculatingPumpCtrl 5;
BA_ "SPN" SG_ 2365428478 EngCoolantCirculatingPumpCtrl 3605;
BA_ "SigType" SG_ 2365428478 EngBlock_CoolantPreheaterCtrl 5;
BA_ "SPN" SG_ 2365428478 EngBlock_CoolantPreheaterCtrl 3604;
BA_ "SigType" SG_ 2365428478 EngElctrclSystmPwrCnsrvationCtrl 5;
BA_ "SPN" SG_ 2365428478 EngElctrclSystmPwrCnsrvationCtrl 3603;
BA_ "SigType" SG_ 2365428478 EngOilPreheaterCtrl 5;
BA_ "SPN" SG_ 2365428478 EngOilPreheaterCtrl 3602;
BA_ "SigType" SG_ 2365428478 EngOilPrimingPumpCtrl 5;
BA_ "SPN" SG_ 2365428478 EngOilPrimingPumpCtrl 3589;
BA_ "SigType" SG_ 2365428478 EngFuelShutoffValveLeakTestCtrl 5;
BA_ "SPN" SG_ 2365428478 EngFuelShutoffValveLeakTestCtrl 3601;
BA_ "SigType" SG_ 2365428478 EngFuelShutoff2Ctrl 5;
BA_ "SPN" SG_ 2365428478 EngFuelShutoff2Ctrl 2807;
BA_ "SigType" SG_ 2365428478 EngFuelShutoff1Ctrl 5;
BA_ "SPN" SG_ 2365428478 EngFuelShutoff1Ctrl 632;
BA_ "SigType" SG_ 2365428478 EngFuelShutoffVentCtrl 5;
BA_ "SPN" SG_ 2365428478 EngFuelShutoffVentCtrl 3608;
BA_ "SigType" SG_ 2365428478 TimeRemainingInEngOperatingState 1;
BA_ "SPN" SG_ 2365428478 TimeRemainingInEngOperatingState 3544;
BA_ "SigType" SG_ 2365428478 FuelPumpPrimerCtrl 5;
BA_ "SPN" SG_ 2365428478 FuelPumpPrimerCtrl 4082;
BA_ "SPN" SG_ 2365428478 EngOperatingState 3543;
BA_ "SigType" SG_ 2566743806 EngCoolantTemp3 1;
BA_ "SPN" SG_ 2566743806 EngCoolantTemp3 6209;
BA_ "SigType" SG_ 2566743806 EngExhstGsRcrcltn1MxerIntakeTemp 1;
BA_ "SPN" SG_ 2566743806 EngExhstGsRcrcltn1MxerIntakeTemp 5020;
BA_ "SigType" SG_ 2566743806 EngExhstVlvActationSystemOilTemp 1;
BA_ "SPN" SG_ 2566743806 EngExhstVlvActationSystemOilTemp 4288;
BA_ "SigType" SG_ 2566743806 EngCoolantThermostatOpening 1;
BA_ "SPN" SG_ 2566743806 EngCoolantThermostatOpening 4194;
BA_ "SigType" SG_ 2566743806 EngCoolantPumpOutletTemp 1;
BA_ "SPN" SG_ 2566743806 EngCoolantPumpOutletTemp 4193;
BA_ "SigType" SG_ 2566743806 EngCoolantTemp2 1;
BA_ "SPN" SG_ 2566743806 EngCoolantTemp2 4076;
BA_ "SPN" SG_ 2499635454 NetVehicleWeightChange 413;
BA_ "SPN" SG_ 2499635454 GrossCombinationWeight 417;
BA_ "SigType" SG_ 2550660862 PilotPressSw 4;
BA_ "SPN" SG_ 2550660862 PilotPressSw 22130;
BA_ "SigType" SG_ 2550660862 ValveAssemblySupplyPress 1;
BA_ "SPN" SG_ 2550660862 ValveAssemblySupplyPress 4089;
BA_ "SigType" SG_ 2550660862 ValveAssemblyLoadSensePress 1;
BA_ "SPN" SG_ 2550660862 ValveAssemblyLoadSensePress 4088;
BA_ "SigType" SG_ 2550660862 ValvePilotPress 1;
BA_ "SPN" SG_ 2550660862 ValvePilotPress 4087;
BA_ "SigType" SG_ 2550660862 ValveLoadSensePress 1;
BA_ "SPN" SG_ 2550660862 ValveLoadSensePress 4086;
BA_ "SigType" SG_ 2566805758 BellowPressRearAxleRight 1;
BA_ "SPN" SG_ 2566805758 BellowPressRearAxleRight 1728;
BA_ "SigType" SG_ 2566805758 BellowPressRearAxleLeft 1;
BA_ "SPN" SG_ 2566805758 BellowPressRearAxleLeft 1727;
BA_ "SigType" SG_ 2566805758 BellowPressFrontAxleRight 1;
BA_ "SPN" SG_ 2566805758 BellowPressFrontAxleRight 1726;
BA_ "SigType" SG_ 2566805758 BellowPressFrontAxleLeft 1;
BA_ "SPN" SG_ 2566805758 BellowPressFrontAxleLeft 1725;
BA_ "SigType" SG_ 2566806014 RelativeLevelRearAxleRight 1;
BA_ "SPN" SG_ 2566806014 RelativeLevelRearAxleRight 1723;
BA_ "SigType" SG_ 2566806014 RelativeLevelRearAxleLeft 1;
BA_ "SPN" SG_ 2566806014 RelativeLevelRearAxleLeft 1724;
BA_ "SigType" SG_ 2566806014 RelativeLevelFrontAxleRight 1;
BA_ "SPN" SG_ 2566806014 RelativeLevelFrontAxleRight 1722;
BA_ "SigType" SG_ 2566806014 RelativeLevelFrontAxleLeft 1;
BA_ "SPN" SG_ 2566806014 RelativeLevelFrontAxleLeft 1721;
BA_ "SPN" SG_ 2362638078 MemoryLevelRq 5433;
BA_ "SigType" SG_ 2362638078 PrhbitAutomaticAirSuspensionCtrl 5;
BA_ "SPN" SG_ 2362638078 PrhbitAutomaticAirSuspensionCtrl 5274;
BA_ "SigType" SG_ 2362638078 SpeedDependentLevelCtrlRq 5;
BA_ "SPN" SG_ 2362638078 SpeedDependentLevelCtrlRq 5295;
BA_ "SigType" SG_ 2362638078 AllowLevelCtrlDuringBrakingCmd 5;
BA_ "SPN" SG_ 2362638078 AllowLevelCtrlDuringBrakingCmd 5293;
BA_ "SigType" SG_ 2362638078 ProhibitAirSuspensionCtrl 5;
BA_ "SPN" SG_ 2362638078 ProhibitAirSuspensionCtrl 3215;
BA_ "SigType" SG_ 2362638078 KneelingCmdRearAxle 5;
BA_ "SPN" SG_ 2362638078 KneelingCmdRearAxle 1829;
BA_ "SigType" SG_ 2362638078 KneelingCmdFrontAxle 5;
BA_ "SPN" SG_ 2362638078 KneelingCmdFrontAxle 1830;
BA_ "SigType" SG_ 2362638078 DamperStiffnessRqLift_TagAxle 1;
BA_ "SPN" SG_ 2362638078 DamperStiffnessRqLift_TagAxle 1720;
BA_ "SigType" SG_ 2362638078 DamperStiffnessRqRearAxle 1;
BA_ "SPN" SG_ 2362638078 DamperStiffnessRqRearAxle 1719;
BA_ "SigType" SG_ 2362638078 DamperStiffnessRqFrontAxle 1;
BA_ "SPN" SG_ 2362638078 DamperStiffnessRqFrontAxle 1718;
BA_ "SigType" SG_ 2362638078 LiftAxle2PosCmd 5;
BA_ "SPN" SG_ 2362638078 LiftAxle2PosCmd 1828;
BA_ "SigType" SG_ 2362638078 LiftAxle1PosCmd 5;
BA_ "SPN" SG_ 2362638078 LiftAxle1PosCmd 1752;
BA_ "SPN" SG_ 2362638078 LevelCtrlModeRq 1753;
BA_ "SPN" SG_ 2362638078 NominalLevelRqRearAxle 1750;
BA_ "SPN" SG_ 2362638078 NominalLevelRqFrontAxle 1751;
BA_ "SigType" SG_ 2362638078 KneelingCtrlModeRq 5;
BA_ "SPN" SG_ 2362638078 KneelingCtrlModeRq 1747;
BA_ "SigType" SG_ 2362638078 KneelingRqRightSide 5;
BA_ "SPN" SG_ 2362638078 KneelingRqRightSide 1748;
BA_ "SigType" SG_ 2362638078 KneelingRqLeftSide 5;
BA_ "SPN" SG_ 2362638078 KneelingRqLeftSide 1749;
BA_ "SigType" SG_ 2362638078 AutomaticTractionHelp 5;
BA_ "SPN" SG_ 2362638078 AutomaticTractionHelp 2984;
BA_ "SPN" SG_ 2365479678 MemoryLevel 5432;
BA_ "SPN" SG_ 2365479678 SuspensionCtrlRefusalInformation 1827;
BA_ "SigType" SG_ 2365479678 SpeedDependantLevelCtrlStatus 5;
BA_ "SPN" SG_ 2365479678 SpeedDependantLevelCtrlStatus 5296;
BA_ "SigType" SG_ 2365479678 AllwLevelCtrlDuringBrakingStatus 5;
BA_ "SPN" SG_ 2365479678 AllwLevelCtrlDuringBrakingStatus 5294;
BA_ "SigType" SG_ 2365479678 SuspensionRemoteCtrl2 4;
BA_ "SPN" SG_ 2365479678 SuspensionRemoteCtrl2 1825;
BA_ "SigType" SG_ 2365479678 SuspensionRemoteCtrl1 4;
BA_ "SPN" SG_ 2365479678 SuspensionRemoteCtrl1 1826;
BA_ "SigType" SG_ 2365479678 LiftAxle2Pos 4;
BA_ "SPN" SG_ 2365479678 LiftAxle2Pos 1822;
BA_ "SigType" SG_ 2365479678 RearAxleInBumperRange 4;
BA_ "SPN" SG_ 2365479678 RearAxleInBumperRange 1823;
BA_ "SigType" SG_ 2365479678 FrontAxleInBumperRange 4;
BA_ "SPN" SG_ 2365479678 FrontAxleInBumperRange 1824;
BA_ "SigType" SG_ 2365479678 LiftAxle1Pos 4;
BA_ "SPN" SG_ 2365479678 LiftAxle1Pos 1743;
BA_ "SigType" SG_ 2365479678 DoorRelease 5;
BA_ "SPN" SG_ 2365479678 DoorRelease 1744;
BA_ "SigType" SG_ 2365479678 VehicleMotionInhibit 5;
BA_ "SPN" SG_ 2365479678 VehicleMotionInhibit 1745;
BA_ "SigType" SG_ 2365479678 SecurityDevice 5;
BA_ "SPN" SG_ 2365479678 SecurityDevice 1746;
BA_ "SPN" SG_ 2365479678 LevelCtrlMode 1741;
BA_ "SPN" SG_ 2365479678 KneelingInformation 1742;
BA_ "SigType" SG_ 2365479678 LiftingCtrlModeRearAxle 5;
BA_ "SPN" SG_ 2365479678 LiftingCtrlModeRearAxle 1756;
BA_ "SigType" SG_ 2365479678 LiftingCtrlModeFrontAxle 5;
BA_ "SPN" SG_ 2365479678 LiftingCtrlModeFrontAxle 1739;
BA_ "SigType" SG_ 2365479678 LoweringCtrlModeRearAxle 5;
BA_ "SPN" SG_ 2365479678 LoweringCtrlModeRearAxle 1755;
BA_ "SigType" SG_ 2365479678 LoweringCtrlModeFrontAxle 5;
BA_ "SPN" SG_ 2365479678 LoweringCtrlModeFrontAxle 1740;
BA_ "SigType" SG_ 2365479678 AboveNominalLevelRearAxle 4;
BA_ "SPN" SG_ 2365479678 AboveNominalLevelRearAxle 1736;
BA_ "SigType" SG_ 2365479678 AboveNominalLevelFrontAxle 4;
BA_ "SPN" SG_ 2365479678 AboveNominalLevelFrontAxle 1737;
BA_ "SigType" SG_ 2365479678 BelowNominalLevelRearAxle 5;
BA_ "SPN" SG_ 2365479678 BelowNominalLevelRearAxle 1754;
BA_ "SigType" SG_ 2365479678 BelowNominalLevelFrontAxle 4;
BA_ "SPN" SG_ 2365479678 BelowNominalLevelFrontAxle 1738;
BA_ "SPN" SG_ 2365479678 NominalLevelRearAxle 1733;
BA_ "SPN" SG_ 2365479678 NominalLevelFrontAxle 1734;
BA_ "SigType" SG_ 2566837758 Alt4Status 4;
BA_ "SPN" SG_ 2566837758 Alt4Status 3356;
BA_ "SigType" SG_ 2566837758 Alt3Status 4;
BA_ "SPN" SG_ 2566837758 Alt3Status 3355;
BA_ "SigType" SG_ 2566837758 Alt2Status 4;
BA_ "SPN" SG_ 2566837758 Alt2Status 3354;
BA_ "SigType" SG_ 2566837758 Alt1Status 4;
BA_ "SPN" SG_ 2566837758 Alt1Status 3353;
BA_ "SigType" SG_ 2566837758 AltSpeed 1;
BA_ "SPN" SG_ 2566837758 AltSpeed 589;
BA_ "SigType" SG_ 2633922558 AuxAbsPressReading 1;
BA_ "SPN" SG_ 2633922558 AuxAbsPressReading 138;
BA_ "SigType" SG_ 2633922558 AuxGagePressReading1 1;
BA_ "SPN" SG_ 2633922558 AuxGagePressReading1 137;
BA_ "SigType" SG_ 2633922558 AuxVacuumPressReading 1;
BA_ "SPN" SG_ 2633922558 AuxVacuumPressReading 136;
BA_ "SigType" SG_ 2566775038 BarometricAbsPressHighResolution 1;
BA_ "SPN" SG_ 2566775038 BarometricAbsPressHighResolution 5685;
BA_ "SigType" SG_ 2566775038 CalculatedAmbientAirTemp 1;
BA_ "SPN" SG_ 2566775038 CalculatedAmbientAirTemp 5581;
BA_ "SigType" SG_ 2566775038 SpecificHumidity 1;
BA_ "SPN" SG_ 2566775038 SpecificHumidity 4490;
BA_ "SigType" SG_ 2566775038 SolarSensorMax 1;
BA_ "SPN" SG_ 2566775038 SolarSensorMax 2611;
BA_ "SigType" SG_ 2566775038 SolarIntensityPercent 1;
BA_ "SPN" SG_ 2566775038 SolarIntensityPercent 2610;
BA_ "SigType" SG_ 2566836478 TestLimitMinimum 1;
BA_ "SPN" SG_ 2566836478 TestLimitMinimum 1228;
BA_ "SigType" SG_ 2566836478 TestLimitMaximum 1;
BA_ "SPN" SG_ 2566836478 TestLimitMaximum 1227;
BA_ "SigType" SG_ 2566836478 TestValue 1;
BA_ "SPN" SG_ 2566836478 TestValue 1226;
BA_ "SigType" SG_ 2566836478 TestType 1;
BA_ "SPN" SG_ 2566836478 TestType 1225;
BA_ "SPN" SG_ 2566836478 TestIdentifier 1224;
BA_ "SPN" SG_ 2565078782 SPN1 4148;
BA_ "SPN" SG_ 2565078782 TestIdentifier 1224;
BA_ "SPN" SG_ 2565078782 FailureModeIdentifier1 4149;
BA_ "SigType" SG_ 2566836222 FlashRedStopLamp 5;
BA_ "SPN" SG_ 2566836222 FlashRedStopLamp 3039;
BA_ "SigType" SG_ 2566836222 FlashProtectLamp 5;
BA_ "SPN" SG_ 2566836222 FlashProtectLamp 3041;
BA_ "SigType" SG_ 2566836222 FlashMalfuncIndicatorLamp 5;
BA_ "SPN" SG_ 2566836222 FlashMalfuncIndicatorLamp 3038;
BA_ "SigType" SG_ 2566836222 FlashAmberWarningLamp 5;
BA_ "SPN" SG_ 2566836222 FlashAmberWarningLamp 3040;
BA_ "SigType" SG_ 2566836222 MalfunctionIndicatorLampStatus 5;
BA_ "SPN" SG_ 2566836222 MalfunctionIndicatorLampStatus 1213;
BA_ "SigType" SG_ 2566836222 RedStopLampState 4;
BA_ "SPN" SG_ 2566836222 RedStopLampState 623;
BA_ "SigType" SG_ 2566836222 AmberWarningLampStatus 5;
BA_ "SPN" SG_ 2566836222 AmberWarningLampStatus 624;
BA_ "SigType" SG_ 2566836222 ProtectLampStatus 5;
BA_ "SPN" SG_ 2566836222 ProtectLampStatus 987;
BA_ "SigType" SG_ 2566836222 DTC5 7;
BA_ "SigType" SG_ 2566836222 DTC4 7;
BA_ "SigType" SG_ 2566836222 DTC3 7;
BA_ "SigType" SG_ 2566836222 DTC2 7;
BA_ "SigType" SG_ 2566836222 DTC1 7;
BA_ "SystemSignalLongSymbol" SG_ 2566835966 NOxConvertingCatalystAdsorberSta "NOxConvertingCatalystAdsorberStatus";
BA_ "SystemSignalLongSymbol" SG_ 2566835966 BoostPressureControlSystemSuppor "BoostPressureControlSystemSupport";
BA_ "SystemSignalLongSymbol" SG_ 2566835966 NOxConvertingCatalystAdsorberSup "NOxConvertingCatalystAdsorberSupport";
BA_ "SigType" SG_ 2566835966 OBDCompliance 1;
BA_ "SPN" SG_ 2566835966 OBDCompliance 1220;
BA_ "SigType" SG_ 2566835966 PreviouslyActiveTroubleCodes 1;
BA_ "SPN" SG_ 2566835966 PreviouslyActiveTroubleCodes 1219;
BA_ "SigType" SG_ 2566835966 ActiveTroubleCodes 1;
BA_ "SPN" SG_ 2566835966 ActiveTroubleCodes 1218;
BA_ "SigType" SG_ 2566835710 EngIntakeManifold1Press 1;
BA_ "SPN" SG_ 2566835710 EngIntakeManifold1Press 102;
BA_ "SPN" SG_ 2566835710 FreezeFrameLength 1217;
BA_ "SigType" SG_ 2566835710 EngSpeed 1;
BA_ "SPN" SG_ 2566835710 EngSpeed 190;
BA_ "SPN" SG_ 2566835710 EngTorqueMode 899;
BA_ "SigType" SG_ 2566835710 WheelBasedVehicleSpeed 1;
BA_ "SPN" SG_ 2566835710 WheelBasedVehicleSpeed 84;
BA_ "SigType" SG_ 2566835710 EngPercentLoadAtCurrentSpeed 1;
BA_ "SPN" SG_ 2566835710 EngPercentLoadAtCurrentSpeed 92;
BA_ "SigType" SG_ 2566835710 EngCoolantTemp 1;
BA_ "SPN" SG_ 2566835710 EngCoolantTemp 110;
BA_ "SigType" SG_ 2566835710 DTC1 7;
BA_ "SigType" SG_ 2566764542 ExpandedFreezeFrameLength 1;
BA_ "SPN" SG_ 2566764542 ExpandedFreezeFrameLength 3300;
BA_ "SigType" SG_ 2566764542 DTC1 7;
BA_ "SigType" SG_ 2566764286 SPNDataLength3 1;
BA_ "SPN" SG_ 2566764286 SPNSupportTypeSTR1 4102;
BA_ "SPN" SG_ 2566764286 SPNSupportTypeDS1 4101;
BA_ "SPN" SG_ 2566764286 SPNSupportTypeEFF1 4100;
BA_ "SigType" SG_ 2566764286 SPNDataLength2 1;
BA_ "SigType" SG_ 2566764286 SPNDataLength1 1;
BA_ "SPN" SG_ 2566764286 SPNDataLength1 4103;
BA_ "SPN" SG_ 2566764286 SPNSupported1 3297;
BA_ "SigType" SG_ 2566764030 FlashRedStopLamp 5;
BA_ "SPN" SG_ 2566764030 FlashRedStopLamp 3039;
BA_ "SigType" SG_ 2566764030 FlashProtectLamp 5;
BA_ "SPN" SG_ 2566764030 FlashProtectLamp 3041;
BA_ "SigType" SG_ 2566764030 FlashMalfuncIndicatorLamp 5;
BA_ "SPN" SG_ 2566764030 FlashMalfuncIndicatorLamp 3038;
BA_ "SigType" SG_ 2566764030 FlashAmberWarningLamp 5;
BA_ "SPN" SG_ 2566764030 FlashAmberWarningLamp 3040;
BA_ "SigType" SG_ 2566764030 MalfunctionIndicatorLampStatus 5;
BA_ "SPN" SG_ 2566764030 MalfunctionIndicatorLampStatus 1213;
BA_ "SigType" SG_ 2566764030 RedStopLampState 4;
BA_ "SPN" SG_ 2566764030 RedStopLampState 623;
BA_ "SigType" SG_ 2566764030 AmberWarningLampStatus 5;
BA_ "SPN" SG_ 2566764030 AmberWarningLampStatus 624;
BA_ "SigType" SG_ 2566764030 ProtectLampStatus 5;
BA_ "SPN" SG_ 2566764030 ProtectLampStatus 987;
BA_ "SigType" SG_ 2566764030 DTC5 7;
BA_ "SigType" SG_ 2566764030 DTC4 7;
BA_ "SigType" SG_ 2566764030 DTC3 7;
BA_ "SigType" SG_ 2566764030 DTC2 7;
BA_ "SigType" SG_ 2566764030 DTC1 7;
BA_ "SPN" SG_ 2562981630 SPN1 3036;
BA_ "SPN" SG_ 2562981630 IndividualDTCClearControlByte 3034;
BA_ "SPN" SG_ 2562981630 CtrlByteIndicIndividualDTCClear 3035;
BA_ "SPN" SG_ 2562981630 FailureModeIdentifier1 3037;
BA_ "SigType" SG_ 2562850558 TimeSinceDTCsCleared 1;
BA_ "SPN" SG_ 2562850558 TimeSinceDTCsCleared 3296;
BA_ "SigType" SG_ 2562850558 MinutesAccumulatedMILActivated 1;
BA_ "SPN" SG_ 2562850558 MinutesAccumulatedMILActivated 3295;
BA_ "SigType" SG_ 2562850558 DistanceSinceDTCsCleared 1;
BA_ "SPN" SG_ 2562850558 DistanceSinceDTCsCleared 3294;
BA_ "SigType" SG_ 2562850558 DistanceWhileMILisActivated 1;
BA_ "SPN" SG_ 2562850558 DistanceWhileMILisActivated 3069;
BA_ "SPN" SG_ 2562916094 ApplSysMonitorDenominator 3068;
BA_ "SPN" SG_ 2562916094 ApplSysMonitorNumerator 3067;
BA_ "SPN" SG_ 2562916094 SPNofApplSysMonitor 3066;
BA_ "SPN" SG_ 2562916094 OBDMonitoringCondEncountered 3049;
BA_ "SPN" SG_ 2562916094 IgnitionCycleCounter 3048;
BA_ "SigType" SG_ 2566835198 MalfunctionIndicatorLampStatus 5;
BA_ "SPN" SG_ 2566835198 MalfunctionIndicatorLampStatus 1213;
BA_ "SigType" SG_ 2566835198 RedStopLampState 4;
BA_ "SPN" SG_ 2566835198 RedStopLampState 623;
BA_ "SigType" SG_ 2566835198 AmberWarningLampStatus 5;
BA_ "SPN" SG_ 2566835198 AmberWarningLampStatus 624;
BA_ "SigType" SG_ 2566835198 ProtectLampStatus 5;
BA_ "SPN" SG_ 2566835198 ProtectLampStatus 987;
BA_ "SigType" SG_ 2566835198 FlashRedStopLamp 5;
BA_ "SPN" SG_ 2566835198 FlashRedStopLamp 3039;
BA_ "SigType" SG_ 2566835198 FlashProtectLamp 5;
BA_ "SPN" SG_ 2566835198 FlashProtectLamp 3041;
BA_ "SigType" SG_ 2566835198 FlashMalfuncIndicatorLamp 5;
BA_ "SPN" SG_ 2566835198 FlashMalfuncIndicatorLamp 3038;
BA_ "SigType" SG_ 2566835198 FlashAmberWarningLamp 5;
BA_ "SPN" SG_ 2566835198 FlashAmberWarningLamp 3040;
BA_ "SigType" SG_ 2566835198 DTC5 7;
BA_ "SigType" SG_ 2566835198 DTC4 7;
BA_ "SigType" SG_ 2566835198 DTC3 7;
BA_ "SigType" SG_ 2566835198 DTC2 7;
BA_ "SigType" SG_ 2566835198 DTC1 7;
BA_ "SPN" SG_ 2564030206 CalibrationID1 1635;
BA_ "SPN" SG_ 2564030206 CalibrationVerificationNumber 1634;
BA_ "SPN" SG_ 2564226814 BootLoadData 1652;
BA_ "SPN" SG_ 2564292350 RawBinaryData 1651;
BA_ "SPN" SG_ 2564292350 NumberOfOccurance 1650;
BA_ "SPN" SG_ 2564357886 NumberAllowed 1649;
BA_ "SPN" SG_ 2564357886 Seed 1599;
BA_ "SPN" SG_ 2564357886 EDCP_Extension 1647;
BA_ "SPN" SG_ 2564357886 ErrorIndicator 1648;
BA_ "SPN" SG_ 2564357886 Status 1646;
BA_ "SPN" SG_ 2564423422 KeyOrUserLevel 1645;
BA_ "SPN" SG_ 2564423422 PointerExtension 1643;
BA_ "SPN" SG_ 2564423422 Pointer 1644;
BA_ "SPN" SG_ 2564423422 Command 1642;
BA_ "SPN" SG_ 2564423422 PointerType 1641;
BA_ "SPN" SG_ 2564423422 NumberRequested 1640;
BA_ "SigType" SG_ 2564816638 ProprietaryNetwork2 5;
BA_ "SPN" SG_ 2564816638 ProprietaryNetwork2 5588;
BA_ "SigType" SG_ 2564816638 ProprietaryNetwork1 5;
BA_ "SPN" SG_ 2564816638 ProprietaryNetwork1 625;
BA_ "SigType" SG_ 2564816638 J1939Network4 5;
BA_ "SPN" SG_ 2564816638 J1939Network4 1668;
BA_ "SPN" SG_ 2564816638 HoldSignal 1236;
BA_ "SigType" SG_ 2564816638 J1939Network3 5;
BA_ "SPN" SG_ 2564816638 J1939Network3 1235;
BA_ "SigType" SG_ 2564816638 J1939Network2 5;
BA_ "SPN" SG_ 2564816638 J1939Network2 1231;
BA_ "SigType" SG_ 2564816638 ISO9141 5;
BA_ "SPN" SG_ 2564816638 ISO9141 1232;
BA_ "SigType" SG_ 2564816638 SAE_J1850 5;
BA_ "SPN" SG_ 2564816638 SAE_J1850 1233;
BA_ "SigType" SG_ 2564816638 ManufacturerSpecificPort 5;
BA_ "SPN" SG_ 2564816638 ManufacturerSpecificPort 1234;
BA_ "SigType" SG_ 2564816638 CurrentDataLink 5;
BA_ "SPN" SG_ 2564816638 CurrentDataLink 1230;
BA_ "SigType" SG_ 2564816638 SAE_J1587 5;
BA_ "SPN" SG_ 2564816638 SAE_J1587 608;
BA_ "SigType" SG_ 2564816638 SAE_J1922 5;
BA_ "SPN" SG_ 2564816638 SAE_J1922 622;
BA_ "SigType" SG_ 2564816638 J1939Network1 5;
BA_ "SPN" SG_ 2564816638 J1939Network1 639;
BA_ "SPN" SG_ 2564816638 SuspendSignal 2618;
BA_ "SigType" SG_ 2564816638 SuspendDuration 1;
BA_ "SPN" SG_ 2564816638 SuspendDuration 2619;
BA_ "SigType" SG_ 2566837502 FlashRedStopLamp 5;
BA_ "SPN" SG_ 2566837502 FlashRedStopLamp 3039;
BA_ "SigType" SG_ 2566837502 FlashProtectLamp 5;
BA_ "SPN" SG_ 2566837502 FlashProtectLamp 3041;
BA_ "SigType" SG_ 2566837502 MalfunctionIndicatorLampStatus 5;
BA_ "SPN" SG_ 2566837502 MalfunctionIndicatorLampStatus 1213;
BA_ "SigType" SG_ 2566837502 RedStopLampState 4;
BA_ "SPN" SG_ 2566837502 RedStopLampState 623;
BA_ "SigType" SG_ 2566837502 AmberWarningLampStatus 5;
BA_ "SPN" SG_ 2566837502 AmberWarningLampStatus 624;
BA_ "SigType" SG_ 2566837502 ProtectLampStatus 5;
BA_ "SPN" SG_ 2566837502 ProtectLampStatus 987;
BA_ "SigType" SG_ 2566837502 FlashMalfuncIndicatorLamp 5;
BA_ "SPN" SG_ 2566837502 FlashMalfuncIndicatorLamp 3038;
BA_ "SigType" SG_ 2566837502 FlashAmberWarningLamp 5;
BA_ "SPN" SG_ 2566837502 FlashAmberWarningLamp 3040;
BA_ "SigType" SG_ 2566837502 DTC5 7;
BA_ "SigType" SG_ 2566837502 DTC4 7;
BA_ "SigType" SG_ 2566837502 DTC3 7;
BA_ "SigType" SG_ 2566837502 DTC2 7;
BA_ "SigType" SG_ 2566837502 DTC1 7;
BA_ "SigType" SG_ 2566836990 TestIdentifierSupported 1;
BA_ "SPN" SG_ 2566836990 TestIdentifierSupported 1229;
BA_ "SigType" SG_ 2566834942 FlashRedStopLamp 5;
BA_ "SPN" SG_ 2566834942 FlashRedStopLamp 3039;
BA_ "SigType" SG_ 2566834942 FlashProtectLamp 5;
BA_ "SPN" SG_ 2566834942 FlashProtectLamp 3041;
BA_ "SigType" SG_ 2566834942 FlashMalfuncIndicatorLamp 5;
BA_ "SPN" SG_ 2566834942 FlashMalfuncIndicatorLamp 3038;
BA_ "SigType" SG_ 2566834942 FlashAmberWarningLamp 5;
BA_ "SPN" SG_ 2566834942 FlashAmberWarningLamp 3040;
BA_ "SigType" SG_ 2566834942 MalfunctionIndicatorLampStatus 5;
BA_ "SPN" SG_ 2566834942 MalfunctionIndicatorLampStatus 1213;
BA_ "SigType" SG_ 2566834942 AmberWarningLampStatus 5;
BA_ "SPN" SG_ 2566834942 AmberWarningLampStatus 624;
BA_ "SigType" SG_ 2566834942 RedStopLampState 4;
BA_ "SPN" SG_ 2566834942 RedStopLampState 623;
BA_ "SigType" SG_ 2566834942 ProtectLampStatus 5;
BA_ "SPN" SG_ 2566834942 ProtectLampStatus 987;
BA_ "SigType" SG_ 2566834942 DTC5 7;
BA_ "SigType" SG_ 2566834942 DTC4 7;
BA_ "SigType" SG_ 2566834942 DTC3 7;
BA_ "SigType" SG_ 2566834942 DTC2 7;
BA_ "SigType" SG_ 2566834942 DTC1 7;
BA_ "SigType" SG_ 2365454334 UtlityOverallPowerFactorLagging 4;
BA_ "SPN" SG_ 2365454334 UtlityOverallPowerFactorLagging 2522;
BA_ "SigType" SG_ 2365454334 UtilityOverallPowerFactor 1;
BA_ "SPN" SG_ 2365454334 UtilityOverallPowerFactor 2498;
BA_ "SigType" SG_ 2365454334 UtilityTotalReactivePower 1;
BA_ "SPN" SG_ 2365454334 UtilityTotalReactivePower 2490;
BA_ "SigType" SG_ 2365454590 UtilityTotalApparentPower 1;
BA_ "SPN" SG_ 2365454590 UtilityTotalApparentPower 2494;
BA_ "SigType" SG_ 2365454590 UtilityTotalRealPower 1;
BA_ "SPN" SG_ 2365454590 UtilityTotalRealPower 2486;
BA_ "SigType" SG_ 2365451774 UtilityTotalKWHoursImport 1;
BA_ "SPN" SG_ 2365451774 UtilityTotalKWHoursImport 2503;
BA_ "SigType" SG_ 2365451774 UtilityTotalKWHoursExport 1;
BA_ "SPN" SG_ 2365451774 UtilityTotalKWHoursExport 2502;
BA_ "SigType" SG_ 2365452030 UtilityPhaseCPowerFactorLagging 4;
BA_ "SPN" SG_ 2365452030 UtilityPhaseCPowerFactorLagging 2525;
BA_ "SigType" SG_ 2365452030 UtilityPhaseCPowerFactor 1;
BA_ "SPN" SG_ 2365452030 UtilityPhaseCPowerFactor 2501;
BA_ "SigType" SG_ 2365452030 UtilityPhaseCReactivePower 1;
BA_ "SPN" SG_ 2365452030 UtilityPhaseCReactivePower 2493;
BA_ "SigType" SG_ 2365452286 UtilityPhaseCApparentPower 1;
BA_ "SPN" SG_ 2365452286 UtilityPhaseCApparentPower 2497;
BA_ "SigType" SG_ 2365452286 UtilityPhaseCRealPower 1;
BA_ "SPN" SG_ 2365452286 UtilityPhaseCRealPower 2489;
BA_ "SigType" SG_ 2365452542 UtilityPhaseCACRMSCurrent 1;
BA_ "SPN" SG_ 2365452542 UtilityPhaseCACRMSCurrent 2485;
BA_ "SigType" SG_ 2365452542 UtilityPhaseCACFrequency 1;
BA_ "SPN" SG_ 2365452542 UtilityPhaseCACFrequency 2473;
BA_ "SigType" SG_ 2365452542 UtltyPhsCLneNeutralACRMSVoltage 1;
BA_ "SPN" SG_ 2365452542 UtltyPhsCLneNeutralACRMSVoltage 2481;
BA_ "SigType" SG_ 2365452542 UtltyPhseCALineLineACRMSVoltage 1;
BA_ "SPN" SG_ 2365452542 UtltyPhseCALineLineACRMSVoltage 2477;
VAL_ 2365478910 ElctrncShckAbsrbrCtrlMdLft_TgAxl 3 "Not available" 2 "Error" 1 "Normal operation dampers active" 0 "Normal operation dampers passive" ;
VAL_ 2365478910 ElctrncShckAbsrbrCtrlMdeRearAxle 3 "Not available" 2 "Error" 1 "Normal operation dampers active" 0 "Normal operation dampers passive" ;
VAL_ 2365478910 ElctrncShckAbsrbrCtrlMdFrontAxle 3 "Not available" 2 "Error" 1 "Normal operation dampers active" 0 "Normal operation dampers passive" ;
VAL_ 2560950014 FailureModeIdentifier1 31 "Not available" 19 "Received network data in error" 18 "Below normal (moderately severe)" 17 "Below normal (least severe)" 16 "Above normal (moderately severe)" 15 "Above normal (least severe)" 14 "Special intstructions" 13 "Out of calibration" 12 "Bad intelligent device" 11 "Root cause not known" 10 "Abnormal rate of change" 9 "Abnormal update rate" 8 "Abnormal frequency" 7 "Mechanical system not responding" 6 "Current above normal" 5 "Current below normal" 4 "Voltage below normal" 3 "Voltage above normal" 2 "Data erratic" 1 "Below normal (most severe)" 0 "Above normal (most severe)" ;
VAL_ 2565869566 NOxSnsr1SelfDiagSt 7 "Not Supported" 4 "NOx Sensor ATO1 Self-diagnosis not possible" 3 "NOx Sensor ATO1 Self-diagnosis aborted" 2 "NOx Sensor ATO1 Self-diagnosis Result Complete" 1 "NOx Sensor ATO1 Self-diagnosis active flag" 0 "Diagnosis not active" ;
VAL_ 2565869566 Snsr1HtrCtrl 3 "Heater off" 2 "Preheat 1" 1 "Preheat 2" 0 "Automatic" ;
VAL_ 2565869566 WRPercentO21ReadingStable 3 "Not available" 2 "Error" 1 "Stable" 0 "Not stable" ;
VAL_ 2565869566 NOx1ReadingStable 3 "Not available" 2 "Error" 1 "Stable" 0 "Not stable" ;
VAL_ 2565869566 Snsr1AtTemp 3 "Not available" 2 "Error" 1 "In range" 0 "Not in range" ;
VAL_ 2565869566 Snsr1PwrInRange 3 "Not available" 2 "Error" 1 "In range" 0 "Not in range" ;
VAL_ 2566758142 EnableAct 3 "not available" 2 "reserved for SAE assignment" 1 "active" 0 "not active" ;
VAL_ 2566758142 PurgeAirAct 3 "not available" 2 "reserved for SAE assignment" 1 "active" 0 "not active" ;
VAL_ 2566758142 AtomizationAirAct 3 "not available" 2 "reserved for SAE assignment" 1 "active" 0 "not active" ;
VAL_ 2566758142 SysRelay 3 "not available" 2 "reserved for SAE assignment" 1 "active" 0 "not active" ;
VAL_ 2566758654 EnableAct 2 "reserved for SAE assignment" 3 "not available" 1 "active" 0 "not active" ;
VAL_ 2566758654 RegenSt 3 "not available" 2 "reserved for SAE assignment" 1 "active" 0 "not active" ;
VAL_ 2566758654 Ignt 3 "not available" 2 "reserved for SAE assignment" 1 "active" 0 "not active" ;
VAL_ 2566758654 DrainAct 3 "not available" 2 "reserved for SAE assignment" 1 "active" 0 "not active" ;
VAL_ 2565869822 TwoGasSnsrPwrSupply 3 "Unavailable" 2 "Error" 1 "On: The ECU is powering the Engine Exhaust 2 Gas Sensor" 0 "Off" ;
VAL_ 2565869822 NOxSnsr1SelfDiagStatus 7 "Not Supported" 6 "Reserved" 5 "Reserved" 4 "NOx Sensor EEB2 Self-diagnosis not possible" 3 "NOx Sensor EEB2 Self-diagnosis aborted" 2 "NOx Sensor EEB2 Self-diagnosis Result Complete" 1 "NOx Sensor EEB2 Self-diagnosis active flag" 0 "Diagnosis not active" ;
VAL_ 2565869822 Snsr1HtrCtrl 3 "Heater off" 2 "Preheat 1" 1 "Preheat 2" 0 "Automatic" ;
VAL_ 2565869822 WRPercentO21ReadingStable 3 "Not available" 2 "Error" 1 "Stable" 0 "Not stable" ;
VAL_ 2565869822 SCRInNOx1ReadingStable 3 "Not available" 2 "Error" 1 "Stable" 0 "Not stable" ;
VAL_ 2565869822 Snsr1AtTemp 3 "Not available" 2 "Error" 1 "In range" 0 "Not in range" ;
VAL_ 2565870078 TwoGasSnsrPwrSupply 3 "Unavailable" 2 "Error" 1 "On: The ECU is powering the Aftertreatment 2 Outlet 2 Gas Sensor" 0 "Off" ;
VAL_ 2565870078 Snsr1HtrCtrl 3 "Heater off" 2 "Preheat 1" 1 "Preheat 2" 0 "Automatic" ;
VAL_ 2565870078 WRPercentO21ReadingStable 3 "Not available" 2 "Error" 1 "Stable" 0 "Not stable" ;
VAL_ 2565870078 NOx1ReadingStable 3 "Not available" 2 "Error" 1 "Stable" 0 "Not stable" ;
VAL_ 2565870078 NOxSnsr1SelfDiagSt 7 "Not Supported" 4 "NOx Sensor ATO2 Self-diagnosis not possible" 3 "NOx Sensor ATO2 Self-diagnosis aborted" 2 "NOx Sensor ATO2 Self-diagnosis Result Complete" 1 "NOx Sensor ATO2 Self-diagnosis active flag" 0 "Diagnosis not active" ;
VAL_ 2565870078 Snsr1AtTemp 2 "Error" 1 "In range" 0 "Not in range" 3 "Not available" ;
VAL_ 2565870078 Snsr1PwrInRange 3 "Not available" 2 "Error" 1 "In range" 0 "Not in range" ;
VAL_ 2365428478 EngColdAmbientElevatedIdleStatus 3 "Unavailable" 2 "Reserved for SAE assignment" 1 "Idle Elevation Active" 0 "No Idle Elevation Active" ;
VAL_ 2365428478 EngStarterMotorRelayCtrl 3 "Don't care/take no action" 2 "Reserved for SAE assignment" 1 "On" 0 "Off" ;
VAL_ 2365428478 EngEmergencyShutdownIndication 3 "Don't care / take no action" 2 "Reserved" 1 "On" 0 "Off" ;
VAL_ 2365428478 EngControlledShutdownRq 3 "Don't care / take no action" 2 "Reserved" 1 "On" 0 "Off" ;
VAL_ 2365428478 EngCoolantCirculatingPumpCtrl 3 "Don't care / take no action" 2 "Reserved" 1 "On" 0 "Off" ;
VAL_ 2365428478 EngBlock_CoolantPreheaterCtrl 3 "Unavailable" 2 "Reserved" 1 "On" 0 "Off" ;
VAL_ 2365428478 EngElctrclSystmPwrCnsrvationCtrl 3 "Unavailable" 2 "Reserved" 1 "On" 0 "Off" ;
VAL_ 2365428478 EngOilPreheaterCtrl 3 "Don't care / take no action" 2 "Reserved" 1 "On" 0 "Off" ;
VAL_ 2365428478 EngOilPrimingPumpCtrl 3 "unavailable" 2 "Reserved" 1 "On" 0 "Off" ;
VAL_ 2365428478 EngFuelShutoffValveLeakTestCtrl 3 "Don't care / take no action" 2 "Reserved" 1 "On" 0 "Off" ;
VAL_ 2365428478 EngFuelShutoff2Ctrl 3 "Don't care / take no action" 2 "Reserved" 1 "Closed" 0 "Open" ;
VAL_ 2365428478 EngFuelShutoff1Ctrl 3 "Don't care / take no action" 2 "Reserved" 1 "Closed" 0 "Open" ;
VAL_ 2365428478 EngFuelShutoffVentCtrl 3 "Don't care / take no action" 2 "Reserved" 1 "Open" 0 "Closed" ;
VAL_ 2365428478 FuelPumpPrimerCtrl 3 "Unavailable" 2 "Reserved" 1 "Activate" 0 "Deactivate" ;
VAL_ 2365428478 EngOperatingState 15 "not available" 14 "<reserved>" 7 "Post-Run" 6 "Engine Stopping" 5 "Cool-down" 4 "Running" 3 "Warm-Up" 2 "Starting" 1 "Pre-Start" 0 "Engine Stopped" ;
VAL_ 2550660862 PilotPressSw 3 "Not available" 2 "Error" 1 "On" 0 "Off" ;
VAL_ 2362638078 MemoryLevelRq 15 "Don't care" 14 "Reserved" 13 "Store Memory level  5" 12 "Store Memory level  4" 11 "Store Memory level  3" 10 "Store Memory level  2" 9 "Store Memory level  1" 8 "reserved" 7 "reserved" 6 "reserved" 5 "Memory level 5 request" 4 "Memory level 4 request" 3 "Memory level 3 request" 2 "Memory level 2 request" 1 "Memory level 1 request" 0 "No memory level request" ;
VAL_ 2362638078 PrhbitAutomaticAirSuspensionCtrl 3 "Not available" 2 "Error indicator" 1 "Request prohibit automatic air suspension control" 0 "No request" ;
VAL_ 2362638078 SpeedDependentLevelCtrlRq 3 "Don't care/take no action" 2 "Reserved" 1 "Activate" 0 "Deactivate" ;
VAL_ 2362638078 AllowLevelCtrlDuringBrakingCmd 3 "Don't' care/take no action" 2 "Reserved" 1 "Allow level control during braking" 0 "Disallow level control during braking" ;
VAL_ 2362638078 ProhibitAirSuspensionCtrl 3 "Not available" 2 "Error indicator" 1 "Request prohibit air suspension control" 0 "No request" ;
VAL_ 2362638078 KneelingCmdRearAxle 3 "Don't care/take no action" 2 "Reserved" 1 "Activate kneeling" 0 "Deactivate kneeling" ;
VAL_ 2362638078 KneelingCmdFrontAxle 3 "Don't care/take no action" 2 "Reserved" 1 "Activate kneeling" 0 "Deactivate kneeling" ;
VAL_ 2362638078 LiftAxle2PosCmd 3 "Don't care/take no action" 2 "Reserved" 1 "Lift axle position up / tag axle unladen" 0 "Lift axle position down / tag axle laden" ;
VAL_ 2362638078 LiftAxle1PosCmd 3 "Don't care/take no action" 2 "Reserved" 1 "Lift axle position up / tag axle unladen" 0 "Lift axle position down / tag axle laden" ;
VAL_ 2362638078 LevelCtrlModeRq 15 "Don't care/take no action" 14 "Reserved" 13 "Not defined" 12 "Not defined" 11 "Not defined" 10 "Reverse traction help" 9 "Force to bumper level" 8 "Exhaust bellows" 7 "Traction help, load reduce" 6 "Optimum traction 2" 5 "Optimum traction 1" 4 "Pressure ratio 2" 3 "Pressure ratio 1" 2 "Load fixing" 1 "Traction help, load transfer)" 0 "Normal operation" ;
VAL_ 2362638078 NominalLevelRqRearAxle 15 "Don't care/take no action" 14 "Reserved" 10 "Lower Request" 9 "Raise Request" 8 "Stop level change" 7 "Lower Level" 6 "Upper Level" 5 "Customer Level" 4 "Preset Level" 3 "Normal Level 3" 2 "Normal Level 2" 1 "Normal Level 1" 0 "No level request" ;
VAL_ 2362638078 NominalLevelRqFrontAxle 15 "Don't care/take no action" 14 "Reserved" 10 "Lower Request" 9 "Raise Request" 8 "Stop level change" 7 "Lower Level" 6 "Upper Level" 5 "Customer Level" 4 "Preset Level" 3 "Normal Level 3" 2 "Normal Level 2" 1 "Normal Level 1" 0 "No level request" ;
VAL_ 2362638078 KneelingCtrlModeRq 3 "Don't care/take no action" 2 "Reserved" 1 "Manually actuated" 0 "Automatically actuated" ;
VAL_ 2362638078 KneelingRqRightSide 3 "Don't care/take no action" 2 "Reserved" 1 "Kneeling request" 0 "No kneeling request" ;
VAL_ 2362638078 KneelingRqLeftSide 3 "Don't care/take no action" 2 "Reserved" 1 "Kneeling request" 0 "No kneeling request" ;
VAL_ 2362638078 AutomaticTractionHelp 3 "Don't care" 2 "Reserved" 1 "Enable automatic traction help" 0 "Disable automatic traction help" ;
VAL_ 2365479678 MemoryLevel 15 "not available" 14 "Error indicator" 13 "Memory level  5 stored" 12 "Memory level  4 stored" 11 "Memory level  3 stored" 10 "Memory level  2 stored" 9 "Memory level  1 stored" 8 "reserved" 7 "reserved" 6 "reserved" 5 "Memory level 5 selected" 4 "Memory level 4 selected" 3 "Memory level 3 selected" 2 "Memory level 2 selected" 1 "Memory level 1 selected" 0 "No memory level" ;
VAL_ 2365479678 SuspensionCtrlRefusalInformation 15 "Not available" 14 "Error" 7 "Requested level not available" 6 "General reject" 5 "Below speed limit" 4 "Above speed limit" 3 "Bogie differential not locked" 2 "Would exceed axle load limit" 1 "Axle load limit reached " 0 "Actual request not refused" ;
VAL_ 2365479678 SpeedDependantLevelCtrlStatus 3 "Don't' care/take no action" 2 "Reserved" 1 "Active" 0 "Inactive" ;
VAL_ 2365479678 AllwLevelCtrlDuringBrakingStatus 3 "Don't care/take no action" 2 "Reserved" 1 "Activated" 0 "Deactivated" ;
VAL_ 2365479678 SuspensionRemoteCtrl2 3 "Not available" 2 "Error" 1 "Active" 0 "Not active" ;
VAL_ 2365479678 SuspensionRemoteCtrl1 3 "Not available" 2 "Error" 1 "Active" 0 "Not active" ;
VAL_ 2365479678 LiftAxle2Pos 3 "Not available" 2 "Error" 1 "Lift axle position up / tag axle unladen" 0 "Lift axle position down / tag axle laden" ;
VAL_ 2365479678 RearAxleInBumperRange 3 "Not available" 2 "Error" 1 "Actual level within bumper range" 0 "Actual level out of bumper range" ;
VAL_ 2365479678 FrontAxleInBumperRange 3 "Not available" 2 "Error" 1 "Actual level within bumper range" 0 "Actual level out of bumper range" ;
VAL_ 2365479678 LiftAxle1Pos 3 "Not available" 2 "Error" 1 "Lift axle position up / tag axle unladen" 0 "Lift axle position down / tag axle laden" ;
VAL_ 2365479678 DoorRelease 3 "Not available" 2 "Error" 1 "Doors may be opened" 0 "Doors may not be opened" ;
VAL_ 2365479678 VehicleMotionInhibit 3 "Not available" 2 "Error" 1 "Vehicle motion is inhibited" 0 "Vehicle may be moved" ;
VAL_ 2365479678 SecurityDevice 3 "Not available" 2 "Error" 1 "Active" 0 "Not active" ;
VAL_ 2365479678 LevelCtrlMode 15 "Not available" 14 "Error" 11 "Force to bumper level request is in effect" 10 "Automatic air suspension control prohibited" 9 "Air suspension control prohibited" 8 "Exhausting bellow function" 7 "Traction help, load reduce" 6 "Optimum traction 2" 5 "Optimum traction 1" 4 "Pressure ratio 2" 3 "Pressure ratio 1" 2 "Load fixing" 1 "Traction help, load transfer)" 0 "Normal operation" ;
VAL_ 2365479678 KneelingInformation 15 "Not available" 14 "Error" 4 "Kneeling aborted" 3 "Lifting active" 2 "Kneeling level reached" 1 "Lowering active" 0 "Not active" ;
VAL_ 2365479678 LiftingCtrlModeRearAxle 0 "Lifting not active" 3 "Not available" 2 "Error" 1 "Lifting active" ;
VAL_ 2365479678 LiftingCtrlModeFrontAxle 3 "Not available" 2 "Error" 1 "Lifting active" 0 "Lifting not active" ;
VAL_ 2365479678 LoweringCtrlModeRearAxle 3 "Not available" 2 "Error" 1 "Lowering active" 0 "Lowering not active" ;
VAL_ 2365479678 LoweringCtrlModeFrontAxle 3 "Not available" 2 "Error" 1 "Lowering active" 0 "Lowering not active" ;
VAL_ 2365479678 AboveNominalLevelRearAxle 3 "Not available" 2 "Error" 1 "Above" 0 "Not above" ;
VAL_ 2365479678 AboveNominalLevelFrontAxle 3 "Not available" 2 "Error" 1 "Above" 0 "Not above" ;
VAL_ 2365479678 BelowNominalLevelRearAxle 3 "Not available" 2 "Error" 1 "Below" 0 "Not below" ;
VAL_ 2365479678 BelowNominalLevelFrontAxle 3 "Not available" 2 "Error" 1 "Below" 0 "Not below" ;
VAL_ 2365479678 NominalLevelRearAxle 15 "Not available" 14 "Error" 10 "Lowering" 9 "Raising" 8 "Level change stopped" 7 "'Lower Level" 6 "'Upper Level" 5 "'Customer Level" 4 "'Preset Level" 3 "'Normal Level 3" 2 "'Normal Level 2" 1 "'Normal Level 1" 0 "Level not specified" ;
VAL_ 2365479678 NominalLevelFrontAxle 15 "Not available" 14 "Error" 10 "Lowering" 9 "Raising" 8 "Level change stopped" 7 "'Lower Level" 6 "'Upper Level" 5 "'Customer Level" 4 "'Preset Level" 3 "'Normal Level 3" 2 "'Normal Level 2" 1 "'Normal Level 1" 0 "Level not specified" ;
VAL_ 2566837758 Alt4Status 3 "not available" 2 "error" 1 "Alternator 4 charging" 0 "Alternator 4 not charging" ;
VAL_ 2566837758 Alt3Status 3 "not available" 2 "error" 1 "Alternator 3 charging" 0 "Alternator 3 not charging" ;
VAL_ 2566837758 Alt2Status 3 "not available" 2 "error" 1 "Alternator 2 charging" 0 "Alternator 2 not charging" ;
VAL_ 2566837758 Alt1Status 3 "not available" 2 "error" 1 "Alternator 1 charging" 0 "Alternator 1 not charging" ;
VAL_ 2566836478 TestIdentifier 250 "Last Measured Scaled Results" 249 "Command Standard Test" 247 "All scaled test results" ;
VAL_ 2565078782 TestIdentifier 250 "Last Measured Scaled Results" 249 "Command Standard Test" 247 "All scaled test results" ;
VAL_ 2565078782 FailureModeIdentifier1 31 "Not available" 19 "Received network data in error" 18 "Below normal (moderately severe)" 17 "Below normal (least severe)" 16 "Above normal (moderately severe)" 15 "Above normal (least severe)" 14 "Special intstructions" 13 "Out of calibration" 12 "Bad intelligent device" 11 "Root cause not known" 10 "Abnormal rate of change" 9 "Abnormal update rate" 8 "Abnormal frequency" 7 "Mechanical system not responding" 6 "Current above normal" 5 "Current below normal" 4 "Voltage below normal" 3 "Voltage above normal" 2 "Data erratic" 1 "Below normal (most severe)" 0 "Above normal (most severe)" ;
VAL_ 2566836222 FlashRedStopLamp 3 "Unavailable / Do Not Flash" 2 "Reserved" 1 "Fast Flash" 0 "Slow Flash" ;
VAL_ 2566836222 FlashProtectLamp 3 "Unavailable / Do Not Flash" 2 "Reserved" 1 "Fast Flash" 0 "Slow Flash" ;
VAL_ 2566836222 FlashMalfuncIndicatorLamp 3 "Unavailable / Do Not Flash" 2 "Class C DTC  " 1 "Fast Flash" 0 "Slow Flash" ;
VAL_ 2566836222 FlashAmberWarningLamp 3 "Unavailable / Do Not Flash" 2 "Reserved" 1 "Fast Flash" 0 "Slow Flash" ;
VAL_ 2566836222 MalfunctionIndicatorLampStatus 3 "Not available" 2 "Short MIL for WWH OBD" 1 "Lamp On" 0 "Lamp Off" ;
VAL_ 2566836222 RedStopLampState 3 "Not available" 2 "Reserved" 1 "Lamp On" 0 "Lamp Off" ;
VAL_ 2566836222 AmberWarningLampStatus 3 "Not available" 2 "Reserved" 1 "Lamp On" 0 "Lamp Off" ;
VAL_ 2566836222 ProtectLampStatus 3 "Not available" 2 "Reserved" 1 "Lamp On" 0 "Lamp Off" ;
VAL_ 2566835966 MisfireMonitoringSupport 3 "Not available" 2 "Reserved" 1 "test supported" 0 "test not supported" ;
VAL_ 2566835966 OBDCompliance 10 "JOBD" 11 "JOBD and OBD II" 12 "JOBD and EOBD" 13 "JOBD, EOBD and OBD II" 14 "Heavy Duty Vehicles (EURO IV) B1" 15 "Heavy Duty Vehicles (EURO V) B2" 16 "Heavy Duty Vehicles (EURO EEC) C" 17 "EMD" 18 "EMD+" 19 "HD OBD P" 20 "HD OBD" 21 "WWH OBD" 22 "OBD II (California, ARB 07/08)" 23 "HD EOBD" 25 "OBD-M (SI-SD/I)" 6 "EOBD" 7 "EOBD and OBD II" 8 "EOBD and OBD" 9 "EOBD, OBD and OBD II" 5 "Not intended to meet OBD II req." 4 "OBD I" 3 "OBD and OBD II" 2 "OBD (Federal, EPA)" 1 "OBD II (California, ARB)" 0 "Reserver for assignment by SAE" ;
VAL_ 2566835966 SecondAirSystemMonStatus 1 "TestNotComplete" 0 "TestComplete" ;
VAL_ 2566835966 EvaporativeSystemMonStatus 1 "TestNotComplete" 0 "TestComplete" ;
VAL_ 2566835966 ACSystemRefrigerantMonStatus 1 "TestNotComplete" 0 "TestComplete" ;
VAL_ 2566835966 OxygenSensorHeaterMonStatus 1 "TestNotComplete" 0 "TestComplete" ;
VAL_ 2566835966 OxygenSensorMonStatus 1 "test not complete" 0 "test complete" ;
VAL_ 2566835966 EGRSystemMonitoringStatus 1 "TestNotComplete" 0 "TestComplete" ;
VAL_ 2566835966 CatalystMonStatus 0 "TestComplete" 1 "TestNotComplete" ;
VAL_ 2566835966 ColdStartAidSystemMonStatus 1 "TestNotComplete" 0 "TestComplete" ;
VAL_ 2566835966 HeatedCatalystMonStatus 1 "TestNotComplete" 0 "TestComplete" ;
VAL_ 2566835966 CatalystMonSupp 1 "TestSupported" 0 "TestNotSupported" ;
VAL_ 2566835966 ColdStartAidSystemMonSupp 1 "TestSupported" 0 "TestNotSupported" ;
VAL_ 2566835966 HeatedCatalystMonSupp 1 "TestSupported" 0 "TestNotSupported" ;
VAL_ 2566835966 EvaporativeSystemMonSupp 1 "TestSupported" 0 "TestNotSupported" ;
VAL_ 2566835966 SecondAirSystemMonSupp 1 "TestSupported" 0 "TestNotSupported" ;
VAL_ 2566835966 ACSystemRefrigerantMonSupp 1 "TestSupported" 0 "TestNotSupported" ;
VAL_ 2566835966 OxygenSensorMonSupp 1 "TestSupported" 0 "TestNotSupported" ;
VAL_ 2566835966 OxygenSensorHeaterMonSupp 1 "TestSupported" 0 "TestNotSupported" ;
VAL_ 2566835966 EGRSystemMonitoringSupp 1 "TestSupported" 0 "TestNotSupported" ;
VAL_ 2566835966 MisfireMonitoringStatus 1 "test not complete" 0 "test complete" ;
VAL_ 2566835966 ComprehensiveCompMonStatus 1 "test not complete" 0 "test complete" ;
VAL_ 2566835966 FuelSystemMonitoringStatus 1 "test not complete" 0 "test complete" ;
VAL_ 2566835966 ComprehensiveComponentMonSupp 3 "Not available" 2 "Reserved" 1 "test supported" 0 "test not supported" ;
VAL_ 2566835966 FuelSystemMonitoringSupport 1 "test supported" 0 "test not supported" ;
VAL_ 2566764286 SPNSupportTypeSTR3 1 "Not Supported In Scaled Test Results" 0 "Supported In Scaled Test Results" ;
VAL_ 2566764286 SPNSupportTypeSTR2 1 "Not Supported In Scaled Test Results" 0 "Supported In Scaled Test Results" ;
VAL_ 2566764286 SPNSupportTypeEFF3 1 "Not Supported In Ex Freeze Frame" 0 "Supported In Ex Freeze Frame" ;
VAL_ 2566764286 SPNSupportTypeEFF2 1 "Not Supported In Ex Freeze Frame" 0 "Supported In Ex Freeze Frame" ;
VAL_ 2566764286 SPNSupportTypeDS3 1 "Not Supported In Data Stream" 0 "Supported In Data Stream" ;
VAL_ 2566764286 SPNSupportTypeDS2 1 "Not Supported In Data Stream" 0 "Supported In Data Stream" ;
VAL_ 2566764286 SPNSupportTypeSTR1 1 "Not Supported In Scaled Test Results" 0 "Supported In Scaled Test Results" ;
VAL_ 2566764286 SPNSupportTypeDS1 1 "Not Supported In Data Stream" 0 "Supported In Data Stream" ;
VAL_ 2566764286 SPNSupportTypeEFF1 1 "Not Supported In Ex Freeze Frame" 0 "Supported In Ex Freeze Frame" ;
VAL_ 2566764030 FlashRedStopLamp 3 "Unavailable / Do Not Flash" 2 "Reserved" 1 "Fast Flash" 0 "Slow Flash" ;
VAL_ 2566764030 FlashProtectLamp 3 "Unavailable / Do Not Flash" 2 "Reserved" 1 "Fast Flash" 0 "Slow Flash" ;
VAL_ 2566764030 FlashMalfuncIndicatorLamp 3 "Unavailable / Do Not Flash" 2 "Class C DTC  " 1 "Fast Flash" 0 "Slow Flash" ;
VAL_ 2566764030 FlashAmberWarningLamp 3 "Unavailable / Do Not Flash" 2 "Reserved" 1 "Fast Flash" 0 "Slow Flash" ;
VAL_ 2566764030 MalfunctionIndicatorLampStatus 3 "Not available" 2 "Short MIL for WWH OBD" 1 "Lamp On" 0 "Lamp Off" ;
VAL_ 2566764030 RedStopLampState 3 "Not available" 2 "Reserved" 1 "Lamp On" 0 "Lamp Off" ;
VAL_ 2566764030 AmberWarningLampStatus 3 "Not available" 2 "Reserved" 1 "Lamp On" 0 "Lamp Off" ;
VAL_ 2566764030 ProtectLampStatus 3 "Not available" 2 "Reserved" 1 "Lamp On" 0 "Lamp Off" ;
VAL_ 2562981630 IndividualDTCClearControlByte 1 "Request to Clear/Reset a Specific Previously Active DTC" 0 "Reserved for SAE Assignment" ;
VAL_ 2562981630 CtrlByteIndicIndividualDTCClear 0 "General Negative Acknowledge" 1 "Access Denied" ;
VAL_ 2562981630 FailureModeIdentifier1 31 "Not available" 19 "Received network data in error" 18 "Below normal (moderately severe)" 17 "Below normal (least severe)" 16 "Above normal (moderately severe)" 15 "Above normal (least severe)" 14 "Special intstructions" 13 "Out of calibration" 12 "Bad intelligent device" 11 "Root cause not known" 10 "Abnormal rate of change" 9 "Abnormal update rate" 8 "Abnormal frequency" 7 "Mechanical system not responding" 6 "Current above normal" 5 "Current below normal" 4 "Voltage below normal" 3 "Voltage above normal" 2 "Data erratic" 1 "Below normal (most severe)" 0 "Above normal (most severe)" ;
VAL_ 2566835198 MalfunctionIndicatorLampStatus 3 "Not available" 2 "Short MIL for WWH OBD" 1 "Lamp On" 0 "Lamp Off" ;
VAL_ 2566835198 RedStopLampState 3 "Not available" 2 "Reserved" 1 "Lamp On" 0 "Lamp Off" ;
VAL_ 2566835198 AmberWarningLampStatus 3 "Not available" 2 "Reserved" 1 "Lamp On" 0 "Lamp Off" ;
VAL_ 2566835198 ProtectLampStatus 3 "Not available" 2 "Reserved" 1 "Lamp On" 0 "Lamp Off" ;
VAL_ 2566835198 FlashRedStopLamp 3 "Unavailable / Do Not Flash" 2 "Reserved" 1 "Fast Flash" 0 "Slow Flash" ;
VAL_ 2566835198 FlashProtectLamp 3 "Unavailable / Do Not Flash" 2 "Reserved" 1 "Fast Flash" 0 "Slow Flash" ;
VAL_ 2566835198 FlashMalfuncIndicatorLamp 3 "Unavailable / Do Not Flash" 2 "Class C DTC  " 1 "Fast Flash" 0 "Slow Flash" ;
VAL_ 2566835198 FlashAmberWarningLamp 3 "Unavailable / Do Not Flash" 2 "Reserved" 1 "Fast Flash" 0 "Slow Flash" ;
VAL_ 2564357886 Seed 255 "NoFurtherKeyRequiredOfTool" 1 "UseLongSeedOrKeyFromDataSecMsg" 0 "SeedCompleted_BeginSendingKey" ;
VAL_ 2564357886 EDCP_Extension 9 "DataInErrIndAndDataInSeedIsTime" 6 "DataInErrorIndicator" 3 "ConcatenateDataAsLowerEDCParam" 2 "ConcatenateDataAsHigherEDCParam" 0 "Completed" 255 "NoErrIndicator/EDCParamAvailable" ;
VAL_ 2564357886 ErrorIndicator 16777215 "NoErrorIndicatorAvailable" 65540 "TransprtNotComplWithinTimeAllowd" 65539 "TransportNotInitWithinTimeAllowd" 65538 "NoResponseInTheTimeAllowed" 65537 "ModuleExceedingNumberOfRetries" 65536 "AbortFromExtToNormalSoftwareProc" 4103 "VehicleNotInParkOrNotStationary" 4102 "EngineRunning" 4101 "NotInEngineeringOrDevelopmentMode" 4100 "NotInDiagnosticMode" 4099 "InvalidKey" 4098 "InvalidUserLevel" 4097 "InvalidPassword" 4096 "SecurityErrorGeneral" 266 "NameDoesNotConformToExpectdValue" 265 "DataDoesNotConformToValueRanges" 264 "AddrForBootLoadExeInvalidBoundary" 263 "AddrForBootLoadExeOutsideExeMem" 262 "OpReqExeTransfAndEraseOfProgMem" 261 "OpRequiresPriorEraseOfProgramMem" 260 "OpRequiresPriorEraseOfDataMem" 259 "ReqMemoryExceededAvailableMemory" 258 "LengthNotValidForMemStructAndOp" 257 "AddressNotOnValidBoundary" 256 "AddressingOrDataGeneralError" 36 "InternalFailurePreventingReq" 35 "PROMDidNotVerifyOnWrite" 34 "FLASHDidNotVerifyOnWrite" 33 "RAMDidNotVerifyOnWrite" 32 "EDCParaNotCorrectForDataStream" 31 "ProcessUnspecReqFromThisAddress" 23 "ProcessingEDCPGenerationReq" 22 "ProcessingBootLoadReq" 19 "ProcessingStatusReq" 18 "ProcessingWriteReq" 17 "ProcessingReadReq" 16 "ProcessingEraseReq" 2 "ProcessingForSomeoneElse" 1 "ErrorNotIdentified" 0 "NoError" ;
VAL_ 2564357886 Status 7 "Reserved" 6 "Reserved" 5 "OperationFailed" 4 "OperationCompleted" 3 "Reserved" 2 "Reserved" 1 "Busy" 0 "Proceed" ;
VAL_ 2564423422 KeyOrUserLevel 65535 "NoKeyAvailable" 0 "UseLongSeedOrKey" ;
VAL_ 2564423422 PointerExtension 0 "SPN_SPACE" ;
VAL_ 2564423422 Command 7 "EDCP_Generation" 6 "BootLoad" 5 "OperationFailed" 4 "OperationCompleted" 3 "StatusRequest" 2 "Write" 1 "Read" 0 "Erase" ;
VAL_ 2564423422 PointerType 1 "DirectedSpatialAddressing" 0 "DirectMemoryAddressing" ;
VAL_ 2564816638 ProprietaryNetwork2 3 "Don’t Care/take no action" 2 "Reserved" 1 "Start Broadcast" 0 "Stop Broadcast" ;
VAL_ 2564816638 ProprietaryNetwork1 3 "Don’t Care/take no action" 2 "Reserved" 1 "Start Broadcast" 0 "Stop Broadcast" ;
VAL_ 2564816638 J1939Network4 3 "Don’t Care/take no action" 2 "Reserved" 1 "Start Broadcast" 0 "Stop Broadcast" ;
VAL_ 2564816638 HoldSignal 15 "Not Avai l abl e" 1 "Devices whose broadcast state has been modified" 0 "All Devices" ;
VAL_ 2564816638 J1939Network3 3 "Don’t Care/take no action" 2 "Reserved" 1 "Start Broadcast" 0 "Stop Broadcast" ;
VAL_ 2564816638 J1939Network2 3 "Don’t Care/take no action" 2 "Reserved" 1 "Start Broadcast" 0 "Stop Broadcast" ;
VAL_ 2564816638 ISO9141 3 "Don’t Care/take no action" 2 "Reserved" 1 "Start Broadcast" 0 "Stop Broadcast" ;
VAL_ 2564816638 SAE_J1850 3 "Don’t Care/take no action" 2 "Reserved" 1 "Start Broadcast" 0 "Stop Broadcast" ;
VAL_ 2564816638 ManufacturerSpecificPort 2 "Reserved" 1 "Start Broadcast" 0 "Stop Broadcast" 3 "Don’t Care/take no action" ;
VAL_ 2564816638 CurrentDataLink 3 "Don’t Care/take no action" 2 "Reserved" 1 "Start Broadcast" 0 "Stop Broadcast" ;
VAL_ 2564816638 SAE_J1587 3 "Don’t Care/take no action" 2 "Reserved" 1 "Start Broadcast" 0 "Stop Broadcast" ;
VAL_ 2564816638 SAE_J1922 3 "Don’t Care/take no action" 2 "Reserved" 1 "Start Broadcast" 0 "Stop Broadcast" ;
VAL_ 2564816638 J1939Network1 3 "Don’t Care/take no action" 2 "Reserved" 1 "Start Broadcast" 0 "Stop Broadcast" ;
VAL_ 2564816638 SuspendSignal 15 "Not Available" 14 "Resuming normal broadcast pattern" 3 "Temporary suspension of some messages" 2 "Temporary suspension of all broadcasts" 1 "Indefinite suspension of some messages" 0 "Indefinite suspension of all broadcasts" ;
VAL_ 2566837502 FlashRedStopLamp 3 "Unavailable / Do Not Flash" 2 "Reserved" 1 "Fast Flash" 0 "Slow Flash" ;
VAL_ 2566837502 FlashProtectLamp 3 "Unavailable / Do Not Flash" 2 "Reserved" 1 "Fast Flash" 0 "Slow Flash" ;
VAL_ 2566837502 MalfunctionIndicatorLampStatus 3 "Not available" 2 "Short MIL for WWH OBD" 1 "Lamp On" 0 "Lamp Off" ;
VAL_ 2566837502 RedStopLampState 3 "Not available" 2 "Reserved" 1 "Lamp On" 0 "Lamp Off" ;
VAL_ 2566837502 AmberWarningLampStatus 3 "Not available" 2 "Reserved" 1 "Lamp On" 0 "Lamp Off" ;
VAL_ 2566837502 ProtectLampStatus 3 "Not available" 2 "Reserved" 1 "Lamp On" 0 "Lamp Off" ;
VAL_ 2566837502 FlashMalfuncIndicatorLamp 3 "Unavailable / Do Not Flash" 2 "Class C DTC  " 1 "Fast Flash" 0 "Slow Flash" ;
VAL_ 2566837502 FlashAmberWarningLamp 3 "Unavailable / Do Not Flash" 2 "Reserved" 1 "Fast Flash" 0 "Slow Flash" ;
VAL_ 2566834942 FlashRedStopLamp 3 "Unavailable / Do Not Flash" 2 "Reserved" 1 "Fast Flash" 0 "Slow Flash" ;
VAL_ 2566834942 FlashProtectLamp 3 "Unavailable / Do Not Flash" 2 "Reserved" 1 "Fast Flash" 0 "Slow Flash" ;
VAL_ 2566834942 FlashMalfuncIndicatorLamp 3 "Unavailable / Do Not Flash" 2 "Class C DTC  " 1 "Fast Flash" 0 "Slow Flash" ;
VAL_ 2566834942 FlashAmberWarningLamp 3 "Unavailable / Do Not Flash" 2 "Reserved" 1 "Fast Flash" 0 "Slow Flash" ;
VAL_ 2566834942 MalfunctionIndicatorLampStatus 3 "Not available" 2 "Short MIL for WWH OBD" 1 "Lamp On" 0 "Lamp Off" ;
VAL_ 2566834942 AmberWarningLampStatus 3 "Not available" 2 "Reserved" 1 "Lamp On" 0 "Lamp Off" ;
VAL_ 2566834942 RedStopLampState 3 "Not available" 2 "Reserved" 1 "Lamp On" 0 "Lamp Off" ;
VAL_ 2566834942 ProtectLampStatus 3 "Not available" 2 "Reserved" 1 "Lamp On" 0 "Lamp Off" ;
VAL_ 2365454334 UtlityOverallPowerFactorLagging 3 "Not Available or Not Installed" 2 "Error" 1 "Lagging" 0 "Leading" ;
VAL_ 2365452030 UtilityPhaseCPowerFactorLagging 3 "Not Available or Not Installed" 2 "Error" 1 "Lagging" 0 "Leading" ;
